VERSION "synthetic-300"

NS_ :

BS_:

BU_: Node1 Node2 Node3 Node4 Node5 Node6 Node7 Node8 Node9 Node10 Node11 Node12

VAL_TABLE_ State2 1 "On" 0 "Off" ;
VAL_TABLE_ Mode4 3 "Fault" 2 "Hold" 1 "Run" 0 "Idle" ;

BO_ 1 Msg_0: 16 Node1
 SG_ Sig_0_0 : 7|2@0+ (0.01,-40) [-40|-39.97] "" Node2
 SG_ Sig_0_1 : 5|12@0+ (0.1,-0.5) [-0.5|409] "rpm" Node2
 SG_ Sig_0_2 : 9|2@0- (0.5,0) [-1|0.5] "" Node2
 SG_ Sig_0_3 : 23|8@0+ (1,0) [0|255] "A" Node2
 SG_ Sig_0_4 : 31|8@0- (1,0) [-128|127] "" Node2
 SG_ Sig_0_5 : 39|8@0+ (1,0) [0|255] "degC" Node2

BO_ 2147549185 Msg_1: 32 Node2
 SG_ Sig_1_0 : 0|8@1- (1,0) [-128|127] "" Node3,Node4
 SG_ Sig_1_1 : 8|8@1+ (2,-0.5) [-0.5|509.5] "km/h" Node3,Node4
 SG_ Sig_1_2 : 16|1@1+ (1,0) [0|1] "" Node3,Node4
 SG_ Sig_1_3 : 17|12@1- (2,0) [-4096|4094] "km/h" Node3,Node4
 SG_ Sig_1_4 : 29|8@1+ (1,0) [0|255] "" Node3,Node4
 SG_ Sig_1_5 : 37|16@1+ (0.1,0) [0|6553.5] "A" Node3,Node4

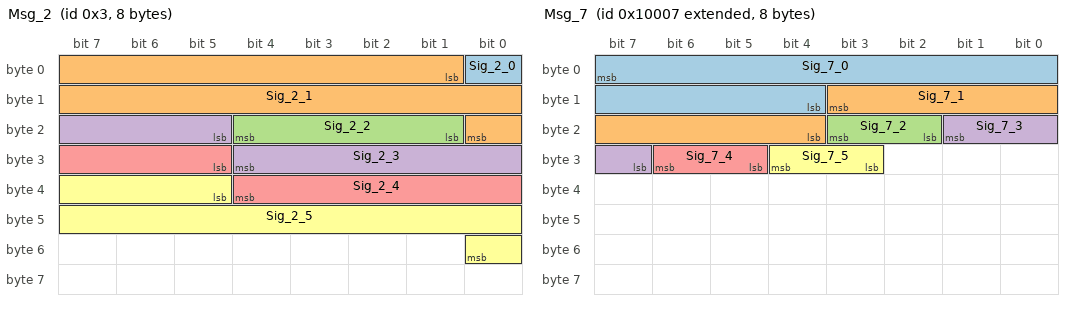
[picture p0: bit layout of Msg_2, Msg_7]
BO_ 3 Msg_2: 8 Node3
 SG_ Sig_2_0 : 0|1@1+ (1,0) [0|1] "" Node4
 SG_ Sig_2_1 : 1|16@1+ (0.25,-0.5) [-0.5|16383.25] "degC" Node4
 SG_ Sig_2_2 : 17|4@1+ (1,-40) [-40|-25] "km/h" Node4
 SG_ Sig_2_3 : 21|8@1+ (1,-40) [-40|215] "A" Node4
 SG_ Sig_2_4 : 29|8@1+ (1,-40) [-40|215] "rpm" Node4
 SG_ Sig_2_5 : 37|12@1+ (0.01,0) [0|40.95] "rpm" Node4

BO_ 4 Msg_3: 32 Node4
 SG_ Sig_3_0 : 7|16@0- (1,-40) [-32808|32727] "V" Node5
 SG_ Sig_3_1 : 23|8@0- (0.01,0) [-1.28|1.27] "" Node5
 SG_ Sig_3_2 : 31|8@0+ (0.01,0) [0|2.55] "%" Node5
 SG_ Sig_3_3 : 39|2@0+ (0.1,-40) [-40|-39.7] "" Node5
 SG_ Sig_3_4 : 37|16@0+ (0.5,-0.5) [-0.5|32767] "km/h" Node5
 SG_ Sig_3_5 : 53|2@0+ (0.25,-0.5) [-0.5|0.25] "" Node5

BO_ 5 Msg_4: 16 Node5
 SG_ Sig_4_0 : 0|12@1+ (0.25,-0.5) [-0.5|1023.25] "V" Node6,Node7
 SG_ Sig_4_1 : 12|3@1+ (0.1,0) [0|0.7] "rpm" Node6,Node7
 SG_ Sig_4_2 : 15|1@1+ (1,0) [0|1] "" Node6,Node7
 SG_ Sig_4_3 : 16|16@1- (0.5,0) [-16384|16383.5] "" Node6,Node7
 SG_ Sig_4_4 : 32|4@1+ (0.25,-0.5) [-0.5|3.25] "A" Node6,Node7
 SG_ Sig_4_5 : 36|8@1+ (0.01,0) [0|2.55] "rpm" Node6,Node7

BO_ 2147549189 Msg_5: 24 Node6
 SG_ Sig_5_0 : 0|1@1+ (1,0) [0|1] "" Node7,Node8
 SG_ Sig_5_1 : 1|16@1+ (0.1,-0.5) [-0.5|6553] "A" Node7,Node8
 SG_ Sig_5_2 : 17|2@1- (1,-40) [-42|-39] "" Node7,Node8
 SG_ Sig_5_3 : 19|8@1+ (0.5,100) [100|227.5] "" Node7,Node8
 SG_ Sig_5_4 : 27|8@1+ (2,-0.5) [-0.5|509.5] "degC" Node7,Node8
 SG_ Sig_5_5 : 35|4@1- (1,100) [92|107] "%" Node7,Node8

BO_ 7 Msg_6: 6 Node7
 SG_ Sig_6_0 : 0|8@1+ (2,0) [0|510] "km/h" Node8
 SG_ Sig_6_1 : 8|8@1+ (2,0) [0|510] "V" Node8
 SG_ Sig_6_2 : 16|16@1+ (1,0) [0|65535] "V" Node8
 SG_ Sig_6_3 : 32|2@1+ (2,0) [0|6] "" Node8
 SG_ Sig_6_4 : 34|8@1- (1,0) [-128|127] "degC" Node8
 SG_ Sig_6_5 : 42|1@1+ (1,0) [0|1] "" Node8

BO_ 2147549191 Msg_7: 8 Node8
 SG_ Sig_7_0 : 7|12@0+ (0.25,-40) [-40|983.75] "" Node9
 SG_ Sig_7_1 : 11|8@0+ (1,0) [0|255] "km/h" Node9
 SG_ Sig_7_2 : 19|2@0- (1,-40) [-42|-39] "" Node9
 SG_ Sig_7_3 : 17|3@0+ (0.01,0) [0|0.07] "V" Node9
 SG_ Sig_7_4 : 30|2@0+ (1,0) [0|3] "" Node9
 SG_ Sig_7_5 : 28|2@0+ (1,0) [0|3] "" Node9

BO_ 2147549192 Msg_8: 4 Node9
 SG_ Sig_8_0 : 7|16@0+ (0.1,100) [100|6653.5] "rpm" Node10
 SG_ Sig_8_1 : 23|4@0+ (1,0) [0|15] "km/h" Node10
 SG_ Sig_8_2 : 19|3@0+ (0.5,0) [0|3.5] "degC" Node10
 SG_ Sig_8_3 : 16|4@0+ (0.25,0) [0|3.75] "%" Node10
 SG_ Sig_8_4 : 28|5@0- (1,-0.5) [-16.5|14.5] "A" Node10

BO_ 2147549193 Msg_9: 12 Node10
 SG_ Sig_9_0 : 7|16@0+ (0.25,-0.5) [-0.5|16383.25] "rpm" Node11
 SG_ Sig_9_1 : 23|8@0+ (0.01,0) [0|2.55] "km/h" Node11
 SG_ Sig_9_2 : 31|12@0+ (1,0) [0|4095] "V" Node11
 SG_ Sig_9_3 : 35|3@0+ (2,-40) [-40|-26] "%" Node11
 SG_ Sig_9_4 : 32|12@0+ (0.1,0) [0|409.5] "" Node11
 SG_ Sig_9_5 : 52|16@0+ (0.1,100) [100|6653.5] "km/h" Node11

BO_ 11 Msg_10: 24 Node11
 SG_ Sig_10_0 : 7|1@0+ (1,0) [0|1] "" Node12
 SG_ Sig_10_1 : 6|2@0+ (1,0) [0|3] "" Node12
 SG_ Sig_10_2 : 4|8@0+ (0.5,-40) [-40|87.5] "km/h" Node12
 SG_ Sig_10_3 : 12|12@0+ (1,0) [0|4095] "degC" Node12
 SG_ Sig_10_4 : 16|1@0+ (1,0) [0|1] "" Node12
 SG_ Sig_10_5 : 31|8@0+ (0.25,100) [100|163.75] "A" Node12

BO_ 12 Msg_11: 12 Node12
 SG_ Sig_11_0 : 7|8@0+ (0.25,-40) [-40|23.75] "V" Node1,Node2
 SG_ Sig_11_1 : 15|12@0+ (0.1,-0.5) [-0.5|409] "" Node1,Node2
 SG_ Sig_11_2 : 19|4@0- (0.1,100) [99.2|100.7] "degC" Node1,Node2
 SG_ Sig_11_3 : 31|2@0+ (1,100) [100|103] "" Node1,Node2
 SG_ Sig_11_4 : 29|12@0+ (1,-40) [-40|4055] "V" Node1,Node2
 SG_ Sig_11_5 : 33|12@0+ (0.1,100) [100|509.5] "%" Node1,Node2

BO_ 13 Msg_12: 6 Node1
 SG_ Sig_12_0 : 7|16@0+ (0.1,0) [0|6553.5] "%" Node2,Node3
 SG_ Sig_12_1 : 23|16@0- (2,0) [-65536|65534] "rpm" Node2,Node3
 SG_ Sig_12_2 : 39|3@0- (1,0) [-4|3] "km/h" Node2,Node3
 SG_ Sig_12_3 : 36|13@0- (0.1,-40) [-449.6|369.5] "rpm" Node2,Node3

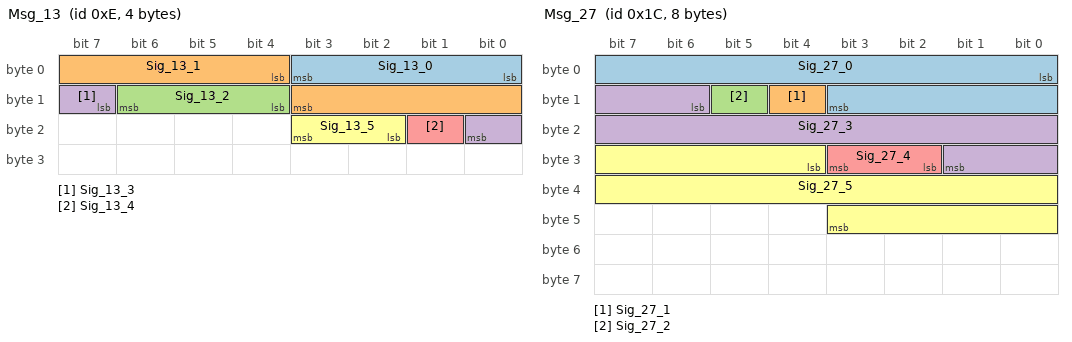
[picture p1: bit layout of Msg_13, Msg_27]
BO_ 14 Msg_13: 4 Node2
 SG_ Sig_13_0 : 0|4@1- (1,100) [92|107] "%" Node3,Node4
 SG_ Sig_13_1 : 4|8@1- (1,-0.5) [-128.5|126.5] "degC" Node3,Node4
 SG_ Sig_13_2 : 12|3@1+ (1,100) [100|107] "rpm" Node3,Node4
 SG_ Sig_13_3 : 15|2@1+ (0.1,0) [0|0.3] "" Node3,Node4
 SG_ Sig_13_4 : 17|1@1+ (1,0) [0|1] "" Node3,Node4
 SG_ Sig_13_5 : 18|2@1+ (0.1,-40) [-40|-39.7] "" Node3,Node4

BO_ 15 Msg_14: 2 Node3
 SG_ Sig_14_0 : 0|4@1+ (2,100) [100|130] "%" Node4,Node5
 SG_ Sig_14_1 : 4|2@1+ (0.01,-40) [-40|-39.97] "" Node4,Node5
 SG_ Sig_14_2 : 6|3@1+ (1,0) [0|7] "" Node4,Node5
 SG_ Sig_14_3 : 9|4@1- (0.25,0) [-2|1.75] "" Node4,Node5
 SG_ Sig_14_4 : 13|3@1+ (0.1,0) [0|0.7] "km/h" Node4,Node5

BO_ 16 Msg_15: 24 Node4
 SG_ Sig_15_0 : 7|1@0+ (1,0) [0|1] "" Node5
 SG_ Sig_15_1 : 6|1@0+ (1,0) [0|1] "" Node5
 SG_ Sig_15_2 : 5|2@0+ (0.01,0) [0|0.03] "" Node5
 SG_ Sig_15_3 : 3|4@0+ (0.01,-40) [-40|-39.85] "" Node5
 SG_ Sig_15_4 : 15|3@0+ (0.01,-40) [-40|-39.93] "" Node5
 SG_ Sig_15_5 : 12|16@0+ (0.25,-0.5) [-0.5|16383.25] "rpm" Node5

BO_ 17 Msg_16: 8 Node5
 SG_ Sig_16_0 : 0|4@1+ (0.5,0) [0|7.5] "A" Node6
 SG_ Sig_16_1 : 4|4@1- (1,0) [-8|7] "degC" Node6
 SG_ Sig_16_2 : 8|8@1- (0.5,-40) [-104|23.5] "%" Node6
 SG_ Sig_16_3 : 16|2@1- (2,0) [-4|2] "" Node6
 SG_ Sig_16_4 : 18|2@1+ (0.1,0) [0|0.3] "" Node6
 SG_ Sig_16_5 : 20|12@1+ (0.01,0) [0|40.95] "" Node6

BO_ 18 Msg_17: 8 Node6
 SG_ Sig_17_0 : 7|2@0+ (0.5,-40) [-40|-38.5] "" Node7
 SG_ Sig_17_1 : 5|4@0+ (0.25,0) [0|3.75] "" Node7
 SG_ Sig_17_2 : 1|8@0+ (0.01,0) [0|2.55] "km/h" Node7
 SG_ Sig_17_3 : 9|2@0+ (1,0) [0|3] "" Node7
 SG_ Sig_17_4 : 23|16@0+ (0.1,-0.5) [-0.5|6553] "rpm" Node7
 SG_ Sig_17_5 : 39|16@0- (0.25,0) [-8192|8191.75] "degC" Node7

BO_ 2147549202 Msg_18: 16 Node7
 SG_ Sig_18_0 : 0|1@1+ (1,0) [0|1] "" Node8,Node9
 SG_ Sig_18_1 : 1|1@1+ (1,0) [0|1] "" Node8,Node9
 SG_ Sig_18_2 : 2|8@1- (0.25,100) [68|131.75] "A" Node8,Node9
 SG_ Sig_18_3 : 10|12@1+ (2,-0.5) [-0.5|8189.5] "%" Node8,Node9
 SG_ Sig_18_4 : 22|8@1+ (2,0) [0|510] "V" Node8,Node9
 SG_ Sig_18_5 : 30|2@1- (0.1,0) [-0.2|0.1] "" Node8,Node9

BO_ 20 Msg_19: 8 Node8
 SG_ Sig_19_0 : 7|8@0+ (1,-40) [-40|215] "degC" Node9,Node10
 SG_ Sig_19_1 : 15|8@0+ (2,0) [0|510] "%" Node9,Node10
 SG_ Sig_19_2 : 23|4@0+ (0.25,100) [100|103.75] "A" Node9,Node10
 SG_ Sig_19_3 : 19|1@0+ (1,0) [0|1] "" Node9,Node10
 SG_ Sig_19_4 : 18|8@0- (2,100) [-156|354] "%" Node9,Node10
 SG_ Sig_19_5 : 26|2@0+ (0.5,0) [0|1.5] "" Node9,Node10

BO_ 21 Msg_20: 12 Node9
 SG_ Sig_20_0 : 7|4@0+ (0.25,100) [100|103.75] "degC" Node10
 SG_ Sig_20_1 : 3|8@0+ (0.01,0) [0|2.55] "A" Node10
 SG_ Sig_20_2 : 11|8@0+ (0.5,-0.5) [-0.5|127] "rpm" Node10
 SG_ Sig_20_3 : 19|2@0+ (0.01,100) [100|100.03] "" Node10
 SG_ Sig_20_4 : 17|4@0- (0.5,100) [96|103.5] "degC" Node10
 SG_ Sig_20_5 : 29|12@0+ (2,-0.5) [-0.5|8189.5] "A" Node10

BO_ 22 Msg_21: 32 Node10
 SG_ Sig_21_0 : 7|8@0+ (0.01,0) [0|2.55] "" Node11
 SG_ Sig_21_1 : 15|3@0+ (0.1,0) [0|0.7] "degC" Node11
 SG_ Sig_21_2 : 12|12@0+ (0.1,-40) [-40|369.5] "km/h" Node11
 SG_ Sig_21_3 : 16|8@0+ (0.5,100) [100|227.5] "V" Node11
 SG_ Sig_21_4 : 24|8@0+ (1,0) [0|255] "%" Node11
 SG_ Sig_21_5 : 32|3@0+ (0.01,-40) [-40|-39.93] "V" Node11

BO_ 23 Msg_22: 32 Node11
 SG_ Sig_22_0 : 0|16@1+ (0.1,0) [0|6553.5] "" Node12
 SG_ Sig_22_1 : 16|16@1+ (2,0) [0|131070] "%" Node12
 SG_ Sig_22_2 : 32|8@1+ (0.25,0) [0|63.75] "" Node12
 SG_ Sig_22_3 : 40|2@1+ (2,0) [0|6] "" Node12
 SG_ Sig_22_4 : 42|3@1- (0.01,-0.5) [-0.54|-0.47] "A" Node12
 SG_ Sig_22_5 : 45|1@1+ (1,0) [0|1] "" Node12

BO_ 2147549207 Msg_23: 4 Node12
 SG_ Sig_23_0 : 7|16@0+ (0.01,0) [0|655.35] "km/h" Node1
 SG_ Sig_23_1 : 23|4@0+ (1,0) [0|15] "km/h" Node1
 SG_ Sig_23_2 : 19|12@0- (0.1,0) [-204.8|204.7] "%" Node1

BO_ 25 Msg_24: 8 Node1
 SG_ Sig_24_0 : 0|1@1+ (1,0) [0|1] "" Node2,Node3
 SG_ Sig_24_1 : 1|3@1- (0.5,0) [-2|1.5] "V" Node2,Node3
 SG_ Sig_24_2 : 4|3@1+ (0.5,-40) [-40|-36.5] "A" Node2,Node3
 SG_ Sig_24_3 : 7|8@1- (2,-0.5) [-256.5|253.5] "A" Node2,Node3
 SG_ Sig_24_4 : 15|1@1+ (1,0) [0|1] "" Node2,Node3
 SG_ Sig_24_5 : 16|8@1+ (0.1,0) [0|25.5] "A" Node2,Node3

BO_ 26 Msg_25: 64 Node2
 SG_ Sig_25_0 : 7|3@0+ (0.25,-40) [-40|-38.25] "km/h" Node3
 SG_ Sig_25_1 : 4|12@0- (1,0) [-2048|2047] "V" Node3
 SG_ Sig_25_2 : 8|16@0+ (0.01,0) [0|655.35] "%" Node3
 SG_ Sig_25_3 : 24|16@0+ (1,-40) [-40|65495] "degC" Node3
 SG_ Sig_25_4 : 40|1@0+ (1,0) [0|1] "" Node3
 SG_ Sig_25_5 : 55|2@0- (0.25,0) [-0.5|0.25] "" Node3

BO_ 27 Msg_26: 16 Node3
 SG_ Sig_26_sel M : 0|8@1- (0.25,-0.5) [-32.5|31.25] "km/h" Node4
 SG_ Sig_26_a0 m0 : 8|12@1+ (0.1,-40) [-40|369.5] "" Node4
 SG_ Sig_26_a1 m0 : 20|12@1+ (0.25,-0.5) [-0.5|1023.25] "A" Node4
 SG_ Sig_26_b0 m1 : 8|8@1+ (0.5,-40) [-40|87.5] "A" Node4
 SG_ Sig_26_b1 m1 : 16|12@1- (0.5,0) [-1024|1023.5] "A" Node4
 SG_ Sig_26_c0 : 40|4@1- (1,-40) [-48|-33] "" Node4
 SG_ Sig_26_c1 : 44|8@1- (1,0) [-128|127] "rpm" Node4

BO_ 28 Msg_27: 8 Node4
 SG_ Sig_27_0 : 0|12@1+ (0.25,0) [0|1023.75] "A" Node5
 SG_ Sig_27_1 : 12|1@1+ (1,0) [0|1] "" Node5
 SG_ Sig_27_2 : 13|1@1+ (1,0) [0|1] "" Node5
 SG_ Sig_27_3 : 14|12@1+ (0.5,0) [0|2047.5] "A" Node5
 SG_ Sig_27_4 : 26|2@1+ (2,-0.5) [-0.5|5.5] "" Node5
 SG_ Sig_27_5 : 28|16@1+ (1,0) [0|65535] "km/h" Node5

BO_ 29 Msg_28: 24 Node5
 SG_ Sig_28_0 : 7|16@0+ (0.01,-0.5) [-0.5|654.85] "" Node6,Node7
 SG_ Sig_28_1 : 23|2@0+ (1,0) [0|3] "" Node6,Node7
 SG_ Sig_28_2 : 21|3@0+ (0.5,0) [0|3.5] "%" Node6,Node7
 SG_ Sig_28_3 : 18|3@0+ (0.5,0) [0|3.5] "rpm" Node6,Node7
 SG_ Sig_28_4 : 31|2@0+ (0.5,-0.5) [-0.5|1] "" Node6,Node7
 SG_ Sig_28_5 : 29|1@0+ (1,0) [0|1] "" Node6,Node7

BO_ 30 Msg_29: 12 Node6
 SG_ Sig_29_0 : 7|16@0+ (0.5,0) [0|32767.5] "rpm" Node7
 SG_ Sig_29_1 : 23|8@0+ (0.01,0) [0|2.55] "rpm" Node7
 SG_ Sig_29_2 : 31|2@0+ (0.25,0) [0|0.75] "" Node7
 SG_ Sig_29_3 : 29|8@0- (1,0) [-128|127] "rpm" Node7
 SG_ Sig_29_4 : 37|4@0+ (1,100) [100|115] "" Node7
 SG_ Sig_29_5 : 33|12@0+ (0.1,0) [0|409.5] "km/h" Node7

BO_ 31 Msg_30: 6 Node7
 SG_ Sig_30_0 : 0|2@1+ (0.01,0) [0|0.03] "" Node8,Node9
 SG_ Sig_30_1 : 2|4@1+ (0.5,-40) [-40|-32.5] "V" Node8,Node9
 SG_ Sig_30_2 : 6|2@1+ (0.25,0) [0|0.75] "" Node8,Node9
 SG_ Sig_30_3 : 8|8@1+ (0.25,0) [0|63.75] "rpm" Node8,Node9
 SG_ Sig_30_4 : 16|8@1- (0.01,0) [-1.28|1.27] "km/h" Node8,Node9
 SG_ Sig_30_5 : 24|8@1+ (2,0) [0|510] "rpm" Node8,Node9

BO_ 32 Msg_31: 4 Node8
 SG_ Sig_31_0 : 7|3@0+ (0.01,100) [100|100.07] "km/h" Node9,Node10
 SG_ Sig_31_1 : 4|16@0+ (0.25,-0.5) [-0.5|16383.25] "rpm" Node9,Node10
 SG_ Sig_31_2 : 20|12@0+ (0.25,-40) [-40|983.75] "" Node9,Node10
 SG_ Sig_31_3 : 24|1@0+ (1,0) [0|1] "" Node9,Node10

BO_ 33 Msg_32: 32 Node9
 SG_ Sig_32_0 : 0|4@1- (1,-0.5) [-8.5|6.5] "km/h" Node10
 SG_ Sig_32_1 : 4|2@1+ (0.01,-40) [-40|-39.97] "" Node10
 SG_ Sig_32_2 : 6|12@1+ (1,100) [100|4195] "V" Node10
 SG_ Sig_32_3 : 18|1@1+ (1,0) [0|1] "" Node10
 SG_ Sig_32_4 : 19|1@1+ (1,0) [0|1] "" Node10
 SG_ Sig_32_5 : 20|8@1+ (0.5,0) [0|127.5] "rpm" Node10

BO_ 34 Msg_33: 8 Node10
 SG_ Sig_33_0 : 7|16@0+ (2,0) [0|131070] "V" Node11
 SG_ Sig_33_1 : 23|3@0- (0.5,-0.5) [-2.5|1] "A" Node11
 SG_ Sig_33_2 : 20|8@0- (0.01,0) [-1.28|1.27] "A" Node11
 SG_ Sig_33_3 : 28|16@0+ (0.5,0) [0|32767.5] "A" Node11
 SG_ Sig_33_4 : 44|2@0+ (2,0) [0|6] "" Node11
 SG_ Sig_33_5 : 42|8@0- (2,0) [-256|254] "degC" Node11

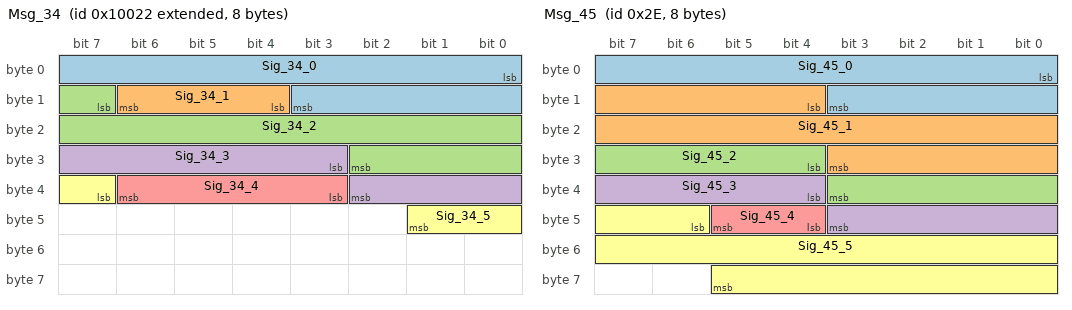
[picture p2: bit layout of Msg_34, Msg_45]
BO_ 2147549218 Msg_34: 8 Node11
 SG_ Sig_34_0 : 0|12@1- (1,-40) [-2088|2007] "degC" Node12,Node1
 SG_ Sig_34_1 : 12|3@1+ (0.01,-40) [-40|-39.93] "%" Node12,Node1
 SG_ Sig_34_2 : 15|12@1+ (0.01,0) [0|40.95] "A" Node12,Node1
 SG_ Sig_34_3 : 27|8@1+ (2,0) [0|510] "A" Node12,Node1
 SG_ Sig_34_4 : 35|4@1+ (2,-40) [-40|-10] "%" Node12,Node1
 SG_ Sig_34_5 : 39|3@1+ (0.1,-40) [-40|-39.3] "%" Node12,Node1

BO_ 36 Msg_35: 8 Node12
 SG_ Sig_35_0 : 7|8@0+ (1,100) [100|355] "degC" Node1
 SG_ Sig_35_1 : 15|8@0- (0.1,0) [-12.8|12.7] "degC" Node1
 SG_ Sig_35_2 : 23|3@0+ (2,0) [0|14] "" Node1
 SG_ Sig_35_3 : 20|8@0+ (0.25,-0.5) [-0.5|63.25] "A" Node1
 SG_ Sig_35_4 : 28|12@0+ (1,0) [0|4095] "A" Node1
 SG_ Sig_35_5 : 32|12@0- (0.25,0) [-512|511.75] "A" Node1

BO_ 37 Msg_36: 64 Node1
 SG_ Sig_36_0 : 7|8@0+ (1,0) [0|255] "A" Node2
 SG_ Sig_36_1 : 15|8@0+ (2,-0.5) [-0.5|509.5] "A" Node2
 SG_ Sig_36_2 : 23|1@0+ (1,0) [0|1] "" Node2
 SG_ Sig_36_3 : 22|8@0+ (2,0) [0|510] "" Node2
 SG_ Sig_36_4 : 30|2@0+ (1,0) [0|3] "" Node2
 SG_ Sig_36_5 : 28|12@0+ (0.1,0) [0|409.5] "" Node2

BO_ 38 Msg_37: 24 Node2
 SG_ Sig_37_0 : 0|12@1+ (0.1,0) [0|409.5] "A" Node3,Node4
 SG_ Sig_37_1 : 12|4@1- (0.5,100) [96|103.5] "%" Node3,Node4
 SG_ Sig_37_2 : 16|2@1- (1,0) [-2|1] "" Node3,Node4
 SG_ Sig_37_3 : 18|2@1- (0.1,0) [-0.2|0.1] "" Node3,Node4
 SG_ Sig_37_4 : 20|1@1+ (1,0) [0|1] "" Node3,Node4
 SG_ Sig_37_5 : 21|3@1- (1,0) [-4|3] "degC" Node3,Node4

BO_ 39 Msg_38: 24 Node3
 SG_ Sig_38_sel M : 0|8@1- (0.1,100) [87.2|112.7] "" Node4
 SG_ Sig_38_a0 m0 : 8|1@1+ (1,0) [0|1] "" Node4
 SG_ Sig_38_a1 m0 : 9|12@1+ (1,0) [0|4095] "rpm" Node4
 SG_ Sig_38_b0 m1 : 8|3@1+ (0.1,0) [0|0.7] "rpm" Node4
 SG_ Sig_38_b1 m1 : 11|4@1- (2,0) [-16|14] "rpm" Node4
 SG_ Sig_38_c0 : 40|2@1+ (0.5,-40) [-40|-38.5] "" Node4
 SG_ Sig_38_c1 : 42|2@1+ (0.01,0) [0|0.03] "" Node4

BO_ 40 Msg_39: 4 Node4
 SG_ Sig_39_0 : 7|8@0+ (2,-40) [-40|470] "km/h" Node5
 SG_ Sig_39_1 : 15|2@0+ (0.01,-40) [-40|-39.97] "" Node5
 SG_ Sig_39_2 : 13|2@0+ (0.25,100) [100|100.75] "" Node5
 SG_ Sig_39_3 : 11|8@0+ (2,0) [0|510] "A" Node5
 SG_ Sig_39_4 : 19|2@0+ (0.25,0) [0|0.75] "" Node5
 SG_ Sig_39_5 : 17|10@0+ (0.01,0) [0|10.23] "km/h" Node5

BO_ 41 Msg_40: 16 Node5
 SG_ Sig_40_0 : 0|3@1+ (1,-40) [-40|-33] "degC" Node6
 SG_ Sig_40_1 : 3|12@1+ (0.25,0) [0|1023.75] "%" Node6
 SG_ Sig_40_2 : 15|8@1+ (1,100) [100|355] "A" Node6
 SG_ Sig_40_3 : 23|1@1+ (1,0) [0|1] "" Node6
 SG_ Sig_40_4 : 24|4@1+ (2,0) [0|30] "V" Node6
 SG_ Sig_40_5 : 28|3@1+ (0.5,0) [0|3.5] "degC" Node6

BO_ 2147549225 Msg_41: 32 Node6
 SG_ Sig_41_0 : 7|4@0- (0.5,0) [-4|3.5] "km/h" Node7,Node8
 SG_ Sig_41_1 : 3|1@0+ (1,0) [0|1] "" Node7,Node8
 SG_ Sig_41_2 : 2|3@0+ (1,0) [0|7] "V" Node7,Node8
 SG_ Sig_41_3 : 15|8@0- (1,0) [-128|127] "rpm" Node7,Node8
 SG_ Sig_41_4 : 23|4@0+ (0.1,0) [0|1.5] "%" Node7,Node8
 SG_ Sig_41_5 : 19|12@0+ (0.01,0) [0|40.95] "rpm" Node7,Node8

BO_ 43 Msg_42: 6 Node7
 SG_ Sig_42_0 : 0|16@1+ (0.1,0) [0|6553.5] "km/h" Node8
 SG_ Sig_42_1 : 16|16@1- (0.5,100) [-16284|16483.5] "" Node8
 SG_ Sig_42_2 : 32|12@1+ (0.25,0) [0|1023.75] "rpm" Node8
 SG_ Sig_42_3 : 44|4@1- (0.01,-0.5) [-0.58|-0.43] "rpm" Node8

BO_ 44 Msg_43: 64 Node8
 SG_ Sig_43_0 : 0|3@1- (0.5,0) [-2|1.5] "rpm" Node9
 SG_ Sig_43_1 : 3|8@1+ (1,0) [0|255] "" Node9
 SG_ Sig_43_2 : 11|4@1- (2,-0.5) [-16.5|13.5] "degC" Node9
 SG_ Sig_43_3 : 15|16@1+ (2,0) [0|131070] "V" Node9
 SG_ Sig_43_4 : 31|8@1+ (0.25,0) [0|63.75] "km/h" Node9
 SG_ Sig_43_5 : 39|4@1- (1,-0.5) [-8.5|6.5] "km/h" Node9

BO_ 2147549228 Msg_44: 64 Node9
 SG_ Sig_44_0 : 7|8@0+ (1,0) [0|255] "V" Node10
 SG_ Sig_44_1 : 15|12@0+ (1,0) [0|4095] "A" Node10
 SG_ Sig_44_2 : 19|8@0+ (0.25,0) [0|63.75] "degC" Node10
 SG_ Sig_44_3 : 27|12@0+ (0.01,-40) [-40|0.95] "degC" Node10
 SG_ Sig_44_4 : 47|12@0- (1,-40) [-2088|2007] "A" Node10
 SG_ Sig_44_5 : 51|2@0+ (0.5,-40) [-40|-38.5] "" Node10

BO_ 46 Msg_45: 8 Node10
 SG_ Sig_45_0 : 0|12@1+ (0.5,0) [0|2047.5] "degC" Node11
 SG_ Sig_45_1 : 12|16@1+ (0.01,0) [0|655.35] "" Node11
 SG_ Sig_45_2 : 28|8@1+ (1,-40) [-40|215] "%" Node11
 SG_ Sig_45_3 : 36|8@1+ (1,-40) [-40|215] "rpm" Node11
 SG_ Sig_45_4 : 44|2@1+ (0.01,0) [0|0.03] "" Node11
 SG_ Sig_45_5 : 46|16@1+ (2,0) [0|131070] "degC" Node11

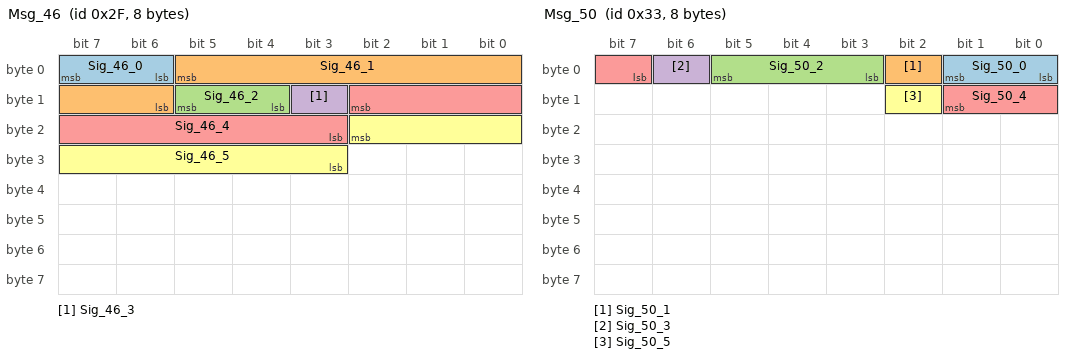
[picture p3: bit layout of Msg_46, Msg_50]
BO_ 47 Msg_46: 8 Node11
 SG_ Sig_46_0 : 7|2@0- (0.5,0) [-1|0.5] "" Node12
 SG_ Sig_46_1 : 5|8@0+ (0.01,-40) [-40|-37.45] "A" Node12
 SG_ Sig_46_2 : 13|2@0+ (0.5,0) [0|1.5] "" Node12
 SG_ Sig_46_3 : 11|1@0+ (1,0) [0|1] "" Node12
 SG_ Sig_46_4 : 10|8@0+ (0.1,0) [0|25.5] "degC" Node12
 SG_ Sig_46_5 : 18|8@0- (0.1,-0.5) [-13.3|12.2] "km/h" Node12

BO_ 2147549231 Msg_47: 12 Node12
 SG_ Sig_47_0 : 7|2@0- (1,0) [-2|1] "" Node1,Node2
 SG_ Sig_47_1 : 5|4@0+ (1,-0.5) [-0.5|14.5] "A" Node1,Node2
 SG_ Sig_47_2 : 1|12@0+ (1,100) [100|4195] "%" Node1,Node2
 SG_ Sig_47_3 : 21|16@0+ (0.1,100) [100|6653.5] "" Node1,Node2
 SG_ Sig_47_4 : 37|16@0+ (1,0) [0|65535] "rpm" Node1,Node2
 SG_ Sig_47_5 : 53|2@0+ (2,0) [0|6] "" Node1,Node2

BO_ 49 Msg_48: 16 Node1
 SG_ Sig_48_sel M : 0|8@1+ (0.01,0) [0|2.55] "rpm" Node2
 SG_ Sig_48_a0 m0 : 8|8@1+ (0.01,100) [100|102.55] "V" Node2
 SG_ Sig_48_a1 m0 : 16|2@1+ (0.5,100) [100|101.5] "" Node2
 SG_ Sig_48_b0 m1 : 8|12@1+ (0.01,0) [0|40.95] "%" Node2
 SG_ Sig_48_b1 m1 : 20|8@1+ (1,0) [0|255] "" Node2
 SG_ Sig_48_c0 : 40|3@1+ (0.01,-40) [-40|-39.93] "%" Node2
 SG_ Sig_48_c1 : 43|2@1- (0.01,0) [-0.02|0.01] "" Node2

BO_ 50 Msg_49: 8 Node2
 SG_ Sig_49_0 : 0|8@1- (0.25,100) [68|131.75] "A" Node3,Node4
 SG_ Sig_49_1 : 8|8@1+ (1,100) [100|355] "V" Node3,Node4
 SG_ Sig_49_2 : 16|1@1+ (1,0) [0|1] "" Node3,Node4
 SG_ Sig_49_3 : 17|16@1+ (1,-0.5) [-0.5|65534.5] "%" Node3,Node4
 SG_ Sig_49_4 : 33|12@1+ (0.01,100) [100|140.95] "degC" Node3,Node4
 SG_ Sig_49_5 : 45|8@1+ (0.01,0) [0|2.55] "degC" Node3,Node4

BO_ 51 Msg_50: 8 Node3
 SG_ Sig_50_0 : 0|2@1+ (0.1,0) [0|0.3] "" Node4
 SG_ Sig_50_1 : 2|1@1+ (1,0) [0|1] "" Node4
 SG_ Sig_50_2 : 3|3@1+ (0.25,-0.5) [-0.5|1.25] "%" Node4
 SG_ Sig_50_3 : 6|1@1+ (1,0) [0|1] "" Node4
 SG_ Sig_50_4 : 7|3@1+ (2,-40) [-40|-26] "rpm" Node4
 SG_ Sig_50_5 : 10|1@1+ (1,0) [0|1] "" Node4

BO_ 52 Msg_51: 32 Node4
 SG_ Sig_51_0 : 0|8@1- (0.25,-40) [-72|-8.25] "degC" Node5
 SG_ Sig_51_1 : 8|12@1- (0.01,0) [-20.48|20.47] "" Node5
 SG_ Sig_51_2 : 20|2@1+ (2,0) [0|6] "" Node5
 SG_ Sig_51_3 : 22|16@1+ (0.01,0) [0|655.35] "km/h" Node5
 SG_ Sig_51_4 : 38|4@1+ (0.5,-40) [-40|-32.5] "km/h" Node5
 SG_ Sig_51_5 : 42|16@1- (0.5,100) [-16284|16483.5] "" Node5

BO_ 53 Msg_52: 12 Node5
 SG_ Sig_52_0 : 0|8@1+ (0.1,100) [100|125.5] "rpm" Node6,Node7
 SG_ Sig_52_1 : 8|4@1+ (2,-40) [-40|-10] "" Node6,Node7
 SG_ Sig_52_2 : 12|2@1- (0.5,-0.5) [-1.5|0] "" Node6,Node7
 SG_ Sig_52_3 : 14|12@1+ (1,-0.5) [-0.5|4094.5] "A" Node6,Node7
 SG_ Sig_52_4 : 26|8@1+ (0.5,0) [0|127.5] "rpm" Node6,Node7
 SG_ Sig_52_5 : 34|16@1+ (2,0) [0|131070] "" Node6,Node7

BO_ 2147549237 Msg_53: 8 Node6
 SG_ Sig_53_0 : 0|12@1+ (0.1,100) [100|509.5] "rpm" Node7,Node8
 SG_ Sig_53_1 : 12|4@1+ (2,-0.5) [-0.5|29.5] "V" Node7,Node8
 SG_ Sig_53_2 : 16|8@1+ (1,0) [0|255] "" Node7,Node8
 SG_ Sig_53_3 : 24|2@1+ (0.25,-40) [-40|-39.25] "" Node7,Node8
 SG_ Sig_53_4 : 26|3@1+ (0.25,0) [0|1.75] "rpm" Node7,Node8
 SG_ Sig_53_5 : 29|16@1+ (1,0) [0|65535] "rpm" Node7,Node8

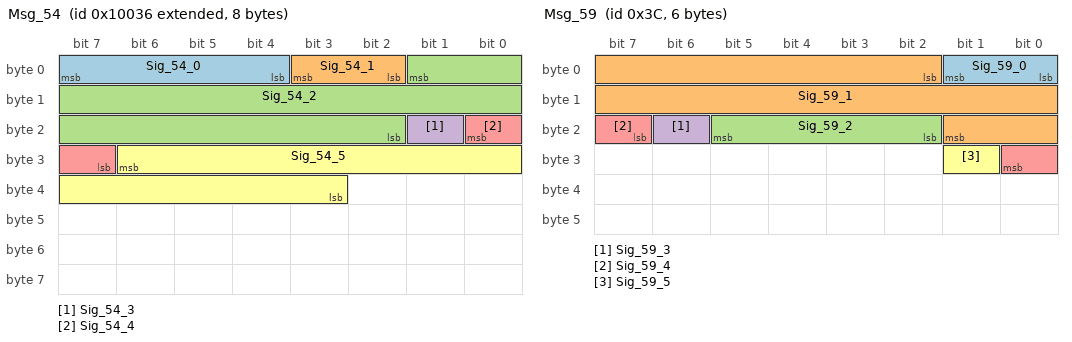
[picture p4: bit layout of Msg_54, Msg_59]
BO_ 2147549238 Msg_54: 8 Node7
 SG_ Sig_54_0 : 7|4@0+ (0.5,100) [100|107.5] "%" Node8
 SG_ Sig_54_1 : 3|2@0- (1,100) [98|101] "" Node8
 SG_ Sig_54_2 : 1|16@0+ (0.25,-0.5) [-0.5|16383.25] "km/h" Node8
 SG_ Sig_54_3 : 17|1@0+ (1,0) [0|1] "" Node8
 SG_ Sig_54_4 : 16|2@0+ (0.1,-0.5) [-0.5|-0.2] "" Node8
 SG_ Sig_54_5 : 30|12@0+ (2,-0.5) [-0.5|8189.5] "" Node8

BO_ 56 Msg_55: 32 Node8
 SG_ Sig_55_0 : 0|3@1+ (0.5,-40) [-40|-36.5] "" Node9,Node10
 SG_ Sig_55_1 : 3|12@1+ (0.01,100) [100|140.95] "A" Node9,Node10
 SG_ Sig_55_2 : 15|8@1- (1,100) [-28|227] "%" Node9,Node10
 SG_ Sig_55_3 : 23|1@1+ (1,0) [0|1] "" Node9,Node10
 SG_ Sig_55_4 : 24|2@1+ (1,100) [100|103] "" Node9,Node10
 SG_ Sig_55_5 : 26|8@1+ (0.01,0) [0|2.55] "" Node9,Node10

BO_ 57 Msg_56: 64 Node9
 SG_ Sig_56_sel M : 0|8@1- (1,0) [-128|127] "A" Node10,Node11
 SG_ Sig_56_a0 m0 : 8|8@1- (2,0) [-256|254] "V" Node10,Node11
 SG_ Sig_56_a1 m0 : 16|8@1+ (0.25,-0.5) [-0.5|63.25] "" Node10,Node11
 SG_ Sig_56_b0 m1 : 8|16@1+ (0.1,0) [0|6553.5] "km/h" Node10,Node11
 SG_ Sig_56_b1 m1 : 24|1@1+ (1,0) [0|1] "" Node10,Node11
 SG_ Sig_56_c0 : 40|2@1+ (0.1,-40) [-40|-39.7] "" Node10,Node11
 SG_ Sig_56_c1 : 42|4@1- (2,0) [-16|14] "A" Node10,Node11

BO_ 58 Msg_57: 16 Node10
 SG_ Sig_57_0 : 7|3@0+ (2,-0.5) [-0.5|13.5] "%" Node11,Node12
 SG_ Sig_57_1 : 4|4@0- (0.1,0) [-0.8|0.7] "degC" Node11,Node12
 SG_ Sig_57_2 : 0|3@0+ (0.25,-40) [-40|-38.25] "rpm" Node11,Node12
 SG_ Sig_57_3 : 13|16@0+ (0.1,-0.5) [-0.5|6553] "km/h" Node11,Node12
 SG_ Sig_57_4 : 29|4@0+ (0.1,0) [0|1.5] "km/h" Node11,Node12
 SG_ Sig_57_5 : 25|2@0- (1,-40) [-42|-39] "" Node11,Node12

BO_ 59 Msg_58: 4 Node11
 SG_ Sig_58_0 : 0|8@1- (0.25,0) [-32|31.75] "V" Node12
 SG_ Sig_58_1 : 8|12@1+ (0.5,0) [0|2047.5] "" Node12
 SG_ Sig_58_2 : 20|12@1- (1,-0.5) [-2048.5|2046.5] "" Node12

BO_ 60 Msg_59: 6 Node12
 SG_ Sig_59_0 : 0|2@1+ (0.01,0) [0|0.03] "" Node1,Node2
 SG_ Sig_59_1 : 2|16@1+ (1,0) [0|65535] "A" Node1,Node2
 SG_ Sig_59_2 : 18|4@1- (0.1,-40) [-40.8|-39.3] "%" Node1,Node2
 SG_ Sig_59_3 : 22|1@1+ (1,0) [0|1] "" Node1,Node2
 SG_ Sig_59_4 : 23|2@1+ (2,0) [0|6] "" Node1,Node2
 SG_ Sig_59_5 : 25|1@1+ (1,0) [0|1] "" Node1,Node2

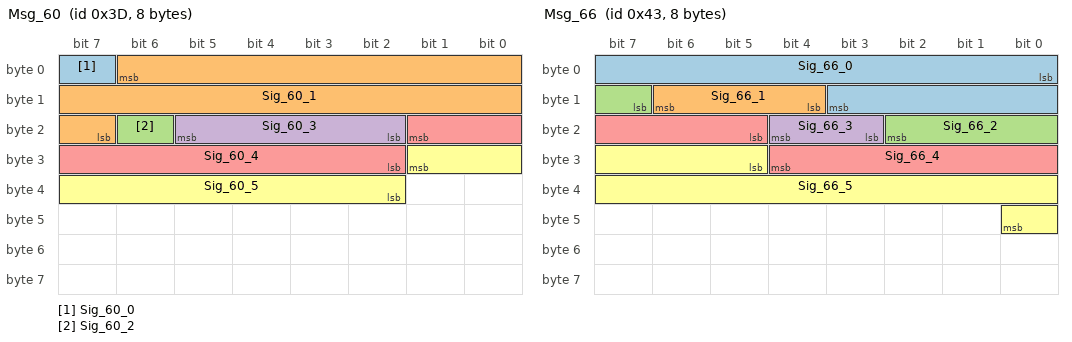
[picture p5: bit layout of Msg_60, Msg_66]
BO_ 61 Msg_60: 8 Node1
 SG_ Sig_60_0 : 7|1@0+ (1,0) [0|1] "" Node2
 SG_ Sig_60_1 : 6|16@0+ (0.25,0) [0|16383.75] "A" Node2
 SG_ Sig_60_2 : 22|1@0+ (1,0) [0|1] "" Node2
 SG_ Sig_60_3 : 21|4@0+ (0.25,0) [0|3.75] "km/h" Node2
 SG_ Sig_60_4 : 17|8@0+ (1,-40) [-40|215] "%" Node2
 SG_ Sig_60_5 : 25|8@0+ (1,0) [0|255] "" Node2

BO_ 62 Msg_61: 8 Node2
 SG_ Sig_61_0 : 0|12@1+ (2,-0.5) [-0.5|8189.5] "V" Node3
 SG_ Sig_61_1 : 12|3@1- (0.01,100) [99.96|100.03] "degC" Node3
 SG_ Sig_61_2 : 15|16@1+ (2,100) [100|131170] "km/h" Node3
 SG_ Sig_61_3 : 31|2@1+ (0.25,100) [100|100.75] "" Node3
 SG_ Sig_61_4 : 33|12@1+ (1,0) [0|4095] "V" Node3
 SG_ Sig_61_5 : 45|16@1- (0.5,0) [-16384|16383.5] "" Node3

BO_ 63 Msg_62: 24 Node3
 SG_ Sig_62_0 : 0|16@1+ (0.5,0) [0|32767.5] "V" Node4
 SG_ Sig_62_1 : 16|16@1+ (0.5,0) [0|32767.5] "%" Node4
 SG_ Sig_62_2 : 32|12@1+ (1,-0.5) [-0.5|4094.5] "A" Node4
 SG_ Sig_62_3 : 44|12@1+ (2,100) [100|8290] "" Node4
 SG_ Sig_62_4 : 56|1@1+ (1,0) [0|1] "" Node4
 SG_ Sig_62_5 : 57|3@1- (0.25,0) [-1|0.75] "A" Node4

BO_ 64 Msg_63: 64 Node4
 SG_ Sig_63_0 : 7|4@0- (1,-0.5) [-8.5|6.5] "V" Node5
 SG_ Sig_63_1 : 3|2@0+ (1,0) [0|3] "" Node5
 SG_ Sig_63_2 : 1|4@0- (0.1,100) [99.2|100.7] "V" Node5
 SG_ Sig_63_3 : 13|8@0- (1,100) [-28|227] "degC" Node5
 SG_ Sig_63_4 : 21|2@0- (1,-0.5) [-2.5|0.5] "" Node5
 SG_ Sig_63_5 : 19|8@0+ (0.25,100) [100|163.75] "rpm" Node5

BO_ 65 Msg_64: 8 Node5
 SG_ Sig_64_0 : 0|12@1+ (1,-0.5) [-0.5|4094.5] "km/h" Node6
 SG_ Sig_64_1 : 12|12@1+ (0.1,0) [0|409.5] "" Node6
 SG_ Sig_64_2 : 24|16@1+ (0.1,0) [0|6553.5] "" Node6
 SG_ Sig_64_3 : 40|3@1+ (1,-0.5) [-0.5|6.5] "rpm" Node6
 SG_ Sig_64_4 : 43|4@1+ (0.1,-40) [-40|-38.5] "V" Node6
 SG_ Sig_64_5 : 47|16@1- (0.25,0) [-8192|8191.75] "rpm" Node6

BO_ 2147549249 Msg_65: 8 Node6
 SG_ Sig_65_0 : 0|8@1+ (0.1,0) [0|25.5] "%" Node7
 SG_ Sig_65_1 : 8|12@1+ (0.25,0) [0|1023.75] "degC" Node7
 SG_ Sig_65_2 : 20|2@1- (0.01,-40) [-40.02|-39.99] "" Node7
 SG_ Sig_65_3 : 22|2@1+ (0.25,-40) [-40|-39.25] "" Node7
 SG_ Sig_65_4 : 24|16@1+ (0.1,-0.5) [-0.5|6553] "degC" Node7
 SG_ Sig_65_5 : 40|4@1- (0.5,-40) [-44|-36.5] "km/h" Node7

BO_ 67 Msg_66: 8 Node7
 SG_ Sig_66_0 : 0|12@1+ (0.5,0) [0|2047.5] "A" Node8
 SG_ Sig_66_1 : 12|3@1+ (0.01,0) [0|0.07] "" Node8
 SG_ Sig_66_2 : 15|4@1- (0.5,0) [-4|3.5] "A" Node8
 SG_ Sig_66_3 : 19|2@1- (2,0) [-4|2] "" Node8
 SG_ Sig_66_4 : 21|8@1+ (1,0) [0|255] "" Node8
 SG_ Sig_66_5 : 29|12@1+ (0.1,100) [100|509.5] "A" Node8

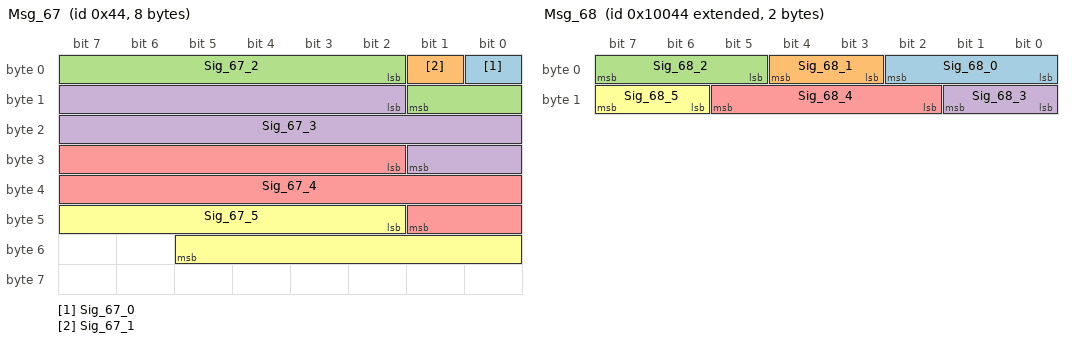
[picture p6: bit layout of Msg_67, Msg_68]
BO_ 68 Msg_67: 8 Node8
 SG_ Sig_67_0 : 0|1@1+ (1,0) [0|1] "" Node9
 SG_ Sig_67_1 : 1|1@1+ (1,0) [0|1] "" Node9
 SG_ Sig_67_2 : 2|8@1+ (1,0) [0|255] "degC" Node9
 SG_ Sig_67_3 : 10|16@1+ (2,0) [0|131070] "A" Node9
 SG_ Sig_67_4 : 26|16@1+ (2,100) [100|131170] "%" Node9
 SG_ Sig_67_5 : 42|12@1+ (0.1,-40) [-40|369.5] "degC" Node9

BO_ 2147549252 Msg_68: 2 Node9
 SG_ Sig_68_0 : 0|3@1+ (0.01,100) [100|100.07] "%" Node10
 SG_ Sig_68_1 : 3|2@1+ (1,0) [0|3] "" Node10
 SG_ Sig_68_2 : 5|3@1- (2,-0.5) [-8.5|5.5] "V" Node10
 SG_ Sig_68_3 : 8|2@1+ (0.01,0) [0|0.03] "" Node10
 SG_ Sig_68_4 : 10|4@1+ (0.01,-0.5) [-0.5|-0.35] "degC" Node10
 SG_ Sig_68_5 : 14|2@1- (1,-40) [-42|-39] "" Node10

BO_ 70 Msg_69: 6 Node10
 SG_ Sig_69_0 : 0|12@1+ (2,0) [0|8190] "V" Node11,Node12
 SG_ Sig_69_1 : 12|8@1+ (0.1,-0.5) [-0.5|25] "km/h" Node11,Node12
 SG_ Sig_69_2 : 20|8@1+ (2,0) [0|510] "km/h" Node11,Node12
 SG_ Sig_69_3 : 28|16@1+ (1,0) [0|65535] "km/h" Node11,Node12
 SG_ Sig_69_4 : 44|4@1+ (0.01,0) [0|0.15] "" Node11,Node12

BO_ 71 Msg_70: 24 Node11
 SG_ Sig_70_0 : 0|8@1- (0.1,0) [-12.8|12.7] "V" Node12
 SG_ Sig_70_1 : 8|2@1+ (0.25,-0.5) [-0.5|0.25] "" Node12
 SG_ Sig_70_2 : 10|8@1+ (0.01,-40) [-40|-37.45] "km/h" Node12
 SG_ Sig_70_3 : 18|16@1- (1,100) [-32668|32867] "A" Node12
 SG_ Sig_70_4 : 34|16@1+ (0.5,-0.5) [-0.5|32767] "degC" Node12
 SG_ Sig_70_5 : 50|2@1- (2,0) [-4|2] "" Node12

BO_ 72 Msg_71: 8 Node12
 SG_ Sig_71_0 : 7|8@0+ (2,0) [0|510] "" Node1,Node2
 SG_ Sig_71_1 : 15|8@0+ (2,100) [100|610] "V" Node1,Node2
 SG_ Sig_71_2 : 23|12@0+ (1,-40) [-40|4055] "degC" Node1,Node2
 SG_ Sig_71_3 : 27|4@0+ (0.25,0) [0|3.75] "degC" Node1,Node2
 SG_ Sig_71_4 : 39|2@0+ (0.01,0) [0|0.03] "" Node1,Node2
 SG_ Sig_71_5 : 37|2@0- (1,100) [98|101] "" Node1,Node2

BO_ 73 Msg_72: 8 Node1
 SG_ Sig_72_0 : 0|4@1+ (0.01,100) [100|100.15] "degC" Node2
 SG_ Sig_72_1 : 4|1@1+ (1,0) [0|1] "" Node2
 SG_ Sig_72_2 : 5|3@1+ (1,-0.5) [-0.5|6.5] "rpm" Node2
 SG_ Sig_72_3 : 8|16@1+ (2,100) [100|131170] "" Node2
 SG_ Sig_72_4 : 24|2@1- (0.5,100) [99|100.5] "" Node2
 SG_ Sig_72_5 : 26|2@1+ (1,0) [0|3] "" Node2

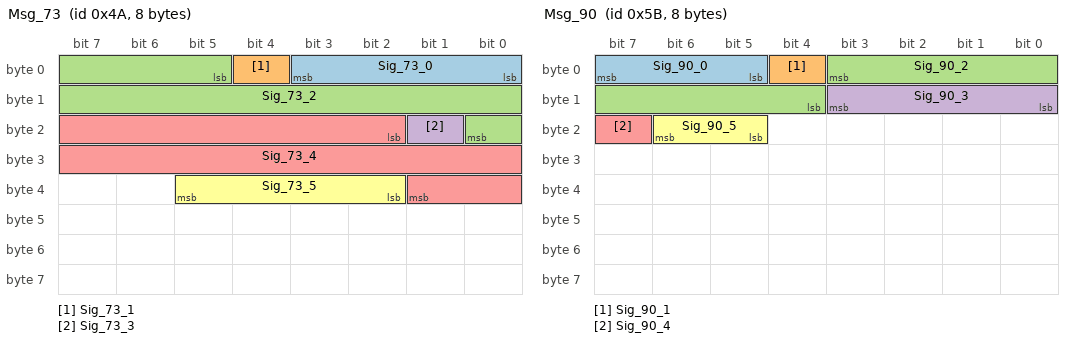
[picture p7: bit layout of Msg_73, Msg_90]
BO_ 74 Msg_73: 8 Node2
 SG_ Sig_73_0 : 0|4@1+ (0.1,0) [0|1.5] "rpm" Node3
 SG_ Sig_73_1 : 4|1@1+ (1,0) [0|1] "" Node3
 SG_ Sig_73_2 : 5|12@1+ (1,-0.5) [-0.5|4094.5] "degC" Node3
 SG_ Sig_73_3 : 17|1@1+ (1,0) [0|1] "" Node3
 SG_ Sig_73_4 : 18|16@1+ (1,0) [0|65535] "%" Node3
 SG_ Sig_73_5 : 34|4@1- (1,0) [-8|7] "V" Node3

BO_ 75 Msg_74: 12 Node3
 SG_ Sig_74_0 : 0|1@1+ (1,0) [0|1] "" Node4
 SG_ Sig_74_1 : 1|3@1+ (0.1,100) [100|100.7] "" Node4
 SG_ Sig_74_2 : 4|3@1- (2,0) [-8|6] "A" Node4
 SG_ Sig_74_3 : 7|8@1+ (0.01,0) [0|2.55] "%" Node4
 SG_ Sig_74_4 : 15|16@1+ (0.25,0) [0|16383.75] "V" Node4
 SG_ Sig_74_5 : 31|2@1+ (0.5,0) [0|1.5] "" Node4

BO_ 76 Msg_75: 2 Node4
 SG_ Sig_75_0 : 0|3@1- (2,100) [92|106] "degC" Node5
 SG_ Sig_75_1 : 3|2@1+ (2,-40) [-40|-34] "" Node5
 SG_ Sig_75_2 : 5|1@1+ (1,0) [0|1] "" Node5
 SG_ Sig_75_3 : 6|8@1- (0.01,-40) [-41.28|-38.73] "km/h" Node5
 SG_ Sig_75_4 : 14|2@1+ (1,0) [0|3] "" Node5

BO_ 77 Msg_76: 24 Node5
 SG_ Sig_76_sel M : 0|8@1+ (0.01,100) [100|102.55] "" Node6
 SG_ Sig_76_a0 m0 : 8|16@1- (1,100) [-32668|32867] "km/h" Node6
 SG_ Sig_76_a1 m0 : 24|8@1+ (2,0) [0|510] "degC" Node6
 SG_ Sig_76_b0 m1 : 8|8@1+ (0.5,0) [0|127.5] "" Node6
 SG_ Sig_76_b1 m1 : 16|1@1+ (1,0) [0|1] "" Node6
 SG_ Sig_76_c0 : 40|16@1+ (0.25,0) [0|16383.75] "" Node6
 SG_ Sig_76_c1 : 56|16@1+ (0.1,100) [100|6653.5] "A" Node6

BO_ 78 Msg_77: 64 Node6
 SG_ Sig_77_0 : 7|8@0+ (0.1,-40) [-40|-14.5] "A" Node7
 SG_ Sig_77_1 : 15|3@0- (0.01,-40) [-40.04|-39.97] "km/h" Node7
 SG_ Sig_77_2 : 12|16@0+ (0.01,-0.5) [-0.5|654.85] "" Node7
 SG_ Sig_77_3 : 28|3@0+ (0.5,-40) [-40|-36.5] "%" Node7
 SG_ Sig_77_4 : 25|8@0+ (0.01,-0.5) [-0.5|2.05] "V" Node7
 SG_ Sig_77_5 : 33|3@0+ (1,-40) [-40|-33] "" Node7

BO_ 79 Msg_78: 32 Node7
 SG_ Sig_78_0 : 0|8@1+ (0.25,0) [0|63.75] "degC" Node8
 SG_ Sig_78_1 : 8|2@1+ (1,-0.5) [-0.5|2.5] "" Node8
 SG_ Sig_78_2 : 10|12@1+ (1,0) [0|4095] "km/h" Node8
 SG_ Sig_78_3 : 22|2@1+ (1,-0.5) [-0.5|2.5] "" Node8
 SG_ Sig_78_4 : 24|8@1- (1,100) [-28|227] "%" Node8
 SG_ Sig_78_5 : 32|3@1+ (0.1,0) [0|0.7] "rpm" Node8

BO_ 2147549263 Msg_79: 8 Node8
 SG_ Sig_79_0 : 0|8@1+ (0.25,0) [0|63.75] "degC" Node9
 SG_ Sig_79_1 : 8|4@1- (2,-40) [-56|-26] "" Node9
 SG_ Sig_79_2 : 12|16@1+ (0.01,-0.5) [-0.5|654.85] "V" Node9
 SG_ Sig_79_3 : 28|4@1+ (2,-0.5) [-0.5|29.5] "V" Node9
 SG_ Sig_79_4 : 32|2@1+ (0.01,-40) [-40|-39.97] "" Node9
 SG_ Sig_79_5 : 34|4@1+ (1,-40) [-40|-25] "V" Node9

BO_ 2147549264 Msg_80: 12 Node9
 SG_ Sig_80_0 : 0|16@1+ (0.01,0) [0|655.35] "km/h" Node10,Node11
 SG_ Sig_80_1 : 16|3@1+ (0.5,0) [0|3.5] "%" Node10,Node11
 SG_ Sig_80_2 : 19|8@1+ (0.25,100) [100|163.75] "%" Node10,Node11
 SG_ Sig_80_3 : 27|1@1+ (1,0) [0|1] "" Node10,Node11
 SG_ Sig_80_4 : 28|4@1- (0.1,0) [-0.8|0.7] "V" Node10,Node11
 SG_ Sig_80_5 : 32|2@1+ (0.1,100) [100|100.3] "" Node10,Node11

BO_ 2147549265 Msg_81: 12 Node10
 SG_ Sig_81_sel M : 0|8@1- (0.5,100) [36|163.5] "rpm" Node11,Node12
 SG_ Sig_81_a0 m0 : 8|3@1+ (2,-0.5) [-0.5|13.5] "km/h" Node11,Node12
 SG_ Sig_81_a1 m0 : 11|16@1+ (1,-0.5) [-0.5|65534.5] "degC" Node11,Node12
 SG_ Sig_81_b0 m1 : 8|1@1+ (1,0) [0|1] "" Node11,Node12
 SG_ Sig_81_b1 m1 : 9|12@1+ (2,-40) [-40|8150] "%" Node11,Node12
 SG_ Sig_81_c0 : 40|16@1+ (1,0) [0|65535] "%" Node11,Node12
 SG_ Sig_81_c1 : 56|16@1+ (1,0) [0|65535] "" Node11,Node12

BO_ 83 Msg_82: 16 Node11
 SG_ Sig_82_0 : 0|1@1+ (1,0) [0|1] "" Node12
 SG_ Sig_82_1 : 1|16@1- (2,0) [-65536|65534] "A" Node12
 SG_ Sig_82_2 : 17|12@1+ (0.25,-40) [-40|983.75] "A" Node12
 SG_ Sig_82_3 : 29|8@1+ (0.25,100) [100|163.75] "V" Node12
 SG_ Sig_82_4 : 37|3@1+ (0.25,0) [0|1.75] "%" Node12
 SG_ Sig_82_5 : 40|8@1- (0.25,100) [68|131.75] "A" Node12

BO_ 84 Msg_83: 8 Node12
 SG_ Sig_83_0 : 7|8@0+ (1,0) [0|255] "V" Node1
 SG_ Sig_83_1 : 15|12@0- (0.5,0) [-1024|1023.5] "" Node1
 SG_ Sig_83_2 : 19|12@0+ (1,0) [0|4095] "degC" Node1
 SG_ Sig_83_3 : 39|8@0+ (1,-40) [-40|215] "km/h" Node1
 SG_ Sig_83_4 : 47|3@0+ (0.25,0) [0|1.75] "" Node1
 SG_ Sig_83_5 : 44|4@0+ (1,-0.5) [-0.5|14.5] "km/h" Node1

BO_ 85 Msg_84: 8 Node1
 SG_ Sig_84_0 : 7|8@0- (2,0) [-256|254] "" Node2
 SG_ Sig_84_1 : 15|2@0- (0.01,0) [-0.02|0.01] "" Node2
 SG_ Sig_84_2 : 13|2@0+ (0.1,-40) [-40|-39.7] "" Node2
 SG_ Sig_84_3 : 11|4@0+ (1,-0.5) [-0.5|14.5] "V" Node2
 SG_ Sig_84_4 : 23|8@0+ (0.01,0) [0|2.55] "A" Node2
 SG_ Sig_84_5 : 31|16@0+ (0.01,-0.5) [-0.5|654.85] "%" Node2

BO_ 86 Msg_85: 16 Node2
 SG_ Sig_85_0 : 7|12@0- (0.5,-40) [-1064|983.5] "V" Node3,Node4
 SG_ Sig_85_1 : 11|3@0+ (0.25,100) [100|101.75] "%" Node3,Node4
 SG_ Sig_85_2 : 8|1@0+ (1,0) [0|1] "" Node3,Node4
 SG_ Sig_85_3 : 23|2@0- (0.5,-0.5) [-1.5|0] "" Node3,Node4
 SG_ Sig_85_4 : 21|4@0- (0.01,100) [99.92|100.07] "km/h" Node3,Node4
 SG_ Sig_85_5 : 17|3@0+ (1,0) [0|7] "%" Node3,Node4

BO_ 87 Msg_86: 6 Node3
 SG_ Sig_86_0 : 0|8@1+ (0.1,-0.5) [-0.5|25] "V" Node4
 SG_ Sig_86_1 : 8|3@1+ (0.01,-0.5) [-0.5|-0.43] "km/h" Node4
 SG_ Sig_86_2 : 11|16@1+ (0.1,0) [0|6553.5] "degC" Node4
 SG_ Sig_86_3 : 27|16@1+ (0.5,0) [0|32767.5] "A" Node4
 SG_ Sig_86_4 : 43|5@1- (0.5,0) [-8|7.5] "" Node4

BO_ 88 Msg_87: 8 Node4
 SG_ Sig_87_0 : 0|16@1+ (1,100) [100|65635] "" Node5,Node6
 SG_ Sig_87_1 : 16|12@1- (2,-40) [-4136|4054] "A" Node5,Node6
 SG_ Sig_87_2 : 28|8@1+ (0.1,-0.5) [-0.5|25] "%" Node5,Node6
 SG_ Sig_87_3 : 36|1@1+ (1,0) [0|1] "" Node5,Node6
 SG_ Sig_87_4 : 37|12@1+ (0.01,100) [100|140.95] "degC" Node5,Node6
 SG_ Sig_87_5 : 49|8@1- (0.25,-40) [-72|-8.25] "rpm" Node5,Node6

BO_ 89 Msg_88: 16 Node5
 SG_ Sig_88_sel M : 0|8@1+ (0.01,0) [0|2.55] "" Node6
 SG_ Sig_88_a0 m0 : 8|8@1+ (2,-40) [-40|470] "A" Node6
 SG_ Sig_88_a1 m0 : 16|2@1+ (0.01,100) [100|100.03] "" Node6
 SG_ Sig_88_b0 m1 : 8|8@1+ (0.01,0) [0|2.55] "degC" Node6
 SG_ Sig_88_b1 m1 : 16|16@1+ (0.5,0) [0|32767.5] "degC" Node6
 SG_ Sig_88_c0 : 40|8@1+ (0.1,0) [0|25.5] "degC" Node6
 SG_ Sig_88_c1 : 48|1@1+ (1,0) [0|1] "" Node6

BO_ 90 Msg_89: 32 Node6
 SG_ Sig_89_0 : 7|8@0+ (0.01,-40) [-40|-37.45] "rpm" Node7
 SG_ Sig_89_1 : 15|2@0+ (0.5,100) [100|101.5] "" Node7
 SG_ Sig_89_2 : 13|8@0- (1,-0.5) [-128.5|126.5] "rpm" Node7
 SG_ Sig_89_3 : 21|3@0+ (1,0) [0|7] "rpm" Node7
 SG_ Sig_89_4 : 18|12@0+ (0.5,100) [100|2147.5] "degC" Node7
 SG_ Sig_89_5 : 38|4@0+ (0.25,100) [100|103.75] "" Node7

BO_ 91 Msg_90: 8 Node7
 SG_ Sig_90_0 : 7|3@0+ (1,0) [0|7] "%" Node8
 SG_ Sig_90_1 : 4|1@0+ (1,0) [0|1] "" Node8
 SG_ Sig_90_2 : 3|8@0+ (0.01,0) [0|2.55] "V" Node8
 SG_ Sig_90_3 : 11|4@0+ (1,0) [0|15] "" Node8
 SG_ Sig_90_4 : 23|1@0+ (1,0) [0|1] "" Node8
 SG_ Sig_90_5 : 22|2@0- (1,0) [-2|1] "" Node8

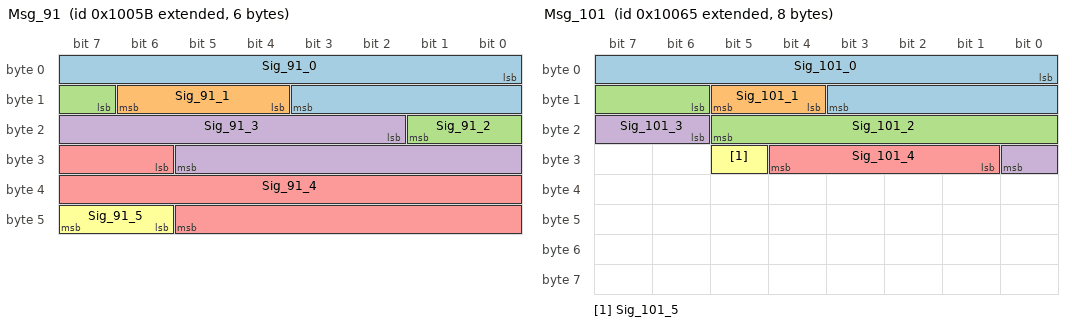
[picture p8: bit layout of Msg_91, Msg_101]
BO_ 2147549275 Msg_91: 6 Node8
 SG_ Sig_91_0 : 0|12@1+ (0.1,0) [0|409.5] "degC" Node9,Node10
 SG_ Sig_91_1 : 12|3@1+ (1,0) [0|7] "A" Node9,Node10
 SG_ Sig_91_2 : 15|3@1+ (1,100) [100|107] "rpm" Node9,Node10
 SG_ Sig_91_3 : 18|12@1- (0.25,0) [-512|511.75] "A" Node9,Node10
 SG_ Sig_91_4 : 30|16@1- (0.1,-0.5) [-3277.3|3276.2] "A" Node9,Node10
 SG_ Sig_91_5 : 46|2@1- (0.5,0) [-1|0.5] "" Node9,Node10

BO_ 2147549276 Msg_92: 8 Node9
 SG_ Sig_92_0 : 7|8@0+ (0.5,100) [100|227.5] "%" Node10
 SG_ Sig_92_1 : 15|12@0- (2,0) [-4096|4094] "V" Node10
 SG_ Sig_92_2 : 19|16@0+ (2,0) [0|131070] "rpm" Node10
 SG_ Sig_92_3 : 35|8@0+ (0.1,0) [0|25.5] "" Node10
 SG_ Sig_92_4 : 43|2@0+ (2,-40) [-40|-34] "" Node10
 SG_ Sig_92_5 : 41|4@0+ (1,100) [100|115] "degC" Node10

BO_ 2147549277 Msg_93: 64 Node10
 SG_ Sig_93_0 : 7|8@0+ (0.01,0) [0|2.55] "%" Node11
 SG_ Sig_93_1 : 15|12@0+ (0.25,0) [0|1023.75] "A" Node11
 SG_ Sig_93_2 : 19|1@0+ (1,0) [0|1] "" Node11
 SG_ Sig_93_3 : 18|8@0+ (0.5,0) [0|127.5] "%" Node11
 SG_ Sig_93_4 : 26|12@0+ (0.01,100) [100|140.95] "" Node11
 SG_ Sig_93_5 : 46|4@0+ (0.1,0) [0|1.5] "" Node11

BO_ 95 Msg_94: 8 Node11
 SG_ Sig_94_sel M : 0|8@1+ (1,-40) [-40|215] "degC" Node12
 SG_ Sig_94_a0 m0 : 8|4@1+ (0.1,0) [0|1.5] "km/h" Node12
 SG_ Sig_94_a1 m0 : 12|12@1+ (0.1,0) [0|409.5] "rpm" Node12
 SG_ Sig_94_b0 m1 : 8|3@1+ (0.5,0) [0|3.5] "" Node12
 SG_ Sig_94_b1 m1 : 11|3@1+ (0.25,100) [100|101.75] "km/h" Node12
 SG_ Sig_94_c0 : 40|2@1+ (2,100) [100|106] "" Node12
 SG_ Sig_94_c1 : 42|8@1+ (1,-40) [-40|215] "" Node12

BO_ 96 Msg_95: 2 Node12
 SG_ Sig_95_0 : 0|3@1+ (1,-0.5) [-0.5|6.5] "rpm" Node1
 SG_ Sig_95_1 : 3|13@1+ (0.01,-0.5) [-0.5|81.41] "km/h" Node1

BO_ 97 Msg_96: 6 Node1
 SG_ Sig_96_0 : 0|16@1+ (1,100) [100|65635] "rpm" Node2
 SG_ Sig_96_1 : 16|8@1- (0.01,100) [98.72|101.27] "A" Node2
 SG_ Sig_96_2 : 24|4@1- (0.01,-0.5) [-0.58|-0.43] "degC" Node2
 SG_ Sig_96_3 : 28|12@1+ (0.01,-40) [-40|0.95] "A" Node2
 SG_ Sig_96_4 : 40|8@1+ (1,0) [0|255] "km/h" Node2

BO_ 98 Msg_97: 32 Node2
 SG_ Sig_97_0 : 0|8@1+ (0.5,0) [0|127.5] "V" Node3
 SG_ Sig_97_1 : 8|3@1+ (0.5,0) [0|3.5] "rpm" Node3
 SG_ Sig_97_2 : 11|4@1+ (2,0) [0|30] "km/h" Node3
 SG_ Sig_97_3 : 15|1@1+ (1,0) [0|1] "" Node3
 SG_ Sig_97_4 : 16|8@1+ (2,0) [0|510] "km/h" Node3
 SG_ Sig_97_5 : 24|16@1+ (0.01,-0.5) [-0.5|654.85] "degC" Node3

BO_ 99 Msg_98: 4 Node3
 SG_ Sig_98_0 : 0|8@1- (0.25,0) [-32|31.75] "A" Node4
 SG_ Sig_98_1 : 8|2@1+ (1,-0.5) [-0.5|2.5] "" Node4
 SG_ Sig_98_2 : 10|4@1+ (0.5,0) [0|7.5] "rpm" Node4
 SG_ Sig_98_3 : 14|2@1+ (0.1,-0.5) [-0.5|-0.2] "" Node4
 SG_ Sig_98_4 : 16|8@1+ (0.5,-0.5) [-0.5|127] "V" Node4
 SG_ Sig_98_5 : 24|8@1+ (0.1,-0.5) [-0.5|25] "V" Node4

BO_ 100 Msg_99: 4 Node4
 SG_ Sig_99_0 : 0|3@1+ (0.01,0) [0|0.07] "degC" Node5,Node6
 SG_ Sig_99_1 : 3|16@1+ (0.01,-0.5) [-0.5|654.85] "km/h" Node5,Node6
 SG_ Sig_99_2 : 19|4@1+ (0.25,0) [0|3.75] "rpm" Node5,Node6
 SG_ Sig_99_3 : 23|2@1- (0.25,-0.5) [-1|-0.25] "" Node5,Node6
 SG_ Sig_99_4 : 25|7@1+ (1,0) [0|127] "rpm" Node5,Node6

BO_ 101 Msg_100: 24 Node5
 SG_ Sig_100_0 : 0|2@1+ (0.5,0) [0|1.5] "" Node6,Node7
 SG_ Sig_100_1 : 2|4@1+ (2,0) [0|30] "" Node6,Node7
 SG_ Sig_100_2 : 6|3@1+ (2,0) [0|14] "V" Node6,Node7
 SG_ Sig_100_3 : 9|1@1+ (1,0) [0|1] "" Node6,Node7
 SG_ Sig_100_4 : 10|8@1+ (0.25,0) [0|63.75] "V" Node6,Node7
 SG_ Sig_100_5 : 18|8@1+ (0.01,0) [0|2.55] "rpm" Node6,Node7

BO_ 2147549285 Msg_101: 8 Node6
 SG_ Sig_101_0 : 0|12@1+ (2,0) [0|8190] "rpm" Node7,Node8
 SG_ Sig_101_1 : 12|2@1+ (0.5,0) [0|1.5] "" Node7,Node8
 SG_ Sig_101_2 : 14|8@1+ (2,100) [100|610] "V" Node7,Node8
 SG_ Sig_101_3 : 22|3@1+ (1,0) [0|7] "km/h" Node7,Node8
 SG_ Sig_101_4 : 25|4@1- (1,0) [-8|7] "A" Node7,Node8
 SG_ Sig_101_5 : 29|1@1+ (1,0) [0|1] "" Node7,Node8

BO_ 103 Msg_102: 16 Node7
 SG_ Sig_102_0 : 0|3@1+ (0.5,0) [0|3.5] "" Node8,Node9
 SG_ Sig_102_1 : 3|2@1+ (1,-0.5) [-0.5|2.5] "" Node8,Node9
 SG_ Sig_102_2 : 5|8@1- (0.01,0) [-1.28|1.27] "A" Node8,Node9
 SG_ Sig_102_3 : 13|1@1+ (1,0) [0|1] "" Node8,Node9
 SG_ Sig_102_4 : 14|8@1+ (1,-40) [-40|215] "degC" Node8,Node9
 SG_ Sig_102_5 : 22|8@1+ (1,0) [0|255] "rpm" Node8,Node9

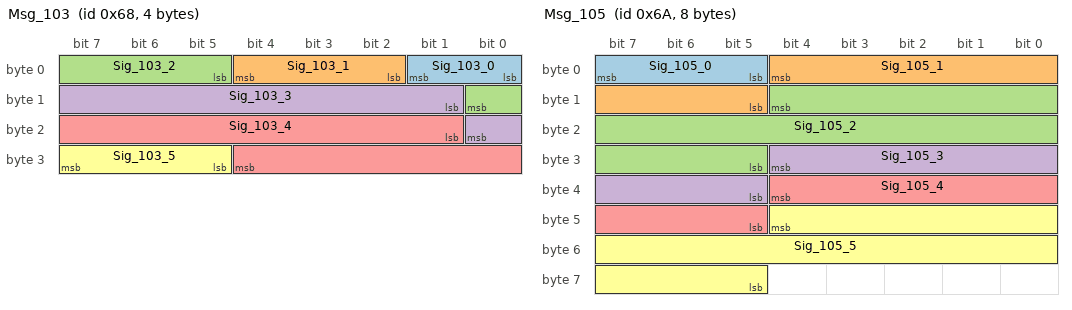
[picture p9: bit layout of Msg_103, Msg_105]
BO_ 104 Msg_103: 4 Node8
 SG_ Sig_103_0 : 0|2@1- (2,0) [-4|2] "" Node9,Node10
 SG_ Sig_103_1 : 2|3@1- (0.25,0) [-1|0.75] "rpm" Node9,Node10
 SG_ Sig_103_2 : 5|4@1+ (0.1,0) [0|1.5] "A" Node9,Node10
 SG_ Sig_103_3 : 9|8@1+ (1,0) [0|255] "A" Node9,Node10
 SG_ Sig_103_4 : 17|12@1+ (0.25,0) [0|1023.75] "rpm" Node9,Node10
 SG_ Sig_103_5 : 29|3@1+ (1,-0.5) [-0.5|6.5] "" Node9,Node10

BO_ 2147549288 Msg_104: 8 Node9
 SG_ Sig_104_0 : 7|16@0+ (2,0) [0|131070] "%" Node10,Node11
 SG_ Sig_104_1 : 23|16@0+ (1,0) [0|65535] "rpm" Node10,Node11
 SG_ Sig_104_2 : 39|4@0+ (1,0) [0|15] "km/h" Node10,Node11
 SG_ Sig_104_3 : 35|4@0+ (0.5,100) [100|107.5] "" Node10,Node11
 SG_ Sig_104_4 : 47|4@0+ (1,0) [0|15] "A" Node10,Node11
 SG_ Sig_104_5 : 43|16@0+ (1,-0.5) [-0.5|65534.5] "A" Node10,Node11

BO_ 106 Msg_105: 8 Node10
 SG_ Sig_105_0 : 7|3@0+ (0.01,100) [100|100.07] "km/h" Node11
 SG_ Sig_105_1 : 4|8@0+ (2,0) [0|510] "A" Node11
 SG_ Sig_105_2 : 12|16@0+ (1,100) [100|65635] "A" Node11
 SG_ Sig_105_3 : 28|8@0+ (0.5,-40) [-40|87.5] "%" Node11
 SG_ Sig_105_4 : 36|8@0+ (0.01,0) [0|2.55] "A" Node11
 SG_ Sig_105_5 : 44|16@0+ (2,-0.5) [-0.5|131069.5] "km/h" Node11

BO_ 107 Msg_106: 12 Node11
 SG_ Sig_106_0 : 7|4@0- (0.01,0) [-0.08|0.07] "km/h" Node12
 SG_ Sig_106_1 : 3|8@0- (1,0) [-128|127] "" Node12
 SG_ Sig_106_2 : 11|8@0- (1,100) [-28|227] "degC" Node12
 SG_ Sig_106_3 : 19|8@0+ (0.1,0) [0|25.5] "" Node12
 SG_ Sig_106_4 : 27|8@0+ (1,0) [0|255] "degC" Node12
 SG_ Sig_106_5 : 35|1@0+ (1,0) [0|1] "" Node12

BO_ 108 Msg_107: 8 Node12
 SG_ Sig_107_0 : 7|16@0+ (0.5,100) [100|32867.5] "rpm" Node1,Node2
 SG_ Sig_107_1 : 23|16@0+ (0.1,0) [0|6553.5] "rpm" Node1,Node2
 SG_ Sig_107_2 : 39|2@0+ (2,-40) [-40|-34] "" Node1,Node2
 SG_ Sig_107_3 : 37|4@0+ (0.25,-0.5) [-0.5|3.25] "A" Node1,Node2
 SG_ Sig_107_4 : 33|8@0- (2,100) [-156|354] "" Node1,Node2
 SG_ Sig_107_5 : 41|8@0+ (0.01,0) [0|2.55] "degC" Node1,Node2

BO_ 2147549292 Msg_108: 64 Node1
 SG_ Sig_108_0 : 0|16@1+ (0.01,0) [0|655.35] "km/h" Node2
 SG_ Sig_108_1 : 16|8@1+ (0.1,0) [0|25.5] "rpm" Node2
 SG_ Sig_108_2 : 24|8@1+ (0.25,-0.5) [-0.5|63.25] "km/h" Node2
 SG_ Sig_108_3 : 32|16@1+ (2,-0.5) [-0.5|131069.5] "km/h" Node2
 SG_ Sig_108_4 : 48|1@1+ (1,0) [0|1] "" Node2
 SG_ Sig_108_5 : 49|8@1+ (1,0) [0|255] "" Node2

BO_ 110 Msg_109: 2 Node2
 SG_ Sig_109_0 : 7|12@0+ (0.01,-40) [-40|0.95] "%" Node3,Node4
 SG_ Sig_109_1 : 11|4@0+ (1,0) [0|15] "V" Node3,Node4

BO_ 111 Msg_110: 16 Node3
 SG_ Sig_110_0 : 0|8@1- (0.25,100) [68|131.75] "%" Node4
 SG_ Sig_110_1 : 8|4@1+ (1,100) [100|115] "km/h" Node4
 SG_ Sig_110_2 : 12|8@1+ (0.25,0) [0|63.75] "A" Node4
 SG_ Sig_110_3 : 20|1@1+ (1,0) [0|1] "" Node4
 SG_ Sig_110_4 : 21|8@1+ (1,0) [0|255] "km/h" Node4
 SG_ Sig_110_5 : 29|16@1+ (1,-0.5) [-0.5|65534.5] "%" Node4

BO_ 112 Msg_111: 12 Node4
 SG_ Sig_111_0 : 7|16@0+ (1,0) [0|65535] "degC" Node5
 SG_ Sig_111_1 : 23|8@0+ (2,0) [0|510] "V" Node5
 SG_ Sig_111_2 : 31|2@0+ (0.1,-40) [-40|-39.7] "" Node5
 SG_ Sig_111_3 : 29|16@0+ (1,0) [0|65535] "V" Node5
 SG_ Sig_111_4 : 45|1@0+ (1,0) [0|1] "" Node5
 SG_ Sig_111_5 : 44|16@0- (1,-40) [-32808|32727] "degC" Node5

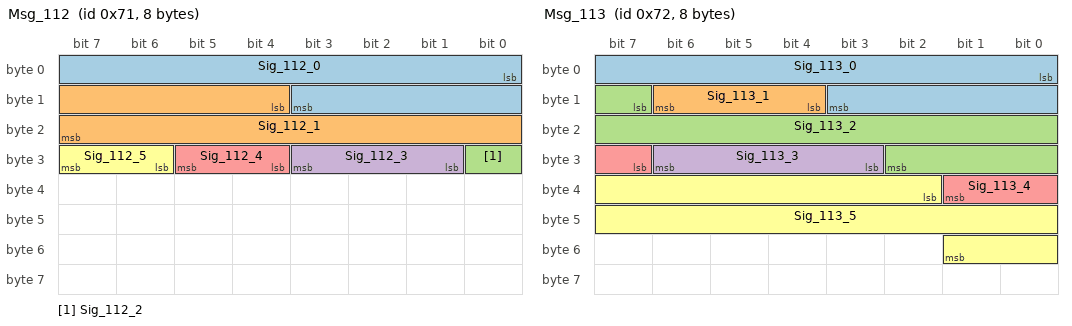
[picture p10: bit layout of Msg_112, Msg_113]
BO_ 113 Msg_112: 8 Node5
 SG_ Sig_112_0 : 0|12@1+ (2,-0.5) [-0.5|8189.5] "" Node6,Node7
 SG_ Sig_112_1 : 12|12@1+ (2,0) [0|8190] "km/h" Node6,Node7
 SG_ Sig_112_2 : 24|1@1+ (1,0) [0|1] "" Node6,Node7
 SG_ Sig_112_3 : 25|3@1+ (1,100) [100|107] "V" Node6,Node7
 SG_ Sig_112_4 : 28|2@1+ (0.1,0) [0|0.3] "" Node6,Node7
 SG_ Sig_112_5 : 30|2@1+ (1,0) [0|3] "" Node6,Node7

BO_ 114 Msg_113: 8 Node6
 SG_ Sig_113_0 : 0|12@1+ (0.1,0) [0|409.5] "rpm" Node7,Node8
 SG_ Sig_113_1 : 12|3@1+ (0.5,0) [0|3.5] "degC" Node7,Node8
 SG_ Sig_113_2 : 15|12@1- (1,0) [-2048|2047] "V" Node7,Node8
 SG_ Sig_113_3 : 27|4@1- (1,0) [-8|7] "" Node7,Node8
 SG_ Sig_113_4 : 31|3@1- (0.5,0) [-2|1.5] "A" Node7,Node8
 SG_ Sig_113_5 : 34|16@1+ (0.01,0) [0|655.35] "V" Node7,Node8

BO_ 2147549298 Msg_114: 8 Node7
 SG_ Sig_114_0 : 7|12@0+ (0.01,0) [0|40.95] "degC" Node8
 SG_ Sig_114_1 : 11|8@0+ (0.5,100) [100|227.5] "%" Node8
 SG_ Sig_114_2 : 19|4@0- (2,0) [-16|14] "degC" Node8
 SG_ Sig_114_3 : 31|8@0+ (2,-40) [-40|470] "degC" Node8
 SG_ Sig_114_4 : 39|16@0- (0.5,0) [-16384|16383.5] "km/h" Node8
 SG_ Sig_114_5 : 55|8@0+ (1,-0.5) [-0.5|254.5] "rpm" Node8

BO_ 116 Msg_115: 8 Node8
 SG_ Sig_115_0 : 7|8@0+ (0.25,0) [0|63.75] "km/h" Node9,Node10
 SG_ Sig_115_1 : 15|12@0+ (1,-0.5) [-0.5|4094.5] "V" Node9,Node10
 SG_ Sig_115_2 : 19|4@0+ (0.1,0) [0|1.5] "" Node9,Node10
 SG_ Sig_115_3 : 31|4@0+ (2,0) [0|30] "degC" Node9,Node10
 SG_ Sig_115_4 : 27|12@0+ (0.01,0) [0|40.95] "%" Node9,Node10
 SG_ Sig_115_5 : 47|8@0+ (1,0) [0|255] "" Node9,Node10

BO_ 117 Msg_116: 2 Node9
 SG_ Sig_116_0 : 7|2@0+ (2,0) [0|6] "" Node10
 SG_ Sig_116_1 : 5|8@0- (0.1,0) [-12.8|12.7] "" Node10
 SG_ Sig_116_2 : 13|6@0- (1,0) [-32|31] "%" Node10

BO_ 2147549301 Msg_117: 8 Node10
 SG_ Sig_117_0 : 7|8@0+ (2,0) [0|510] "%" Node11
 SG_ Sig_117_1 : 15|8@0+ (1,-0.5) [-0.5|254.5] "%" Node11
 SG_ Sig_117_2 : 23|12@0- (0.25,-40) [-552|471.75] "degC" Node11
 SG_ Sig_117_3 : 27|4@0+ (1,0) [0|15] "A" Node11
 SG_ Sig_117_4 : 39|8@0+ (0.25,0) [0|63.75] "" Node11
 SG_ Sig_117_5 : 47|1@0+ (1,0) [0|1] "" Node11

BO_ 119 Msg_118: 8 Node11
 SG_ Sig_118_0 : 7|8@0- (0.01,0) [-1.28|1.27] "A" Node12,Node1
 SG_ Sig_118_1 : 15|16@0- (1,0) [-32768|32767] "rpm" Node12,Node1
 SG_ Sig_118_2 : 31|3@0+ (1,-40) [-40|-33] "%" Node12,Node1
 SG_ Sig_118_3 : 28|12@0+ (2,100) [100|8290] "%" Node12,Node1
 SG_ Sig_118_4 : 32|12@0- (1,-40) [-2088|2007] "km/h" Node12,Node1
 SG_ Sig_118_5 : 52|13@0- (2,-40) [-8232|8150] "degC" Node12,Node1

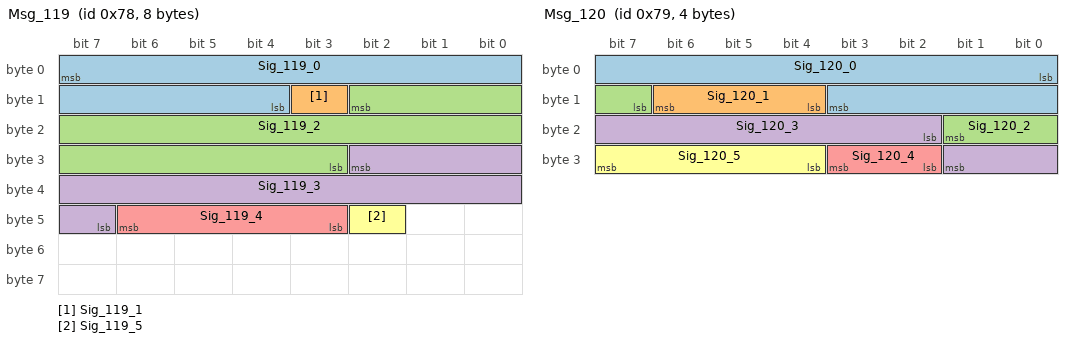
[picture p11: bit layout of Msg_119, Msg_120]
BO_ 120 Msg_119: 8 Node12
 SG_ Sig_119_0 : 7|12@0+ (0.1,-0.5) [-0.5|409] "%" Node1
 SG_ Sig_119_1 : 11|1@0+ (1,0) [0|1] "" Node1
 SG_ Sig_119_2 : 10|16@0+ (0.25,0) [0|16383.75] "%" Node1
 SG_ Sig_119_3 : 26|12@0- (2,0) [-4096|4094] "" Node1
 SG_ Sig_119_4 : 46|4@0+ (0.25,0) [0|3.75] "V" Node1
 SG_ Sig_119_5 : 42|1@0+ (1,0) [0|1] "" Node1

BO_ 121 Msg_120: 4 Node1
 SG_ Sig_120_0 : 0|12@1+ (1,0) [0|4095] "%" Node2
 SG_ Sig_120_1 : 12|3@1- (0.1,-0.5) [-0.9|-0.2] "degC" Node2
 SG_ Sig_120_2 : 15|3@1+ (0.5,-0.5) [-0.5|3] "km/h" Node2
 SG_ Sig_120_3 : 18|8@1- (1,0) [-128|127] "km/h" Node2
 SG_ Sig_120_4 : 26|2@1+ (1,0) [0|3] "" Node2
 SG_ Sig_120_5 : 28|4@1- (0.25,0) [-2|1.75] "km/h" Node2

BO_ 2147549305 Msg_121: 6 Node2
 SG_ Sig_121_0 : 7|8@0+ (1,0) [0|255] "A" Node3,Node4
 SG_ Sig_121_1 : 15|16@0- (1,100) [-32668|32867] "V" Node3,Node4
 SG_ Sig_121_2 : 31|8@0+ (0.25,100) [100|163.75] "km/h" Node3,Node4
 SG_ Sig_121_3 : 39|8@0- (1,100) [-28|227] "rpm" Node3,Node4
 SG_ Sig_121_4 : 47|4@0- (0.1,-40) [-40.8|-39.3] "degC" Node3,Node4
 SG_ Sig_121_5 : 43|4@0+ (0.01,0) [0|0.15] "km/h" Node3,Node4

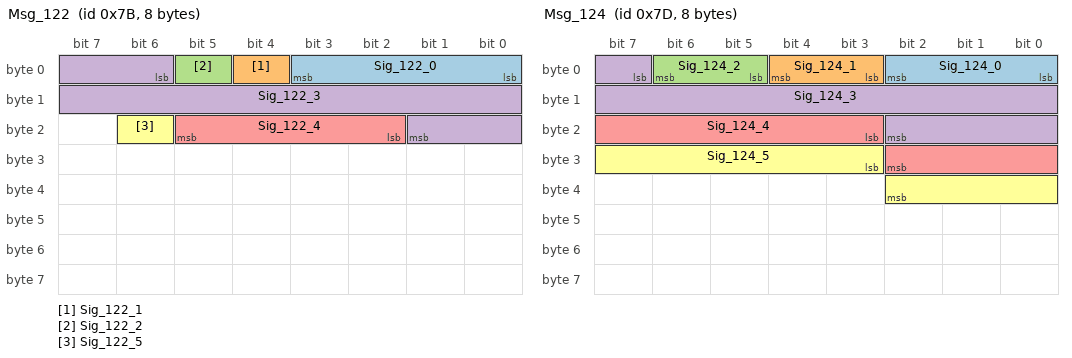
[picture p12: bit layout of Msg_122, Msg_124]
BO_ 123 Msg_122: 8 Node3
 SG_ Sig_122_0 : 0|4@1+ (2,0) [0|30] "" Node4
 SG_ Sig_122_1 : 4|1@1+ (1,0) [0|1] "" Node4
 SG_ Sig_122_2 : 5|1@1+ (1,0) [0|1] "" Node4
 SG_ Sig_122_3 : 6|12@1+ (1,100) [100|4195] "%" Node4
 SG_ Sig_122_4 : 18|4@1- (0.1,-40) [-40.8|-39.3] "V" Node4
 SG_ Sig_122_5 : 22|1@1+ (1,0) [0|1] "" Node4

BO_ 124 Msg_123: 12 Node4
 SG_ Sig_123_0 : 0|16@1+ (0.1,0) [0|6553.5] "A" Node5
 SG_ Sig_123_1 : 16|4@1+ (0.01,0) [0|0.15] "A" Node5
 SG_ Sig_123_2 : 20|4@1- (0.1,0) [-0.8|0.7] "km/h" Node5
 SG_ Sig_123_3 : 24|8@1+ (2,0) [0|510] "km/h" Node5
 SG_ Sig_123_4 : 32|3@1+ (0.5,-0.5) [-0.5|3] "%" Node5
 SG_ Sig_123_5 : 35|16@1- (1,100) [-32668|32867] "" Node5

BO_ 125 Msg_124: 8 Node5
 SG_ Sig_124_0 : 0|3@1+ (1,0) [0|7] "rpm" Node6,Node7
 SG_ Sig_124_1 : 3|2@1+ (0.5,-0.5) [-0.5|1] "" Node6,Node7
 SG_ Sig_124_2 : 5|2@1+ (0.01,100) [100|100.03] "" Node6,Node7
 SG_ Sig_124_3 : 7|12@1+ (0.01,-40) [-40|0.95] "V" Node6,Node7
 SG_ Sig_124_4 : 19|8@1+ (0.25,100) [100|163.75] "%" Node6,Node7
 SG_ Sig_124_5 : 27|8@1+ (0.1,0) [0|25.5] "A" Node6,Node7

BO_ 126 Msg_125: 12 Node6
 SG_ Sig_125_sel M : 0|8@1+ (2,100) [100|610] "degC" Node7
 SG_ Sig_125_a0 m0 : 8|16@1- (0.01,0) [-327.68|327.67] "degC" Node7
 SG_ Sig_125_a1 m0 : 24|1@1+ (1,0) [0|1] "" Node7
 SG_ Sig_125_b0 m1 : 8|3@1+ (0.5,-40) [-40|-36.5] "%" Node7
 SG_ Sig_125_b1 m1 : 11|4@1+ (0.01,-40) [-40|-39.85] "A" Node7
 SG_ Sig_125_c0 : 40|16@1+ (0.1,0) [0|6553.5] "rpm" Node7
 SG_ Sig_125_c1 : 56|4@1+ (0.25,0) [0|3.75] "A" Node7

BO_ 127 Msg_126: 32 Node7
 SG_ Sig_126_sel M : 0|8@1+ (0.25,100) [100|163.75] "rpm" Node8,Node9
 SG_ Sig_126_a0 m0 : 8|2@1+ (1,0) [0|3] "" Node8,Node9
 SG_ Sig_126_a1 m0 : 10|16@1+ (1,100) [100|65635] "%" Node8,Node9
 SG_ Sig_126_b0 m1 : 8|2@1+ (0.01,100) [100|100.03] "" Node8,Node9
 SG_ Sig_126_b1 m1 : 10|8@1+ (0.25,-0.5) [-0.5|63.25] "A" Node8,Node9
 SG_ Sig_126_c0 : 40|4@1+ (0.5,-0.5) [-0.5|7] "A" Node8,Node9
 SG_ Sig_126_c1 : 44|2@1- (2,-0.5) [-4.5|1.5] "" Node8,Node9

BO_ 128 Msg_127: 24 Node8
 SG_ Sig_127_0 : 7|16@0+ (0.01,-40) [-40|615.35] "V" Node9,Node10
 SG_ Sig_127_1 : 23|3@0+ (1,0) [0|7] "A" Node9,Node10
 SG_ Sig_127_2 : 20|4@0- (1,0) [-8|7] "degC" Node9,Node10
 SG_ Sig_127_3 : 16|16@0+ (0.5,0) [0|32767.5] "rpm" Node9,Node10
 SG_ Sig_127_4 : 32|8@0+ (0.5,0) [0|127.5] "km/h" Node9,Node10
 SG_ Sig_127_5 : 40|1@0+ (1,0) [0|1] "" Node9,Node10

BO_ 129 Msg_128: 4 Node9
 SG_ Sig_128_0 : 0|12@1+ (2,0) [0|8190] "km/h" Node10,Node11
 SG_ Sig_128_1 : 12|3@1- (1,0) [-4|3] "" Node10,Node11
 SG_ Sig_128_2 : 15|1@1+ (1,0) [0|1] "" Node10,Node11
 SG_ Sig_128_3 : 16|8@1+ (0.5,-40) [-40|87.5] "A" Node10,Node11
 SG_ Sig_128_4 : 24|8@1+ (0.25,100) [100|163.75] "km/h" Node10,Node11

BO_ 130 Msg_129: 8 Node10
 SG_ Sig_129_0 : 7|4@0- (2,-0.5) [-16.5|13.5] "" Node11
 SG_ Sig_129_1 : 3|16@0+ (0.25,0) [0|16383.75] "degC" Node11
 SG_ Sig_129_2 : 19|4@0+ (1,0) [0|15] "%" Node11
 SG_ Sig_129_3 : 31|8@0+ (0.01,-40) [-40|-37.45] "degC" Node11
 SG_ Sig_129_4 : 39|3@0+ (0.1,-40) [-40|-39.3] "A" Node11
 SG_ Sig_129_5 : 36|3@0+ (1,100) [100|107] "rpm" Node11

BO_ 2147549314 Msg_130: 6 Node11
 SG_ Sig_130_0 : 7|8@0+ (0.25,0) [0|63.75] "%" Node12
 SG_ Sig_130_1 : 15|3@0+ (0.1,0) [0|0.7] "rpm" Node12
 SG_ Sig_130_2 : 12|12@0+ (1,-40) [-40|4055] "rpm" Node12
 SG_ Sig_130_3 : 16|8@0+ (0.5,0) [0|127.5] "km/h" Node12
 SG_ Sig_130_4 : 24|3@0+ (1,0) [0|7] "V" Node12
 SG_ Sig_130_5 : 37|4@0- (1,100) [92|107] "V" Node12

BO_ 132 Msg_131: 24 Node12
 SG_ Sig_131_0 : 0|8@1+ (0.25,0) [0|63.75] "%" Node1,Node2
 SG_ Sig_131_1 : 8|8@1+ (1,-40) [-40|215] "degC" Node1,Node2
 SG_ Sig_131_2 : 16|12@1- (0.1,-40) [-244.8|164.7] "rpm" Node1,Node2
 SG_ Sig_131_3 : 28|8@1- (0.01,100) [98.72|101.27] "km/h" Node1,Node2
 SG_ Sig_131_4 : 36|12@1+ (0.25,0) [0|1023.75] "degC" Node1,Node2
 SG_ Sig_131_5 : 48|1@1+ (1,0) [0|1] "" Node1,Node2

BO_ 133 Msg_132: 8 Node1
 SG_ Sig_132_0 : 7|3@0- (0.25,-40) [-41|-39.25] "" Node2
 SG_ Sig_132_1 : 4|3@0+ (2,0) [0|14] "A" Node2
 SG_ Sig_132_2 : 1|3@0+ (0.25,100) [100|101.75] "A" Node2
 SG_ Sig_132_3 : 14|3@0+ (0.01,0) [0|0.07] "rpm" Node2
 SG_ Sig_132_4 : 11|12@0+ (0.1,100) [100|509.5] "" Node2
 SG_ Sig_132_5 : 31|16@0+ (0.01,0) [0|655.35] "A" Node2

BO_ 134 Msg_133: 8 Node2
 SG_ Sig_133_0 : 7|3@0+ (2,-40) [-40|-26] "V" Node3,Node4
 SG_ Sig_133_1 : 4|12@0+ (2,-40) [-40|8150] "%" Node3,Node4
 SG_ Sig_133_2 : 8|8@0+ (0.25,-0.5) [-0.5|63.25] "degC" Node3,Node4
 SG_ Sig_133_3 : 16|2@0+ (2,100) [100|106] "" Node3,Node4
 SG_ Sig_133_4 : 30|2@0+ (0.01,0) [0|0.03] "" Node3,Node4
 SG_ Sig_133_5 : 28|8@0- (1,-40) [-168|87] "A" Node3,Node4

BO_ 135 Msg_134: 24 Node3
 SG_ Sig_134_0 : 0|16@1+ (1,-40) [-40|65495] "A" Node4
 SG_ Sig_134_1 : 16|2@1+ (0.25,-40) [-40|-39.25] "" Node4
 SG_ Sig_134_2 : 18|4@1+ (0.5,100) [100|107.5] "rpm" Node4
 SG_ Sig_134_3 : 22|1@1+ (1,0) [0|1] "" Node4
 SG_ Sig_134_4 : 23|4@1+ (0.25,-40) [-40|-36.25] "" Node4
 SG_ Sig_134_5 : 27|2@1- (0.1,0) [-0.2|0.1] "" Node4

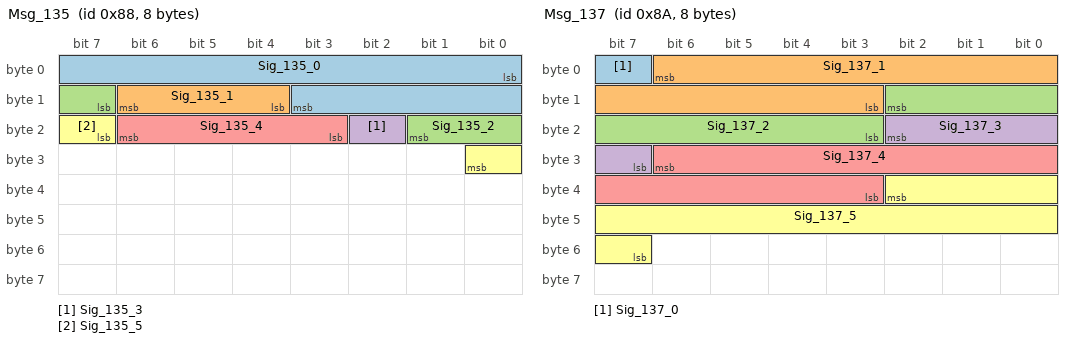
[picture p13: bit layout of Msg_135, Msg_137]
BO_ 136 Msg_135: 8 Node4
 SG_ Sig_135_0 : 0|12@1+ (1,-40) [-40|4055] "degC" Node5,Node6
 SG_ Sig_135_1 : 12|3@1+ (1,100) [100|107] "" Node5,Node6
 SG_ Sig_135_2 : 15|3@1+ (1,0) [0|7] "km/h" Node5,Node6
 SG_ Sig_135_3 : 18|1@1+ (1,0) [0|1] "" Node5,Node6
 SG_ Sig_135_4 : 19|4@1- (2,0) [-16|14] "km/h" Node5,Node6
 SG_ Sig_135_5 : 23|2@1+ (1,100) [100|103] "" Node5,Node6

BO_ 137 Msg_136: 32 Node5
 SG_ Sig_136_0 : 0|8@1+ (1,100) [100|355] "" Node6,Node7
 SG_ Sig_136_1 : 8|8@1- (1,0) [-128|127] "A" Node6,Node7
 SG_ Sig_136_2 : 16|8@1+ (0.1,0) [0|25.5] "V" Node6,Node7
 SG_ Sig_136_3 : 24|8@1+ (1,-0.5) [-0.5|254.5] "degC" Node6,Node7
 SG_ Sig_136_4 : 32|3@1+ (0.25,0) [0|1.75] "V" Node6,Node7
 SG_ Sig_136_5 : 35|8@1+ (1,0) [0|255] "" Node6,Node7

BO_ 138 Msg_137: 8 Node6
 SG_ Sig_137_0 : 7|1@0+ (1,0) [0|1] "" Node7
 SG_ Sig_137_1 : 6|12@0+ (0.01,0) [0|40.95] "km/h" Node7
 SG_ Sig_137_2 : 10|8@0+ (1,-0.5) [-0.5|254.5] "km/h" Node7
 SG_ Sig_137_3 : 18|4@0+ (0.01,100) [100|100.15] "A" Node7
 SG_ Sig_137_4 : 30|12@0- (0.25,0) [-512|511.75] "%" Node7
 SG_ Sig_137_5 : 34|12@0+ (1,0) [0|4095] "V" Node7

BO_ 139 Msg_138: 8 Node7
 SG_ Sig_138_0 : 0|4@1+ (0.01,0) [0|0.15] "km/h" Node8,Node9
 SG_ Sig_138_1 : 4|16@1+ (0.1,0) [0|6553.5] "degC" Node8,Node9
 SG_ Sig_138_2 : 20|16@1+ (0.01,0) [0|655.35] "V" Node8,Node9
 SG_ Sig_138_3 : 36|3@1+ (1,0) [0|7] "degC" Node8,Node9
 SG_ Sig_138_4 : 39|16@1+ (1,-0.5) [-0.5|65534.5] "km/h" Node8,Node9
 SG_ Sig_138_5 : 55|2@1- (0.01,0) [-0.02|0.01] "" Node8,Node9

BO_ 140 Msg_139: 16 Node8
 SG_ Sig_139_0 : 7|16@0+ (0.1,0) [0|6553.5] "A" Node9,Node10
 SG_ Sig_139_1 : 23|8@0+ (0.5,0) [0|127.5] "V" Node9,Node10
 SG_ Sig_139_2 : 31|8@0+ (1,-0.5) [-0.5|254.5] "A" Node9,Node10
 SG_ Sig_139_3 : 39|1@0+ (1,0) [0|1] "" Node9,Node10
 SG_ Sig_139_4 : 38|8@0+ (2,-0.5) [-0.5|509.5] "km/h" Node9,Node10
 SG_ Sig_139_5 : 46|8@0+ (1,-0.5) [-0.5|254.5] "km/h" Node9,Node10

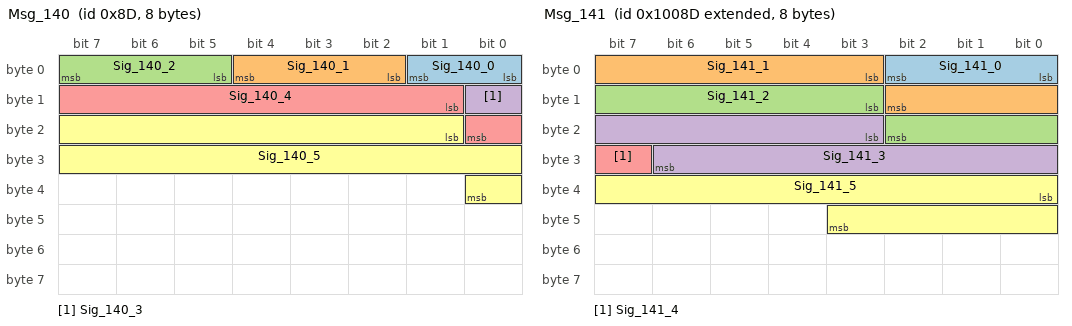
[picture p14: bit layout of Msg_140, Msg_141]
BO_ 141 Msg_140: 8 Node9
 SG_ Sig_140_0 : 0|2@1+ (1,0) [0|3] "" Node10
 SG_ Sig_140_1 : 2|3@1+ (0.1,0) [0|0.7] "degC" Node10
 SG_ Sig_140_2 : 5|3@1+ (1,0) [0|7] "degC" Node10
 SG_ Sig_140_3 : 8|1@1+ (1,0) [0|1] "" Node10
 SG_ Sig_140_4 : 9|8@1+ (1,100) [100|355] "rpm" Node10
 SG_ Sig_140_5 : 17|16@1+ (1,-40) [-40|65495] "km/h" Node10

BO_ 2147549325 Msg_141: 8 Node10
 SG_ Sig_141_0 : 0|3@1+ (2,100) [100|114] "rpm" Node11
 SG_ Sig_141_1 : 3|8@1+ (0.25,100) [100|163.75] "" Node11
 SG_ Sig_141_2 : 11|8@1- (0.25,0) [-32|31.75] "km/h" Node11
 SG_ Sig_141_3 : 19|12@1+ (0.25,0) [0|1023.75] "degC" Node11
 SG_ Sig_141_4 : 31|1@1+ (1,0) [0|1] "" Node11
 SG_ Sig_141_5 : 32|12@1+ (0.5,-0.5) [-0.5|2047] "degC" Node11

BO_ 2147549326 Msg_142: 12 Node11
 SG_ Sig_142_sel M : 0|8@1+ (0.1,0) [0|25.5] "V" Node12
 SG_ Sig_142_a0 m0 : 8|12@1- (0.5,100) [-924|1123.5] "rpm" Node12
 SG_ Sig_142_a1 m0 : 20|1@1+ (1,0) [0|1] "" Node12
 SG_ Sig_142_b0 m1 : 8|2@1+ (1,0) [0|3] "" Node12
 SG_ Sig_142_b1 m1 : 10|12@1+ (1,0) [0|4095] "%" Node12
 SG_ Sig_142_c0 : 40|16@1+ (1,100) [100|65635] "degC" Node12
 SG_ Sig_142_c1 : 56|12@1+ (0.25,0) [0|1023.75] "degC" Node12

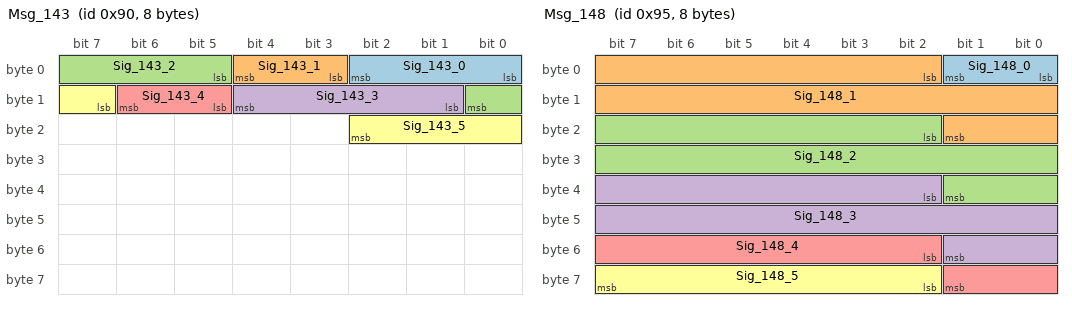
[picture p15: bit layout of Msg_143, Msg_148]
BO_ 144 Msg_143: 8 Node12
 SG_ Sig_143_0 : 0|3@1+ (2,-40) [-40|-26] "%" Node1
 SG_ Sig_143_1 : 3|2@1+ (0.5,0) [0|1.5] "" Node1
 SG_ Sig_143_2 : 5|4@1+ (2,100) [100|130] "V" Node1
 SG_ Sig_143_3 : 9|4@1+ (0.01,100) [100|100.15] "A" Node1
 SG_ Sig_143_4 : 13|2@1- (0.1,-0.5) [-0.7|-0.4] "" Node1
 SG_ Sig_143_5 : 15|4@1+ (0.1,-0.5) [-0.5|1] "A" Node1

BO_ 145 Msg_144: 32 Node1
 SG_ Sig_144_sel M : 0|8@1+ (0.01,0) [0|2.55] "A" Node2,Node3
 SG_ Sig_144_a0 m0 : 8|12@1+ (0.01,0) [0|40.95] "degC" Node2,Node3
 SG_ Sig_144_a1 m0 : 20|12@1+ (0.1,-40) [-40|369.5] "degC" Node2,Node3
 SG_ Sig_144_b0 m1 : 8|3@1- (2,0) [-8|6] "km/h" Node2,Node3
 SG_ Sig_144_b1 m1 : 11|12@1+ (2,-0.5) [-0.5|8189.5] "degC" Node2,Node3
 SG_ Sig_144_c0 : 40|1@1+ (1,0) [0|1] "" Node2,Node3
 SG_ Sig_144_c1 : 41|1@1+ (1,0) [0|1] "" Node2,Node3

BO_ 146 Msg_145: 2 Node2
 SG_ Sig_145_0 : 7|8@0+ (1,-0.5) [-0.5|254.5] "V" Node3,Node4
 SG_ Sig_145_1 : 15|1@0+ (1,0) [0|1] "" Node3,Node4
 SG_ Sig_145_2 : 14|4@0+ (0.01,100) [100|100.15] "V" Node3,Node4
 SG_ Sig_145_3 : 10|3@0+ (0.1,0) [0|0.7] "V" Node3,Node4

BO_ 147 Msg_146: 24 Node3
 SG_ Sig_146_sel M : 0|8@1+ (1,0) [0|255] "%" Node4,Node5
 SG_ Sig_146_a0 m0 : 8|4@1- (1,0) [-8|7] "A" Node4,Node5
 SG_ Sig_146_a1 m0 : 12|2@1+ (1,100) [100|103] "" Node4,Node5
 SG_ Sig_146_b0 m1 : 8|12@1+ (1,0) [0|4095] "V" Node4,Node5
 SG_ Sig_146_b1 m1 : 20|8@1+ (0.25,0) [0|63.75] "degC" Node4,Node5
 SG_ Sig_146_c0 : 40|2@1+ (0.25,0) [0|0.75] "" Node4,Node5
 SG_ Sig_146_c1 : 42|3@1- (1,-0.5) [-4.5|2.5] "%" Node4,Node5

BO_ 148 Msg_147: 8 Node4
 SG_ Sig_147_0 : 0|8@1+ (0.01,0) [0|2.55] "km/h" Node5
 SG_ Sig_147_1 : 8|2@1+ (1,-40) [-40|-37] "" Node5
 SG_ Sig_147_2 : 10|3@1+ (0.5,0) [0|3.5] "A" Node5
 SG_ Sig_147_3 : 13|8@1+ (1,0) [0|255] "degC" Node5
 SG_ Sig_147_4 : 21|16@1+ (2,0) [0|131070] "A" Node5
 SG_ Sig_147_5 : 37|2@1+ (2,100) [100|106] "" Node5

BO_ 149 Msg_148: 8 Node5
 SG_ Sig_148_0 : 0|2@1+ (1,-0.5) [-0.5|2.5] "" Node6,Node7
 SG_ Sig_148_1 : 2|16@1+ (0.01,0) [0|655.35] "" Node6,Node7
 SG_ Sig_148_2 : 18|16@1- (0.25,-40) [-8232|8151.75] "%" Node6,Node7
 SG_ Sig_148_3 : 34|16@1- (0.1,0) [-3276.8|3276.7] "km/h" Node6,Node7
 SG_ Sig_148_4 : 50|8@1+ (1,100) [100|355] "V" Node6,Node7
 SG_ Sig_148_5 : 58|6@1+ (0.01,0) [0|0.63] "A" Node6,Node7

BO_ 2147549333 Msg_149: 32 Node6
 SG_ Sig_149_0 : 0|3@1- (0.5,0) [-2|1.5] "rpm" Node7
 SG_ Sig_149_1 : 3|8@1- (1,0) [-128|127] "rpm" Node7
 SG_ Sig_149_2 : 11|16@1+ (0.25,0) [0|16383.75] "%" Node7
 SG_ Sig_149_3 : 27|1@1+ (1,0) [0|1] "" Node7
 SG_ Sig_149_4 : 28|16@1+ (0.5,100) [100|32867.5] "%" Node7
 SG_ Sig_149_5 : 44|4@1- (0.01,0) [-0.08|0.07] "rpm" Node7

BO_ 151 Msg_150: 6 Node7
 SG_ Sig_150_0 : 0|1@1+ (1,0) [0|1] "" Node8
 SG_ Sig_150_1 : 1|8@1+ (1,-0.5) [-0.5|254.5] "V" Node8
 SG_ Sig_150_2 : 9|4@1- (0.5,0) [-4|3.5] "" Node8
 SG_ Sig_150_3 : 13|8@1+ (0.1,0) [0|25.5] "km/h" Node8
 SG_ Sig_150_4 : 21|3@1+ (1,-40) [-40|-33] "degC" Node8
 SG_ Sig_150_5 : 24|8@1+ (0.1,0) [0|25.5] "A" Node8

BO_ 152 Msg_151: 24 Node8
 SG_ Sig_151_0 : 7|2@0+ (1,100) [100|103] "" Node9,Node10
 SG_ Sig_151_1 : 5|3@0+ (2,-40) [-40|-26] "%" Node9,Node10
 SG_ Sig_151_2 : 2|8@0+ (1,-0.5) [-0.5|254.5] "A" Node9,Node10
 SG_ Sig_151_3 : 10|8@0+ (2,100) [100|610] "A" Node9,Node10
 SG_ Sig_151_4 : 18|1@0+ (1,0) [0|1] "" Node9,Node10
 SG_ Sig_151_5 : 17|8@0+ (1,0) [0|255] "%" Node9,Node10

BO_ 153 Msg_152: 12 Node9
 SG_ Sig_152_0 : 7|12@0+ (2,0) [0|8190] "degC" Node10,Node11
 SG_ Sig_152_1 : 11|8@0+ (0.1,0) [0|25.5] "V" Node10,Node11
 SG_ Sig_152_2 : 19|3@0- (0.01,0) [-0.04|0.03] "km/h" Node10,Node11
 SG_ Sig_152_3 : 16|2@0- (0.01,0) [-0.02|0.01] "" Node10,Node11
 SG_ Sig_152_4 : 30|3@0+ (2,100) [100|114] "%" Node10,Node11
 SG_ Sig_152_5 : 27|16@0- (2,-40) [-65576|65494] "V" Node10,Node11

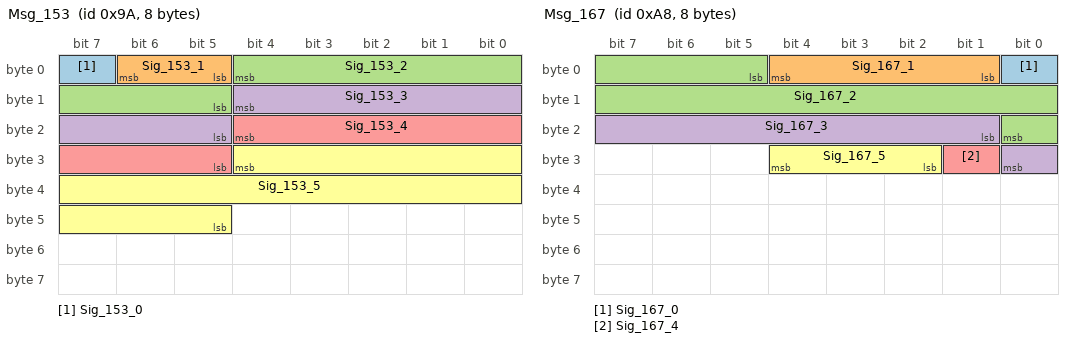
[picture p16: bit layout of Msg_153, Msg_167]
BO_ 154 Msg_153: 8 Node10
 SG_ Sig_153_0 : 7|1@0+ (1,0) [0|1] "" Node11
 SG_ Sig_153_1 : 6|2@0- (1,0) [-2|1] "" Node11
 SG_ Sig_153_2 : 4|8@0- (1,-40) [-168|87] "km/h" Node11
 SG_ Sig_153_3 : 12|8@0+ (1,0) [0|255] "V" Node11
 SG_ Sig_153_4 : 20|8@0+ (0.1,100) [100|125.5] "degC" Node11
 SG_ Sig_153_5 : 28|16@0+ (0.01,0) [0|655.35] "" Node11

BO_ 155 Msg_154: 32 Node11
 SG_ Sig_154_0 : 7|2@0- (2,0) [-4|2] "" Node12
 SG_ Sig_154_1 : 5|2@0+ (0.1,0) [0|0.3] "" Node12
 SG_ Sig_154_2 : 3|8@0+ (0.5,0) [0|127.5] "A" Node12
 SG_ Sig_154_3 : 11|2@0+ (0.25,-40) [-40|-39.25] "" Node12
 SG_ Sig_154_4 : 9|8@0- (0.25,-0.5) [-32.5|31.25] "A" Node12
 SG_ Sig_154_5 : 17|4@0+ (2,100) [100|130] "" Node12

BO_ 156 Msg_155: 32 Node12
 SG_ Sig_155_0 : 7|2@0+ (0.1,-40) [-40|-39.7] "" Node1
 SG_ Sig_155_1 : 5|8@0+ (0.5,-0.5) [-0.5|127] "A" Node1
 SG_ Sig_155_2 : 13|16@0- (0.01,0) [-327.68|327.67] "degC" Node1
 SG_ Sig_155_3 : 29|8@0- (0.1,-0.5) [-13.3|12.2] "%" Node1
 SG_ Sig_155_4 : 37|12@0+ (1,-40) [-40|4055] "degC" Node1
 SG_ Sig_155_5 : 41|1@0+ (1,0) [0|1] "" Node1

BO_ 157 Msg_156: 16 Node1
 SG_ Sig_156_0 : 7|16@0+ (0.01,100) [100|755.35] "rpm" Node2
 SG_ Sig_156_1 : 23|4@0- (0.25,-40) [-42|-38.25] "%" Node2
 SG_ Sig_156_2 : 19|4@0- (0.1,0) [-0.8|0.7] "degC" Node2
 SG_ Sig_156_3 : 31|2@0- (1,-0.5) [-2.5|0.5] "" Node2
 SG_ Sig_156_4 : 29|4@0+ (0.1,0) [0|1.5] "V" Node2
 SG_ Sig_156_5 : 25|4@0+ (1,100) [100|115] "degC" Node2

BO_ 158 Msg_157: 8 Node2
 SG_ Sig_157_0 : 7|8@0+ (0.01,100) [100|102.55] "rpm" Node3
 SG_ Sig_157_1 : 15|4@0+ (0.5,0) [0|7.5] "V" Node3
 SG_ Sig_157_2 : 11|1@0+ (1,0) [0|1] "" Node3
 SG_ Sig_157_3 : 10|1@0+ (1,0) [0|1] "" Node3
 SG_ Sig_157_4 : 9|1@0+ (1,0) [0|1] "" Node3
 SG_ Sig_157_5 : 8|16@0+ (1,0) [0|65535] "%" Node3

BO_ 159 Msg_158: 32 Node3
 SG_ Sig_158_0 : 0|8@1+ (0.5,0) [0|127.5] "km/h" Node4
 SG_ Sig_158_1 : 8|2@1+ (2,-0.5) [-0.5|5.5] "" Node4
 SG_ Sig_158_2 : 10|4@1+ (0.01,100) [100|100.15] "degC" Node4
 SG_ Sig_158_3 : 14|8@1+ (1,0) [0|255] "km/h" Node4
 SG_ Sig_158_4 : 22|4@1+ (1,-0.5) [-0.5|14.5] "A" Node4
 SG_ Sig_158_5 : 26|3@1+ (0.1,-40) [-40|-39.3] "V" Node4

BO_ 160 Msg_159: 8 Node4
 SG_ Sig_159_0 : 7|8@0+ (0.01,0) [0|2.55] "" Node5
 SG_ Sig_159_1 : 15|2@0+ (1,-0.5) [-0.5|2.5] "" Node5
 SG_ Sig_159_2 : 13|8@0- (1,0) [-128|127] "degC" Node5
 SG_ Sig_159_3 : 21|2@0+ (1,-0.5) [-0.5|2.5] "" Node5
 SG_ Sig_159_4 : 19|1@0+ (1,0) [0|1] "" Node5
 SG_ Sig_159_5 : 18|8@0- (2,0) [-256|254] "km/h" Node5

BO_ 2147549344 Msg_160: 12 Node5
 SG_ Sig_160_sel M : 0|8@1+ (0.01,0) [0|2.55] "degC" Node6,Node7
 SG_ Sig_160_a0 m0 : 8|4@1+ (1,0) [0|15] "" Node6,Node7
 SG_ Sig_160_a1 m0 : 12|16@1+ (0.1,100) [100|6653.5] "km/h" Node6,Node7
 SG_ Sig_160_b0 m1 : 8|8@1- (0.01,0) [-1.28|1.27] "rpm" Node6,Node7
 SG_ Sig_160_b1 m1 : 16|3@1+ (0.1,0) [0|0.7] "%" Node6,Node7
 SG_ Sig_160_c0 : 40|8@1- (0.01,100) [98.72|101.27] "" Node6,Node7
 SG_ Sig_160_c1 : 48|12@1+ (0.5,0) [0|2047.5] "degC" Node6,Node7

BO_ 162 Msg_161: 8 Node6
 SG_ Sig_161_0 : 0|2@1+ (1,-0.5) [-0.5|2.5] "" Node7
 SG_ Sig_161_1 : 2|8@1+ (1,-40) [-40|215] "degC" Node7
 SG_ Sig_161_2 : 10|12@1+ (1,0) [0|4095] "%" Node7
 SG_ Sig_161_3 : 22|2@1+ (1,-40) [-40|-37] "" Node7
 SG_ Sig_161_4 : 24|8@1+ (0.25,0) [0|63.75] "%" Node7
 SG_ Sig_161_5 : 32|12@1- (1,-40) [-2088|2007] "A" Node7

BO_ 163 Msg_162: 8 Node7
 SG_ Sig_162_0 : 0|16@1+ (1,-0.5) [-0.5|65534.5] "degC" Node8
 SG_ Sig_162_1 : 16|4@1+ (0.1,0) [0|1.5] "degC" Node8
 SG_ Sig_162_2 : 20|4@1- (0.25,0) [-2|1.75] "km/h" Node8
 SG_ Sig_162_3 : 24|3@1- (0.5,0) [-2|1.5] "V" Node8
 SG_ Sig_162_4 : 27|4@1- (0.1,-0.5) [-1.3|0.2] "%" Node8
 SG_ Sig_162_5 : 31|8@1+ (0.1,0) [0|25.5] "degC" Node8

BO_ 164 Msg_163: 8 Node8
 SG_ Sig_163_0 : 0|16@1+ (0.1,-40) [-40|6513.5] "rpm" Node9
 SG_ Sig_163_1 : 16|3@1+ (1,-40) [-40|-33] "A" Node9
 SG_ Sig_163_2 : 19|4@1+ (0.01,0) [0|0.15] "km/h" Node9
 SG_ Sig_163_3 : 23|8@1- (1,0) [-128|127] "km/h" Node9
 SG_ Sig_163_4 : 31|4@1+ (2,-0.5) [-0.5|29.5] "%" Node9
 SG_ Sig_163_5 : 35|16@1+ (0.01,0) [0|655.35] "rpm" Node9

BO_ 2147549348 Msg_164: 24 Node9
 SG_ Sig_164_0 : 0|8@1+ (2,0) [0|510] "" Node10
 SG_ Sig_164_1 : 8|2@1+ (0.01,100) [100|100.03] "" Node10
 SG_ Sig_164_2 : 10|8@1+ (0.5,100) [100|227.5] "V" Node10
 SG_ Sig_164_3 : 18|12@1+ (0.01,0) [0|40.95] "rpm" Node10
 SG_ Sig_164_4 : 30|1@1+ (1,0) [0|1] "" Node10
 SG_ Sig_164_5 : 31|2@1- (1,-0.5) [-2.5|0.5] "" Node10

BO_ 166 Msg_165: 12 Node10
 SG_ Sig_165_0 : 7|12@0+ (2,0) [0|8190] "rpm" Node11
 SG_ Sig_165_1 : 11|12@0+ (0.01,-0.5) [-0.5|40.45] "%" Node11
 SG_ Sig_165_2 : 31|12@0+ (0.5,100) [100|2147.5] "V" Node11
 SG_ Sig_165_3 : 35|3@0+ (1,0) [0|7] "degC" Node11
 SG_ Sig_165_4 : 32|12@0+ (0.01,0) [0|40.95] "rpm" Node11
 SG_ Sig_165_5 : 52|16@0+ (0.25,0) [0|16383.75] "km/h" Node11

BO_ 167 Msg_166: 8 Node11
 SG_ Sig_166_0 : 7|4@0- (0.5,0) [-4|3.5] "degC" Node12,Node1
 SG_ Sig_166_1 : 3|12@0+ (0.25,-0.5) [-0.5|1023.25] "V" Node12,Node1
 SG_ Sig_166_2 : 23|16@0- (0.01,-0.5) [-328.18|327.17] "V" Node12,Node1
 SG_ Sig_166_3 : 39|12@0+ (1,-40) [-40|4055] "rpm" Node12,Node1
 SG_ Sig_166_4 : 43|16@0+ (1,-0.5) [-0.5|65534.5] "V" Node12,Node1
 SG_ Sig_166_5 : 59|3@0+ (1,0) [0|7] "rpm" Node12,Node1

BO_ 168 Msg_167: 8 Node12
 SG_ Sig_167_0 : 0|1@1+ (1,0) [0|1] "" Node1
 SG_ Sig_167_1 : 1|4@1+ (0.5,100) [100|107.5] "V" Node1
 SG_ Sig_167_2 : 5|12@1+ (2,-40) [-40|8150] "V" Node1
 SG_ Sig_167_3 : 17|8@1+ (2,0) [0|510] "%" Node1
 SG_ Sig_167_4 : 25|1@1+ (1,0) [0|1] "" Node1
 SG_ Sig_167_5 : 26|3@1+ (0.1,0) [0|0.7] "A" Node1

BO_ 169 Msg_168: 12 Node1
 SG_ Sig_168_0 : 7|1@0+ (1,0) [0|1] "" Node2,Node3
 SG_ Sig_168_1 : 6|8@0+ (2,0) [0|510] "%" Node2,Node3
 SG_ Sig_168_2 : 14|2@0+ (1,-40) [-40|-37] "" Node2,Node3
 SG_ Sig_168_3 : 12|3@0+ (2,0) [0|14] "%" Node2,Node3
 SG_ Sig_168_4 : 9|2@0- (0.5,0) [-1|0.5] "" Node2,Node3
 SG_ Sig_168_5 : 23|1@0+ (1,0) [0|1] "" Node2,Node3

BO_ 170 Msg_169: 12 Node2
 SG_ Sig_169_0 : 0|8@1- (2,0) [-256|254] "rpm" Node3,Node4
 SG_ Sig_169_1 : 8|2@1- (1,-0.5) [-2.5|0.5] "" Node3,Node4
 SG_ Sig_169_2 : 10|8@1- (0.5,0) [-64|63.5] "" Node3,Node4
 SG_ Sig_169_3 : 18|1@1+ (1,0) [0|1] "" Node3,Node4
 SG_ Sig_169_4 : 19|8@1+ (0.1,0) [0|25.5] "degC" Node3,Node4
 SG_ Sig_169_5 : 27|3@1+ (2,-40) [-40|-26] "A" Node3,Node4

BO_ 171 Msg_170: 12 Node3
 SG_ Sig_170_0 : 7|12@0+ (0.1,-0.5) [-0.5|409] "" Node4
 SG_ Sig_170_1 : 11|12@0+ (1,0) [0|4095] "degC" Node4
 SG_ Sig_170_2 : 31|2@0+ (0.25,0) [0|0.75] "" Node4
 SG_ Sig_170_3 : 29|16@0+ (0.01,-40) [-40|615.35] "" Node4
 SG_ Sig_170_4 : 45|8@0+ (0.01,-40) [-40|-37.45] "A" Node4
 SG_ Sig_170_5 : 53|4@0+ (0.5,0) [0|7.5] "rpm" Node4

BO_ 172 Msg_171: 2 Node4
 SG_ Sig_171_0 : 0|2@1+ (1,100) [100|103] "" Node5
 SG_ Sig_171_1 : 2|1@1+ (1,0) [0|1] "" Node5
 SG_ Sig_171_2 : 3|4@1+ (0.1,0) [0|1.5] "" Node5
 SG_ Sig_171_3 : 7|9@1- (0.25,-0.5) [-64.5|63.25] "%" Node5

BO_ 173 Msg_172: 32 Node5
 SG_ Sig_172_0 : 7|16@0+ (1,-0.5) [-0.5|65534.5] "degC" Node6,Node7
 SG_ Sig_172_1 : 23|4@0+ (1,0) [0|15] "" Node6,Node7
 SG_ Sig_172_2 : 19|8@0- (2,-40) [-296|214] "degC" Node6,Node7
 SG_ Sig_172_3 : 27|3@0+ (0.5,0) [0|3.5] "V" Node6,Node7
 SG_ Sig_172_4 : 24|8@0+ (0.25,-40) [-40|23.75] "degC" Node6,Node7
 SG_ Sig_172_5 : 32|3@0+ (0.01,0) [0|0.07] "rpm" Node6,Node7

BO_ 174 Msg_173: 24 Node6
 SG_ Sig_173_0 : 0|16@1- (2,0) [-65536|65534] "km/h" Node7,Node8
 SG_ Sig_173_1 : 16|1@1+ (1,0) [0|1] "" Node7,Node8
 SG_ Sig_173_2 : 17|1@1+ (1,0) [0|1] "" Node7,Node8
 SG_ Sig_173_3 : 18|3@1+ (0.1,0) [0|0.7] "rpm" Node7,Node8
 SG_ Sig_173_4 : 21|4@1- (0.25,-40) [-42|-38.25] "degC" Node7,Node8
 SG_ Sig_173_5 : 25|16@1- (0.25,0) [-8192|8191.75] "km/h" Node7,Node8

BO_ 175 Msg_174: 2 Node7
 SG_ Sig_174_0 : 0|1@1+ (1,0) [0|1] "" Node8,Node9
 SG_ Sig_174_1 : 1|15@1- (0.1,-0.5) [-1638.9|1637.8] "rpm" Node8,Node9

BO_ 2147549359 Msg_175: 8 Node8
 SG_ Sig_175_0 : 0|4@1- (1,0) [-8|7] "degC" Node9,Node10
 SG_ Sig_175_1 : 4|16@1+ (1,0) [0|65535] "degC" Node9,Node10
 SG_ Sig_175_2 : 20|4@1+ (0.1,0) [0|1.5] "km/h" Node9,Node10
 SG_ Sig_175_3 : 24|16@1+ (2,100) [100|131170] "km/h" Node9,Node10
 SG_ Sig_175_4 : 40|8@1+ (1,0) [0|255] "rpm" Node9,Node10
 SG_ Sig_175_5 : 48|3@1+ (2,-0.5) [-0.5|13.5] "A" Node9,Node10

BO_ 2147549360 Msg_176: 24 Node9
 SG_ Sig_176_0 : 0|4@1- (1,-0.5) [-8.5|6.5] "rpm" Node10,Node11
 SG_ Sig_176_1 : 4|16@1- (0.1,0) [-3276.8|3276.7] "A" Node10,Node11
 SG_ Sig_176_2 : 20|8@1+ (1,0) [0|255] "km/h" Node10,Node11
 SG_ Sig_176_3 : 28|3@1- (1,0) [-4|3] "km/h" Node10,Node11
 SG_ Sig_176_4 : 31|3@1+ (2,100) [100|114] "%" Node10,Node11
 SG_ Sig_176_5 : 34|16@1+ (0.1,100) [100|6653.5] "rpm" Node10,Node11

BO_ 178 Msg_177: 24 Node10
 SG_ Sig_177_0 : 7|1@0+ (1,0) [0|1] "" Node11,Node12
 SG_ Sig_177_1 : 6|8@0+ (0.5,-0.5) [-0.5|127] "km/h" Node11,Node12
 SG_ Sig_177_2 : 14|1@0+ (1,0) [0|1] "" Node11,Node12
 SG_ Sig_177_3 : 13|8@0+ (2,0) [0|510] "rpm" Node11,Node12
 SG_ Sig_177_4 : 21|8@0+ (0.5,-0.5) [-0.5|127] "%" Node11,Node12
 SG_ Sig_177_5 : 29|1@0+ (1,0) [0|1] "" Node11,Node12

BO_ 179 Msg_178: 64 Node11
 SG_ Sig_178_0 : 7|3@0+ (2,0) [0|14] "%" Node12
 SG_ Sig_178_1 : 4|2@0+ (0.1,0) [0|0.3] "" Node12
 SG_ Sig_178_2 : 2|2@0+ (0.01,0) [0|0.03] "" Node12
 SG_ Sig_178_3 : 0|8@0+ (0.1,0) [0|25.5] "%" Node12
 SG_ Sig_178_4 : 8|12@0- (0.01,100) [79.52|120.47] "degC" Node12
 SG_ Sig_178_5 : 28|1@0+ (1,0) [0|1] "" Node12

BO_ 180 Msg_179: 16 Node12
 SG_ Sig_179_0 : 0|3@1+ (1,0) [0|7] "%" Node1
 SG_ Sig_179_1 : 3|4@1+ (1,-40) [-40|-25] "%" Node1
 SG_ Sig_179_2 : 7|12@1+ (1,0) [0|4095] "degC" Node1
 SG_ Sig_179_3 : 19|12@1- (1,-0.5) [-2048.5|2046.5] "V" Node1
 SG_ Sig_179_4 : 31|3@1+ (0.5,-40) [-40|-36.5] "%" Node1
 SG_ Sig_179_5 : 34|8@1+ (1,-40) [-40|215] "" Node1

BO_ 181 Msg_180: 8 Node1
 SG_ Sig_180_0 : 0|3@1+ (0.01,0) [0|0.07] "rpm" Node2
 SG_ Sig_180_1 : 3|1@1+ (1,0) [0|1] "" Node2
 SG_ Sig_180_2 : 4|12@1+ (0.1,0) [0|409.5] "A" Node2
 SG_ Sig_180_3 : 16|8@1+ (0.01,0) [0|2.55] "%" Node2
 SG_ Sig_180_4 : 24|2@1- (0.1,0) [-0.2|0.1] "" Node2
 SG_ Sig_180_5 : 26|8@1- (1,0) [-128|127] "rpm" Node2

BO_ 182 Msg_181: 2 Node2
 SG_ Sig_181_0 : 0|4@1+ (2,0) [0|30] "km/h" Node3
 SG_ Sig_181_1 : 4|2@1+ (0.5,-40) [-40|-38.5] "" Node3
 SG_ Sig_181_2 : 6|8@1+ (0.5,100) [100|227.5] "A" Node3
 SG_ Sig_181_3 : 14|2@1+ (0.5,0) [0|1.5] "" Node3

BO_ 183 Msg_182: 8 Node3
 SG_ Sig_182_0 : 0|8@1+ (0.5,0) [0|127.5] "degC" Node4
 SG_ Sig_182_1 : 8|1@1+ (1,0) [0|1] "" Node4
 SG_ Sig_182_2 : 9|8@1+ (0.01,0) [0|2.55] "" Node4
 SG_ Sig_182_3 : 17|16@1+ (1,0) [0|65535] "" Node4
 SG_ Sig_182_4 : 33|8@1+ (1,0) [0|255] "" Node4
 SG_ Sig_182_5 : 41|8@1+ (2,0) [0|510] "" Node4

BO_ 184 Msg_183: 8 Node4
 SG_ Sig_183_sel M : 0|8@1+ (0.25,-40) [-40|23.75] "A" Node5
 SG_ Sig_183_a0 m0 : 8|16@1+ (2,-0.5) [-0.5|131069.5] "rpm" Node5
 SG_ Sig_183_a1 m0 : 24|4@1- (0.01,0) [-0.08|0.07] "V" Node5
 SG_ Sig_183_b0 m1 : 8|1@1+ (1,0) [0|1] "" Node5
 SG_ Sig_183_b1 m1 : 9|16@1+ (1,0) [0|65535] "degC" Node5
 SG_ Sig_183_c0 : 40|1@1+ (1,0) [0|1] "" Node5
 SG_ Sig_183_c1 : 41|3@1+ (2,-40) [-40|-26] "%" Node5

BO_ 185 Msg_184: 4 Node5
 SG_ Sig_184_0 : 0|16@1+ (1,0) [0|65535] "km/h" Node6,Node7
 SG_ Sig_184_1 : 16|12@1+ (1,0) [0|4095] "A" Node6,Node7
 SG_ Sig_184_2 : 28|2@1+ (2,-40) [-40|-34] "" Node6,Node7
 SG_ Sig_184_3 : 30|1@1+ (1,0) [0|1] "" Node6,Node7
 SG_ Sig_184_4 : 31|1@1+ (1,0) [0|1] "" Node6,Node7

BO_ 186 Msg_185: 64 Node6
 SG_ Sig_185_0 : 0|8@1- (2,-0.5) [-256.5|253.5] "" Node7
 SG_ Sig_185_1 : 8|16@1+ (0.25,0) [0|16383.75] "" Node7
 SG_ Sig_185_2 : 24|8@1+ (1,-40) [-40|215] "A" Node7
 SG_ Sig_185_3 : 32|12@1+ (0.01,-0.5) [-0.5|40.45] "rpm" Node7
 SG_ Sig_185_4 : 44|3@1+ (0.1,-40) [-40|-39.3] "" Node7
 SG_ Sig_185_5 : 47|16@1+ (2,0) [0|131070] "km/h" Node7

BO_ 187 Msg_186: 6 Node7
 SG_ Sig_186_0 : 0|16@1- (0.5,-0.5) [-16384.5|16383] "rpm" Node8,Node9
 SG_ Sig_186_1 : 16|3@1+ (1,0) [0|7] "rpm" Node8,Node9
 SG_ Sig_186_2 : 19|3@1+ (2,0) [0|14] "" Node8,Node9
 SG_ Sig_186_3 : 22|4@1- (1,-0.5) [-8.5|6.5] "A" Node8,Node9
 SG_ Sig_186_4 : 26|8@1+ (2,0) [0|510] "" Node8,Node9
 SG_ Sig_186_5 : 34|2@1+ (0.01,0) [0|0.03] "" Node8,Node9

BO_ 188 Msg_187: 2 Node8
 SG_ Sig_187_0 : 0|2@1- (0.1,0) [-0.2|0.1] "" Node9
 SG_ Sig_187_1 : 2|3@1+ (0.5,0) [0|3.5] "km/h" Node9
 SG_ Sig_187_2 : 5|8@1+ (0.25,100) [100|163.75] "" Node9
 SG_ Sig_187_3 : 13|3@1+ (0.25,-40) [-40|-38.25] "%" Node9

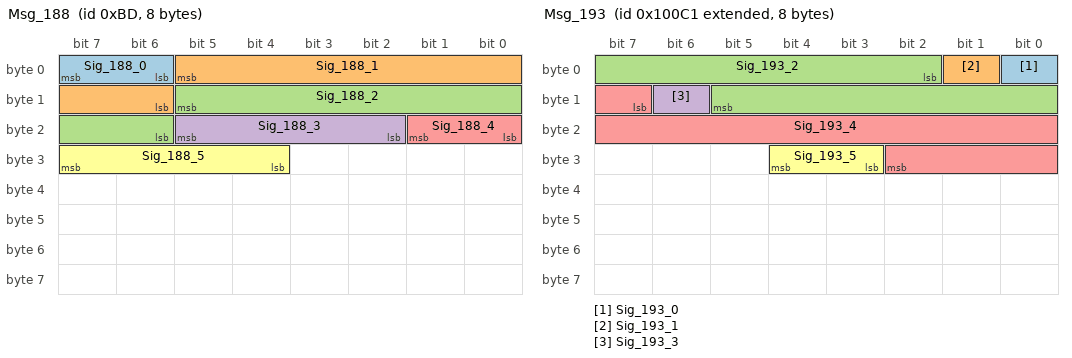
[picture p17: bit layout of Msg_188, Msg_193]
BO_ 189 Msg_188: 8 Node9
 SG_ Sig_188_0 : 7|2@0+ (0.01,0) [0|0.03] "" Node10
 SG_ Sig_188_1 : 5|8@0+ (1,-40) [-40|215] "degC" Node10
 SG_ Sig_188_2 : 13|8@0+ (1,0) [0|255] "rpm" Node10
 SG_ Sig_188_3 : 21|4@0+ (0.01,0) [0|0.15] "A" Node10
 SG_ Sig_188_4 : 17|2@0+ (2,-40) [-40|-34] "" Node10
 SG_ Sig_188_5 : 31|4@0- (1,-0.5) [-8.5|6.5] "%" Node10

BO_ 2147549373 Msg_189: 4 Node10
 SG_ Sig_189_0 : 7|2@0+ (0.5,100) [100|101.5] "" Node11,Node12
 SG_ Sig_189_1 : 5|8@0- (0.1,100) [87.2|112.7] "degC" Node11,Node12
 SG_ Sig_189_2 : 13|16@0+ (0.1,-40) [-40|6513.5] "%" Node11,Node12
 SG_ Sig_189_3 : 29|6@0+ (2,0) [0|126] "A" Node11,Node12

BO_ 191 Msg_190: 16 Node11
 SG_ Sig_190_0 : 0|12@1+ (0.5,-40) [-40|2007.5] "V" Node12,Node1
 SG_ Sig_190_1 : 12|16@1+ (0.5,0) [0|32767.5] "rpm" Node12,Node1
 SG_ Sig_190_2 : 28|16@1+ (2,0) [0|131070] "km/h" Node12,Node1
 SG_ Sig_190_3 : 44|12@1+ (0.01,0) [0|40.95] "V" Node12,Node1
 SG_ Sig_190_4 : 56|3@1+ (1,-40) [-40|-33] "degC" Node12,Node1
 SG_ Sig_190_5 : 59|4@1+ (0.1,-40) [-40|-38.5] "rpm" Node12,Node1

BO_ 192 Msg_191: 2 Node12
 SG_ Sig_191_0 : 7|8@0- (0.01,100) [98.72|101.27] "degC" Node1,Node2
 SG_ Sig_191_1 : 15|8@0+ (0.1,0) [0|25.5] "V" Node1,Node2

BO_ 193 Msg_192: 32 Node1
 SG_ Sig_192_0 : 0|3@1+ (1,-40) [-40|-33] "" Node2
 SG_ Sig_192_1 : 3|3@1+ (0.01,0) [0|0.07] "A" Node2
 SG_ Sig_192_2 : 6|8@1+ (1,-0.5) [-0.5|254.5] "%" Node2
 SG_ Sig_192_3 : 14|4@1+ (1,0) [0|15] "rpm" Node2
 SG_ Sig_192_4 : 18|2@1- (1,100) [98|101] "" Node2
 SG_ Sig_192_5 : 20|8@1+ (1,-40) [-40|215] "km/h" Node2

BO_ 2147549377 Msg_193: 8 Node2
 SG_ Sig_193_0 : 0|1@1+ (1,0) [0|1] "" Node3
 SG_ Sig_193_1 : 1|1@1+ (1,0) [0|1] "" Node3
 SG_ Sig_193_2 : 2|12@1+ (1,-40) [-40|4055] "" Node3
 SG_ Sig_193_3 : 14|1@1+ (1,0) [0|1] "" Node3
 SG_ Sig_193_4 : 15|12@1- (0.01,0) [-20.48|20.47] "" Node3
 SG_ Sig_193_5 : 27|2@1+ (0.01,0) [0|0.03] "" Node3

BO_ 195 Msg_194: 8 Node3
 SG_ Sig_194_0 : 0|8@1+ (0.25,-0.5) [-0.5|63.25] "" Node4
 SG_ Sig_194_1 : 8|16@1+ (1,100) [100|65635] "%" Node4
 SG_ Sig_194_2 : 24|8@1+ (0.01,0) [0|2.55] "km/h" Node4
 SG_ Sig_194_3 : 32|4@1+ (1,0) [0|15] "km/h" Node4
 SG_ Sig_194_4 : 36|4@1- (0.25,-40) [-42|-38.25] "V" Node4
 SG_ Sig_194_5 : 40|3@1+ (1,-0.5) [-0.5|6.5] "degC" Node4

BO_ 196 Msg_195: 64 Node4
 SG_ Sig_195_0 : 0|8@1+ (1,-0.5) [-0.5|254.5] "" Node5
 SG_ Sig_195_1 : 8|16@1+ (2,-40) [-40|131030] "%" Node5
 SG_ Sig_195_2 : 24|2@1+ (0.25,0) [0|0.75] "" Node5
 SG_ Sig_195_3 : 26|3@1+ (0.5,0) [0|3.5] "V" Node5
 SG_ Sig_195_4 : 29|8@1+ (0.01,0) [0|2.55] "degC" Node5
 SG_ Sig_195_5 : 37|12@1+ (1,100) [100|4195] "" Node5

BO_ 197 Msg_196: 12 Node5
 SG_ Sig_196_0 : 7|3@0- (1,100) [96|103] "A" Node6
 SG_ Sig_196_1 : 4|4@0+ (0.25,0) [0|3.75] "%" Node6
 SG_ Sig_196_2 : 0|4@0+ (2,0) [0|30] "V" Node6
 SG_ Sig_196_3 : 12|8@0+ (1,100) [100|355] "degC" Node6
 SG_ Sig_196_4 : 20|2@0+ (0.25,0) [0|0.75] "" Node6
 SG_ Sig_196_5 : 18|8@0+ (0.25,100) [100|163.75] "" Node6

BO_ 198 Msg_197: 8 Node6
 SG_ Sig_197_0 : 0|16@1+ (0.5,-40) [-40|32727.5] "rpm" Node7
 SG_ Sig_197_1 : 16|1@1+ (1,0) [0|1] "" Node7
 SG_ Sig_197_2 : 17|16@1+ (1,-0.5) [-0.5|65534.5] "%" Node7
 SG_ Sig_197_3 : 33|12@1+ (0.5,-0.5) [-0.5|2047] "%" Node7
 SG_ Sig_197_4 : 45|4@1+ (1,0) [0|15] "degC" Node7
 SG_ Sig_197_5 : 49|2@1+ (0.01,0) [0|0.03] "" Node7

BO_ 199 Msg_198: 24 Node7
 SG_ Sig_198_sel M : 0|8@1+ (0.25,-0.5) [-0.5|63.25] "V" Node8
 SG_ Sig_198_a0 m0 : 8|8@1+ (0.1,-0.5) [-0.5|25] "%" Node8
 SG_ Sig_198_a1 m0 : 16|12@1- (2,-0.5) [-4096.5|4093.5] "km/h" Node8
 SG_ Sig_198_b0 m1 : 8|2@1- (0.25,100) [99.5|100.25] "" Node8
 SG_ Sig_198_b1 m1 : 10|1@1+ (1,0) [0|1] "" Node8
 SG_ Sig_198_c0 : 40|3@1- (0.25,0) [-1|0.75] "V" Node8
 SG_ Sig_198_c1 : 43|12@1- (0.01,100) [79.52|120.47] "V" Node8

BO_ 200 Msg_199: 8 Node8
 SG_ Sig_199_0 : 7|16@0+ (1,0) [0|65535] "A" Node9,Node10
 SG_ Sig_199_1 : 23|4@0- (1,0) [-8|7] "" Node9,Node10
 SG_ Sig_199_2 : 19|8@0+ (2,100) [100|610] "" Node9,Node10
 SG_ Sig_199_3 : 27|4@0- (0.5,100) [96|103.5] "km/h" Node9,Node10
 SG_ Sig_199_4 : 39|12@0- (1,0) [-2048|2047] "degC" Node9,Node10
 SG_ Sig_199_5 : 43|3@0+ (0.01,-0.5) [-0.5|-0.43] "A" Node9,Node10

BO_ 201 Msg_200: 24 Node9
 SG_ Sig_200_0 : 0|16@1- (0.1,-0.5) [-3277.3|3276.2] "V" Node10
 SG_ Sig_200_1 : 16|1@1+ (1,0) [0|1] "" Node10
 SG_ Sig_200_2 : 17|8@1- (0.5,100) [36|163.5] "km/h" Node10
 SG_ Sig_200_3 : 25|3@1+ (1,-0.5) [-0.5|6.5] "V" Node10
 SG_ Sig_200_4 : 28|16@1+ (0.25,-0.5) [-0.5|16383.25] "A" Node10
 SG_ Sig_200_5 : 44|4@1+ (0.5,-40) [-40|-32.5] "" Node10

BO_ 202 Msg_201: 8 Node10
 SG_ Sig_201_0 : 7|16@0+ (0.01,0) [0|655.35] "rpm" Node11,Node12
 SG_ Sig_201_1 : 23|2@0+ (2,0) [0|6] "" Node11,Node12
 SG_ Sig_201_2 : 21|8@0- (0.5,-40) [-104|23.5] "km/h" Node11,Node12
 SG_ Sig_201_3 : 29|1@0+ (1,0) [0|1] "" Node11,Node12
 SG_ Sig_201_4 : 28|2@0+ (0.25,0) [0|0.75] "" Node11,Node12
 SG_ Sig_201_5 : 26|4@0+ (2,-40) [-40|-10] "rpm" Node11,Node12

BO_ 2147549386 Msg_202: 16 Node11
 SG_ Sig_202_0 : 7|8@0+ (1,-40) [-40|215] "degC" Node12
 SG_ Sig_202_1 : 15|2@0+ (2,-0.5) [-0.5|5.5] "" Node12
 SG_ Sig_202_2 : 13|1@0+ (1,0) [0|1] "" Node12
 SG_ Sig_202_3 : 12|8@0- (0.5,0) [-64|63.5] "" Node12
 SG_ Sig_202_4 : 20|2@0+ (0.25,0) [0|0.75] "" Node12
 SG_ Sig_202_5 : 18|2@0+ (0.01,0) [0|0.03] "" Node12

BO_ 204 Msg_203: 2 Node12
 SG_ Sig_203_0 : 0|1@1+ (1,0) [0|1] "" Node1
 SG_ Sig_203_1 : 1|12@1+ (0.25,-0.5) [-0.5|1023.25] "%" Node1
 SG_ Sig_203_2 : 13|1@1+ (1,0) [0|1] "" Node1
 SG_ Sig_203_3 : 14|2@1+ (0.25,0) [0|0.75] "" Node1

BO_ 205 Msg_204: 16 Node1
 SG_ Sig_204_0 : 0|8@1+ (2,-40) [-40|470] "V" Node2,Node3
 SG_ Sig_204_1 : 8|3@1+ (0.5,100) [100|103.5] "" Node2,Node3
 SG_ Sig_204_2 : 11|2@1+ (1,100) [100|103] "" Node2,Node3
 SG_ Sig_204_3 : 13|8@1+ (2,-0.5) [-0.5|509.5] "A" Node2,Node3
 SG_ Sig_204_4 : 21|4@1+ (1,100) [100|115] "" Node2,Node3
 SG_ Sig_204_5 : 25|4@1- (0.25,0) [-2|1.75] "%" Node2,Node3

BO_ 206 Msg_205: 24 Node2
 SG_ Sig_205_0 : 7|12@0+ (0.1,-0.5) [-0.5|409] "%" Node3,Node4
 SG_ Sig_205_1 : 11|8@0+ (0.1,0) [0|25.5] "A" Node3,Node4
 SG_ Sig_205_2 : 19|8@0+ (1,-40) [-40|215] "V" Node3,Node4
 SG_ Sig_205_3 : 27|2@0- (0.01,-0.5) [-0.52|-0.49] "" Node3,Node4
 SG_ Sig_205_4 : 25|1@0+ (1,0) [0|1] "" Node3,Node4
 SG_ Sig_205_5 : 24|1@0+ (1,0) [0|1] "" Node3,Node4

BO_ 207 Msg_206: 16 Node3
 SG_ Sig_206_sel M : 0|8@1+ (0.25,0) [0|63.75] "rpm" Node4,Node5
 SG_ Sig_206_a0 m0 : 8|8@1+ (0.1,0) [0|25.5] "rpm" Node4,Node5
 SG_ Sig_206_a1 m0 : 16|1@1+ (1,0) [0|1] "" Node4,Node5
 SG_ Sig_206_b0 m1 : 8|2@1- (0.25,-40) [-40.5|-39.75] "" Node4,Node5
 SG_ Sig_206_b1 m1 : 10|3@1+ (0.5,-0.5) [-0.5|3] "rpm" Node4,Node5
 SG_ Sig_206_c0 : 40|8@1+ (0.25,0) [0|63.75] "%" Node4,Node5
 SG_ Sig_206_c1 : 48|2@1+ (0.5,0) [0|1.5] "" Node4,Node5

BO_ 208 Msg_207: 8 Node4
 SG_ Sig_207_0 : 0|4@1+ (0.1,0) [0|1.5] "km/h" Node5
 SG_ Sig_207_1 : 4|2@1+ (0.5,0) [0|1.5] "" Node5
 SG_ Sig_207_2 : 6|2@1- (2,100) [96|102] "" Node5
 SG_ Sig_207_3 : 8|16@1- (1,0) [-32768|32767] "degC" Node5
 SG_ Sig_207_4 : 24|1@1+ (1,0) [0|1] "" Node5
 SG_ Sig_207_5 : 25|8@1+ (1,0) [0|255] "%" Node5

BO_ 209 Msg_208: 64 Node5
 SG_ Sig_208_sel M : 0|8@1- (0.5,0) [-64|63.5] "A" Node6,Node7
 SG_ Sig_208_a0 m0 : 8|8@1- (1,0) [-128|127] "%" Node6,Node7
 SG_ Sig_208_a1 m0 : 16|8@1+ (0.1,0) [0|25.5] "degC" Node6,Node7
 SG_ Sig_208_b0 m1 : 8|4@1+ (0.1,0) [0|1.5] "%" Node6,Node7
 SG_ Sig_208_b1 m1 : 12|3@1+ (1,0) [0|7] "%" Node6,Node7
 SG_ Sig_208_c0 : 40|2@1+ (1,-0.5) [-0.5|2.5] "" Node6,Node7
 SG_ Sig_208_c1 : 42|16@1+ (0.01,0) [0|655.35] "%" Node6,Node7

BO_ 210 Msg_209: 8 Node6
 SG_ Sig_209_0 : 7|3@0+ (1,0) [0|7] "V" Node7
 SG_ Sig_209_1 : 4|4@0- (0.01,-40) [-40.08|-39.93] "degC" Node7
 SG_ Sig_209_2 : 0|8@0+ (0.5,100) [100|227.5] "" Node7
 SG_ Sig_209_3 : 8|4@0+ (0.1,-40) [-40|-38.5] "A" Node7
 SG_ Sig_209_4 : 20|3@0+ (0.01,100) [100|100.07] "" Node7
 SG_ Sig_209_5 : 17|16@0+ (1,0) [0|65535] "rpm" Node7

BO_ 211 Msg_210: 8 Node7
 SG_ Sig_210_0 : 7|12@0+ (1,0) [0|4095] "" Node8
 SG_ Sig_210_1 : 11|12@0+ (2,-40) [-40|8150] "A" Node8
 SG_ Sig_210_2 : 31|8@0- (0.1,-40) [-52.8|-27.3] "rpm" Node8
 SG_ Sig_210_3 : 39|12@0+ (1,-40) [-40|4055] "rpm" Node8
 SG_ Sig_210_4 : 43|12@0- (1,0) [-2048|2047] "degC" Node8
 SG_ Sig_210_5 : 63|4@0+ (0.01,0) [0|0.15] "" Node8

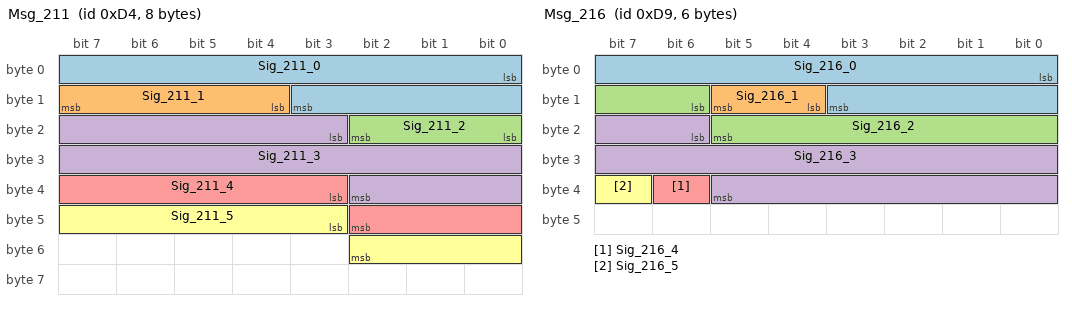
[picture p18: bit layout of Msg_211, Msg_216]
BO_ 212 Msg_211: 8 Node8
 SG_ Sig_211_0 : 0|12@1- (1,0) [-2048|2047] "" Node9
 SG_ Sig_211_1 : 12|4@1+ (0.01,0) [0|0.15] "km/h" Node9
 SG_ Sig_211_2 : 16|3@1+ (1,-0.5) [-0.5|6.5] "" Node9
 SG_ Sig_211_3 : 19|16@1+ (0.25,0) [0|16383.75] "%" Node9
 SG_ Sig_211_4 : 35|8@1+ (1,0) [0|255] "km/h" Node9
 SG_ Sig_211_5 : 43|8@1- (0.1,0) [-12.8|12.7] "" Node9

BO_ 213 Msg_212: 12 Node9
 SG_ Sig_212_0 : 7|1@0+ (1,0) [0|1] "" Node10,Node11
 SG_ Sig_212_1 : 6|8@0+ (0.5,0) [0|127.5] "degC" Node10,Node11
 SG_ Sig_212_2 : 14|3@0+ (2,-40) [-40|-26] "A" Node10,Node11
 SG_ Sig_212_3 : 11|1@0+ (1,0) [0|1] "" Node10,Node11
 SG_ Sig_212_4 : 10|8@0- (2,-40) [-296|214] "" Node10,Node11
 SG_ Sig_212_5 : 18|3@0+ (2,-0.5) [-0.5|13.5] "%" Node10,Node11

BO_ 214 Msg_213: 8 Node10
 SG_ Sig_213_sel M : 0|8@1- (2,-40) [-296|214] "%" Node11,Node12
 SG_ Sig_213_a0 m0 : 8|8@1+ (1,-40) [-40|215] "A" Node11,Node12
 SG_ Sig_213_a1 m0 : 16|1@1+ (1,0) [0|1] "" Node11,Node12
 SG_ Sig_213_b0 m1 : 8|8@1+ (2,0) [0|510] "A" Node11,Node12
 SG_ Sig_213_b1 m1 : 16|1@1+ (1,0) [0|1] "" Node11,Node12
 SG_ Sig_213_c0 : 40|12@1- (2,100) [-3996|4194] "degC" Node11,Node12
 SG_ Sig_213_c1 : 52|12@1+ (0.5,0) [0|2047.5] "rpm" Node11,Node12

BO_ 2147549398 Msg_214: 16 Node11
 SG_ Sig_214_sel M : 0|8@1+ (0.25,100) [100|163.75] "A" Node12,Node1
 SG_ Sig_214_a0 m0 : 8|8@1+ (0.1,100) [100|125.5] "%" Node12,Node1
 SG_ Sig_214_a1 m0 : 16|1@1+ (1,0) [0|1] "" Node12,Node1
 SG_ Sig_214_b0 m1 : 8|1@1+ (1,0) [0|1] "" Node12,Node1
 SG_ Sig_214_b1 m1 : 9|4@1+ (1,0) [0|15] "km/h" Node12,Node1
 SG_ Sig_214_c0 : 40|8@1+ (0.1,-0.5) [-0.5|25] "degC" Node12,Node1
 SG_ Sig_214_c1 : 48|3@1- (0.01,-40) [-40.04|-39.97] "rpm" Node12,Node1

BO_ 216 Msg_215: 2 Node12
 SG_ Sig_215_0 : 0|3@1+ (0.01,0) [0|0.07] "km/h" Node1
 SG_ Sig_215_1 : 3|1@1+ (1,0) [0|1] "" Node1
 SG_ Sig_215_2 : 4|12@1- (0.01,0) [-20.48|20.47] "rpm" Node1

BO_ 217 Msg_216: 6 Node1
 SG_ Sig_216_0 : 0|12@1+ (0.01,-40) [-40|0.95] "rpm" Node2,Node3
 SG_ Sig_216_1 : 12|2@1+ (2,0) [0|6] "" Node2,Node3
 SG_ Sig_216_2 : 14|8@1- (0.25,-0.5) [-32.5|31.25] "km/h" Node2,Node3
 SG_ Sig_216_3 : 22|16@1- (1,0) [-32768|32767] "degC" Node2,Node3
 SG_ Sig_216_4 : 38|1@1+ (1,0) [0|1] "" Node2,Node3
 SG_ Sig_216_5 : 39|1@1+ (1,0) [0|1] "" Node2,Node3

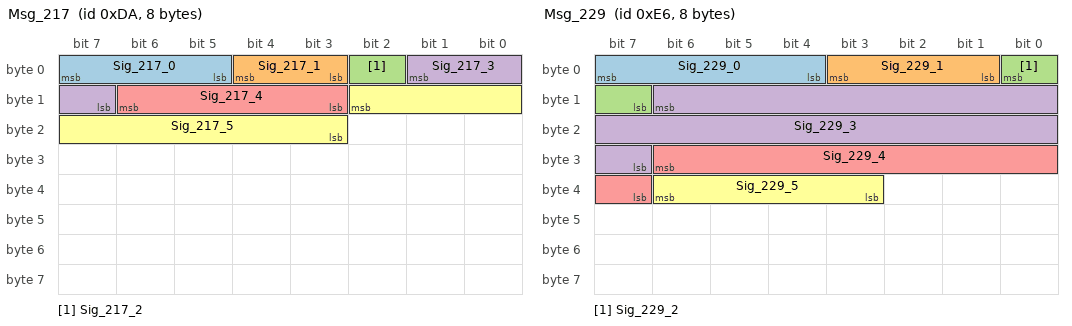
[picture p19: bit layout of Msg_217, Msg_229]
BO_ 218 Msg_217: 8 Node2
 SG_ Sig_217_0 : 7|3@0+ (0.25,-40) [-40|-38.25] "degC" Node3,Node4
 SG_ Sig_217_1 : 4|2@0- (2,-0.5) [-4.5|1.5] "" Node3,Node4
 SG_ Sig_217_2 : 2|1@0+ (1,0) [0|1] "" Node3,Node4
 SG_ Sig_217_3 : 1|3@0+ (0.5,0) [0|3.5] "%" Node3,Node4
 SG_ Sig_217_4 : 14|4@0+ (2,-40) [-40|-10] "%" Node3,Node4
 SG_ Sig_217_5 : 10|8@0- (0.5,0) [-64|63.5] "km/h" Node3,Node4

BO_ 219 Msg_218: 64 Node3
 SG_ Sig_218_0 : 0|8@1+ (2,0) [0|510] "km/h" Node4,Node5
 SG_ Sig_218_1 : 8|8@1- (0.01,-40) [-41.28|-38.73] "km/h" Node4,Node5
 SG_ Sig_218_2 : 16|3@1- (0.01,-0.5) [-0.54|-0.47] "degC" Node4,Node5
 SG_ Sig_218_3 : 19|1@1+ (1,0) [0|1] "" Node4,Node5
 SG_ Sig_218_4 : 20|16@1- (0.5,100) [-16284|16483.5] "" Node4,Node5
 SG_ Sig_218_5 : 36|8@1- (0.25,100) [68|131.75] "" Node4,Node5

BO_ 220 Msg_219: 4 Node4
 SG_ Sig_219_0 : 0|16@1+ (1,0) [0|65535] "V" Node5,Node6
 SG_ Sig_219_1 : 16|8@1+ (0.01,0) [0|2.55] "degC" Node5,Node6
 SG_ Sig_219_2 : 24|8@1+ (0.25,0) [0|63.75] "%" Node5,Node6

BO_ 221 Msg_220: 8 Node5
 SG_ Sig_220_0 : 0|4@1+ (1,-40) [-40|-25] "V" Node6,Node7
 SG_ Sig_220_1 : 4|12@1+ (0.01,0) [0|40.95] "rpm" Node6,Node7
 SG_ Sig_220_2 : 16|8@1+ (0.01,-0.5) [-0.5|2.05] "" Node6,Node7
 SG_ Sig_220_3 : 24|3@1+ (2,-0.5) [-0.5|13.5] "A" Node6,Node7
 SG_ Sig_220_4 : 27|12@1+ (0.5,-0.5) [-0.5|2047] "V" Node6,Node7
 SG_ Sig_220_5 : 39|8@1+ (0.25,0) [0|63.75] "" Node6,Node7

BO_ 222 Msg_221: 8 Node6
 SG_ Sig_221_sel M : 0|8@1+ (1,0) [0|255] "degC" Node7
 SG_ Sig_221_a0 m0 : 8|8@1+ (2,0) [0|510] "" Node7
 SG_ Sig_221_a1 m0 : 16|8@1+ (0.01,0) [0|2.55] "degC" Node7
 SG_ Sig_221_b0 m1 : 8|3@1+ (0.25,-40) [-40|-38.25] "%" Node7
 SG_ Sig_221_b1 m1 : 11|2@1+ (0.5,-0.5) [-0.5|1] "" Node7
 SG_ Sig_221_c0 : 40|8@1+ (0.1,-0.5) [-0.5|25] "km/h" Node7
 SG_ Sig_221_c1 : 48|1@1+ (1,0) [0|1] "" Node7

BO_ 2147549406 Msg_222: 16 Node7
 SG_ Sig_222_0 : 0|12@1- (0.5,-0.5) [-1024.5|1023] "%" Node8,Node9
 SG_ Sig_222_1 : 12|1@1+ (1,0) [0|1] "" Node8,Node9
 SG_ Sig_222_2 : 13|8@1+ (1,0) [0|255] "rpm" Node8,Node9
 SG_ Sig_222_3 : 21|12@1+ (1,0) [0|4095] "" Node8,Node9
 SG_ Sig_222_4 : 33|4@1+ (2,-0.5) [-0.5|29.5] "rpm" Node8,Node9
 SG_ Sig_222_5 : 37|3@1- (2,0) [-8|6] "A" Node8,Node9

BO_ 224 Msg_223: 16 Node8
 SG_ Sig_223_0 : 0|2@1- (1,0) [-2|1] "" Node9,Node10
 SG_ Sig_223_1 : 2|12@1+ (0.01,0) [0|40.95] "" Node9,Node10
 SG_ Sig_223_2 : 14|3@1- (2,0) [-8|6] "km/h" Node9,Node10
 SG_ Sig_223_3 : 17|8@1- (0.1,100) [87.2|112.7] "" Node9,Node10
 SG_ Sig_223_4 : 25|8@1+ (1,0) [0|255] "degC" Node9,Node10
 SG_ Sig_223_5 : 33|16@1- (1,-0.5) [-32768.5|32766.5] "degC" Node9,Node10

BO_ 225 Msg_224: 64 Node9
 SG_ Sig_224_0 : 0|12@1+ (0.1,0) [0|409.5] "%" Node10
 SG_ Sig_224_1 : 12|8@1+ (0.01,0) [0|2.55] "rpm" Node10
 SG_ Sig_224_2 : 20|4@1+ (1,0) [0|15] "V" Node10
 SG_ Sig_224_3 : 24|3@1- (1,0) [-4|3] "degC" Node10
 SG_ Sig_224_4 : 27|3@1+ (1,100) [100|107] "km/h" Node10
 SG_ Sig_224_5 : 30|4@1+ (0.01,-0.5) [-0.5|-0.35] "%" Node10

BO_ 226 Msg_225: 24 Node10
 SG_ Sig_225_0 : 7|1@0+ (1,0) [0|1] "" Node11,Node12
 SG_ Sig_225_1 : 6|8@0+ (0.1,0) [0|25.5] "V" Node11,Node12
 SG_ Sig_225_2 : 14|3@0+ (0.1,-0.5) [-0.5|0.2] "V" Node11,Node12
 SG_ Sig_225_3 : 11|8@0+ (0.25,-0.5) [-0.5|63.25] "rpm" Node11,Node12
 SG_ Sig_225_4 : 19|8@0+ (2,0) [0|510] "A" Node11,Node12
 SG_ Sig_225_5 : 27|2@0- (0.5,100) [99|100.5] "" Node11,Node12

BO_ 2147549410 Msg_226: 12 Node11
 SG_ Sig_226_sel M : 0|8@1- (1,0) [-128|127] "A" Node12
 SG_ Sig_226_a0 m0 : 8|4@1+ (0.5,100) [100|107.5] "" Node12
 SG_ Sig_226_a1 m0 : 12|3@1+ (0.5,0) [0|3.5] "%" Node12
 SG_ Sig_226_b0 m1 : 8|2@1+ (0.25,100) [100|100.75] "" Node12
 SG_ Sig_226_b1 m1 : 10|3@1+ (0.5,-40) [-40|-36.5] "km/h" Node12
 SG_ Sig_226_c0 : 40|2@1- (1,0) [-2|1] "" Node12
 SG_ Sig_226_c1 : 42|12@1- (2,100) [-3996|4194] "%" Node12

BO_ 228 Msg_227: 24 Node12
 SG_ Sig_227_0 : 7|1@0+ (1,0) [0|1] "" Node1,Node2
 SG_ Sig_227_1 : 6|8@0+ (0.5,-40) [-40|87.5] "degC" Node1,Node2
 SG_ Sig_227_2 : 14|12@0+ (2,0) [0|8190] "A" Node1,Node2
 SG_ Sig_227_3 : 18|16@0+ (0.01,0) [0|655.35] "%" Node1,Node2
 SG_ Sig_227_4 : 34|8@0+ (0.1,100) [100|125.5] "A" Node1,Node2
 SG_ Sig_227_5 : 42|8@0- (0.5,0) [-64|63.5] "V" Node1,Node2

BO_ 229 Msg_228: 8 Node1
 SG_ Sig_228_0 : 0|4@1+ (1,-40) [-40|-25] "V" Node2
 SG_ Sig_228_1 : 4|16@1+ (0.25,100) [100|16483.75] "rpm" Node2
 SG_ Sig_228_2 : 20|4@1- (1,100) [92|107] "%" Node2
 SG_ Sig_228_3 : 24|16@1+ (2,-40) [-40|131030] "km/h" Node2
 SG_ Sig_228_4 : 40|3@1+ (0.5,0) [0|3.5] "%" Node2
 SG_ Sig_228_5 : 43|8@1+ (1,0) [0|255] "rpm" Node2

BO_ 230 Msg_229: 8 Node2
 SG_ Sig_229_0 : 7|4@0- (0.5,-40) [-44|-36.5] "A" Node3,Node4
 SG_ Sig_229_1 : 3|3@0+ (2,-40) [-40|-26] "%" Node3,Node4
 SG_ Sig_229_2 : 0|2@0+ (0.5,100) [100|101.5] "" Node3,Node4
 SG_ Sig_229_3 : 14|16@0+ (0.5,100) [100|32867.5] "" Node3,Node4
 SG_ Sig_229_4 : 30|8@0+ (0.5,100) [100|227.5] "%" Node3,Node4
 SG_ Sig_229_5 : 38|4@0+ (0.25,-40) [-40|-36.25] "V" Node3,Node4

BO_ 231 Msg_230: 8 Node3
 SG_ Sig_230_0 : 7|16@0+ (0.1,0) [0|6553.5] "A" Node4
 SG_ Sig_230_1 : 23|8@0- (1,0) [-128|127] "V" Node4
 SG_ Sig_230_2 : 31|2@0+ (1,0) [0|3] "" Node4
 SG_ Sig_230_3 : 29|12@0- (0.1,100) [-104.8|304.7] "km/h" Node4
 SG_ Sig_230_4 : 33|12@0- (0.1,0) [-204.8|204.7] "V" Node4
 SG_ Sig_230_5 : 53|8@0- (0.01,100) [98.72|101.27] "V" Node4

BO_ 232 Msg_231: 12 Node4
 SG_ Sig_231_0 : 7|8@0+ (0.25,-40) [-40|23.75] "degC" Node5,Node6
 SG_ Sig_231_1 : 15|8@0+ (2,100) [100|610] "V" Node5,Node6
 SG_ Sig_231_2 : 23|2@0+ (0.01,0) [0|0.03] "" Node5,Node6
 SG_ Sig_231_3 : 21|2@0+ (2,0) [0|6] "" Node5,Node6
 SG_ Sig_231_4 : 19|3@0+ (0.5,-40) [-40|-36.5] "%" Node5,Node6
 SG_ Sig_231_5 : 16|1@0+ (1,0) [0|1] "" Node5,Node6

BO_ 233 Msg_232: 12 Node5
 SG_ Sig_232_0 : 7|4@0+ (0.1,0) [0|1.5] "A" Node6,Node7
 SG_ Sig_232_1 : 3|4@0- (1,100) [92|107] "degC" Node6,Node7
 SG_ Sig_232_2 : 15|8@0+ (1,100) [100|355] "km/h" Node6,Node7
 SG_ Sig_232_3 : 23|8@0+ (0.5,-40) [-40|87.5] "A" Node6,Node7
 SG_ Sig_232_4 : 31|8@0+ (0.5,100) [100|227.5] "rpm" Node6,Node7
 SG_ Sig_232_5 : 39|8@0- (0.1,-40) [-52.8|-27.3] "degC" Node6,Node7

BO_ 234 Msg_233: 24 Node6
 SG_ Sig_233_0 : 7|2@0+ (1,100) [100|103] "" Node7
 SG_ Sig_233_1 : 5|4@0+ (1,-40) [-40|-25] "A" Node7
 SG_ Sig_233_2 : 1|3@0- (0.5,-40) [-42|-38.5] "rpm" Node7
 SG_ Sig_233_3 : 14|4@0- (1,0) [-8|7] "A" Node7
 SG_ Sig_233_4 : 10|2@0- (1,-40) [-42|-39] "" Node7
 SG_ Sig_233_5 : 8|8@0+ (0.1,0) [0|25.5] "" Node7

BO_ 235 Msg_234: 12 Node7
 SG_ Sig_234_0 : 7|8@0+ (1,100) [100|355] "degC" Node8,Node9
 SG_ Sig_234_1 : 15|2@0- (0.25,-40) [-40.5|-39.75] "" Node8,Node9
 SG_ Sig_234_2 : 13|8@0- (0.1,-0.5) [-13.3|12.2] "" Node8,Node9
 SG_ Sig_234_3 : 21|1@0+ (1,0) [0|1] "" Node8,Node9
 SG_ Sig_234_4 : 20|16@0+ (1,0) [0|65535] "V" Node8,Node9
 SG_ Sig_234_5 : 36|8@0- (1,0) [-128|127] "rpm" Node8,Node9

BO_ 236 Msg_235: 12 Node8
 SG_ Sig_235_0 : 0|8@1+ (0.01,0) [0|2.55] "V" Node9
 SG_ Sig_235_1 : 8|12@1+ (0.25,-0.5) [-0.5|1023.25] "A" Node9
 SG_ Sig_235_2 : 20|2@1+ (1,-40) [-40|-37] "" Node9
 SG_ Sig_235_3 : 22|4@1+ (0.1,0) [0|1.5] "km/h" Node9
 SG_ Sig_235_4 : 26|12@1+ (0.1,0) [0|409.5] "A" Node9
 SG_ Sig_235_5 : 38|8@1+ (0.1,0) [0|25.5] "degC" Node9

BO_ 2147549420 Msg_236: 6 Node9
 SG_ Sig_236_0 : 7|1@0+ (1,0) [0|1] "" Node10,Node11
 SG_ Sig_236_1 : 6|16@0+ (1,0) [0|65535] "" Node10,Node11
 SG_ Sig_236_2 : 22|8@0+ (0.1,0) [0|25.5] "V" Node10,Node11
 SG_ Sig_236_3 : 30|8@0+ (0.25,0) [0|63.75] "%" Node10,Node11
 SG_ Sig_236_4 : 38|1@0+ (1,0) [0|1] "" Node10,Node11
 SG_ Sig_236_5 : 37|12@0+ (2,0) [0|8190] "rpm" Node10,Node11

BO_ 238 Msg_237: 6 Node10
 SG_ Sig_237_0 : 7|4@0+ (0.01,0) [0|0.15] "" Node11,Node12
 SG_ Sig_237_1 : 3|8@0+ (1,-0.5) [-0.5|254.5] "degC" Node11,Node12
 SG_ Sig_237_2 : 11|2@0- (1,-0.5) [-2.5|0.5] "" Node11,Node12
 SG_ Sig_237_3 : 9|8@0+ (0.01,0) [0|2.55] "%" Node11,Node12
 SG_ Sig_237_4 : 17|12@0+ (0.1,0) [0|409.5] "V" Node11,Node12
 SG_ Sig_237_5 : 37|14@0+ (1,-0.5) [-0.5|16382.5] "degC" Node11,Node12

BO_ 2147549422 Msg_238: 2 Node11
 SG_ Sig_238_0 : 7|16@0+ (0.01,100) [100|755.35] "%" Node12,Node1

BO_ 240 Msg_239: 16 Node12
 SG_ Sig_239_0 : 0|3@1- (0.5,0) [-2|1.5] "" Node1,Node2
 SG_ Sig_239_1 : 3|12@1- (0.01,0) [-20.48|20.47] "V" Node1,Node2
 SG_ Sig_239_2 : 15|8@1+ (1,-40) [-40|215] "V" Node1,Node2
 SG_ Sig_239_3 : 23|2@1- (1,0) [-2|1] "" Node1,Node2
 SG_ Sig_239_4 : 25|16@1- (2,100) [-65436|65634] "V" Node1,Node2
 SG_ Sig_239_5 : 41|8@1- (0.1,-0.5) [-13.3|12.2] "km/h" Node1,Node2

BO_ 241 Msg_240: 64 Node1
 SG_ Sig_240_0 : 0|2@1- (0.01,100) [99.98|100.01] "" Node2,Node3
 SG_ Sig_240_1 : 2|3@1+ (0.01,-40) [-40|-39.93] "rpm" Node2,Node3
 SG_ Sig_240_2 : 5|12@1+ (2,-40) [-40|8150] "" Node2,Node3
 SG_ Sig_240_3 : 17|12@1+ (1,100) [100|4195] "degC" Node2,Node3
 SG_ Sig_240_4 : 29|12@1- (0.1,0) [-204.8|204.7] "%" Node2,Node3
 SG_ Sig_240_5 : 41|3@1+ (1,-0.5) [-0.5|6.5] "A" Node2,Node3

BO_ 242 Msg_241: 16 Node2
 SG_ Sig_241_0 : 0|16@1+ (1,0) [0|65535] "%" Node3,Node4
 SG_ Sig_241_1 : 16|1@1+ (1,0) [0|1] "" Node3,Node4
 SG_ Sig_241_2 : 17|2@1+ (0.5,0) [0|1.5] "" Node3,Node4
 SG_ Sig_241_3 : 19|12@1+ (1,0) [0|4095] "A" Node3,Node4
 SG_ Sig_241_4 : 31|8@1+ (0.25,-0.5) [-0.5|63.25] "km/h" Node3,Node4
 SG_ Sig_241_5 : 39|12@1+ (2,0) [0|8190] "" Node3,Node4

BO_ 243 Msg_242: 12 Node3
 SG_ Sig_242_0 : 7|2@0+ (0.5,-40) [-40|-38.5] "" Node4
 SG_ Sig_242_1 : 5|2@0- (1,0) [-2|1] "" Node4
 SG_ Sig_242_2 : 3|16@0+ (0.1,0) [0|6553.5] "" Node4
 SG_ Sig_242_3 : 19|3@0+ (0.25,0) [0|1.75] "rpm" Node4
 SG_ Sig_242_4 : 16|8@0+ (0.25,-0.5) [-0.5|63.25] "degC" Node4
 SG_ Sig_242_5 : 24|16@0- (0.25,0) [-8192|8191.75] "A" Node4

BO_ 244 Msg_243: 32 Node4
 SG_ Sig_243_0 : 0|3@1+ (1,0) [0|7] "V" Node5,Node6
 SG_ Sig_243_1 : 3|8@1+ (0.01,-40) [-40|-37.45] "" Node5,Node6
 SG_ Sig_243_2 : 11|3@1+ (1,0) [0|7] "rpm" Node5,Node6
 SG_ Sig_243_3 : 14|2@1- (1,0) [-2|1] "" Node5,Node6
 SG_ Sig_243_4 : 16|4@1+ (0.1,0) [0|1.5] "degC" Node5,Node6
 SG_ Sig_243_5 : 20|8@1+ (0.25,0) [0|63.75] "%" Node5,Node6

BO_ 245 Msg_244: 8 Node5
 SG_ Sig_244_0 : 7|4@0+ (0.01,0) [0|0.15] "%" Node6
 SG_ Sig_244_1 : 3|8@0+ (1,-40) [-40|215] "" Node6
 SG_ Sig_244_2 : 11|8@0+ (0.5,0) [0|127.5] "" Node6
 SG_ Sig_244_3 : 19|4@0- (0.25,0) [-2|1.75] "rpm" Node6
 SG_ Sig_244_4 : 31|8@0+ (0.01,0) [0|2.55] "" Node6
 SG_ Sig_244_5 : 39|16@0+ (2,0) [0|131070] "A" Node6

BO_ 246 Msg_245: 16 Node6
 SG_ Sig_245_0 : 0|16@1- (0.1,0) [-3276.8|3276.7] "degC" Node7,Node8
 SG_ Sig_245_1 : 16|2@1+ (0.01,100) [100|100.03] "" Node7,Node8
 SG_ Sig_245_2 : 18|2@1- (0.5,-40) [-41|-39.5] "" Node7,Node8
 SG_ Sig_245_3 : 20|2@1+ (1,-40) [-40|-37] "" Node7,Node8
 SG_ Sig_245_4 : 22|8@1+ (1,0) [0|255] "degC" Node7,Node8
 SG_ Sig_245_5 : 30|12@1- (0.01,-40) [-60.48|-19.53] "V" Node7,Node8

BO_ 247 Msg_246: 64 Node7
 SG_ Sig_246_0 : 7|4@0+ (0.1,0) [0|1.5] "rpm" Node8
 SG_ Sig_246_1 : 3|2@0+ (0.5,0) [0|1.5] "" Node8
 SG_ Sig_246_2 : 1|4@0+ (2,0) [0|30] "A" Node8
 SG_ Sig_246_3 : 13|3@0- (0.01,100) [99.96|100.03] "km/h" Node8
 SG_ Sig_246_4 : 10|3@0+ (0.1,0) [0|0.7] "%" Node8
 SG_ Sig_246_5 : 23|3@0- (0.5,-40) [-42|-38.5] "rpm" Node8

BO_ 2147549431 Msg_247: 12 Node8
 SG_ Sig_247_0 : 7|12@0+ (0.5,-0.5) [-0.5|2047] "V" Node9
 SG_ Sig_247_1 : 11|16@0- (1,0) [-32768|32767] "%" Node9
 SG_ Sig_247_2 : 27|4@0+ (0.5,0) [0|7.5] "degC" Node9
 SG_ Sig_247_3 : 39|3@0+ (2,100) [100|114] "V" Node9
 SG_ Sig_247_4 : 36|2@0+ (2,0) [0|6] "" Node9
 SG_ Sig_247_5 : 34|8@0+ (0.01,0) [0|2.55] "%" Node9

BO_ 249 Msg_248: 24 Node9
 SG_ Sig_248_0 : 0|8@1+ (1,0) [0|255] "degC" Node10,Node11
 SG_ Sig_248_1 : 8|16@1+ (1,-0.5) [-0.5|65534.5] "degC" Node10,Node11
 SG_ Sig_248_2 : 24|12@1+ (1,100) [100|4195] "km/h" Node10,Node11
 SG_ Sig_248_3 : 36|1@1+ (1,0) [0|1] "" Node10,Node11
 SG_ Sig_248_4 : 37|4@1+ (2,100) [100|130] "" Node10,Node11
 SG_ Sig_248_5 : 41|8@1- (1,100) [-28|227] "V" Node10,Node11

BO_ 250 Msg_249: 64 Node10
 SG_ Sig_249_0 : 0|12@1+ (1,-40) [-40|4055] "V" Node11
 SG_ Sig_249_1 : 12|2@1- (0.5,0) [-1|0.5] "" Node11
 SG_ Sig_249_2 : 14|4@1- (0.1,0) [-0.8|0.7] "" Node11
 SG_ Sig_249_3 : 18|8@1+ (0.25,-40) [-40|23.75] "km/h" Node11
 SG_ Sig_249_4 : 26|16@1+ (0.25,-40) [-40|16343.75] "A" Node11
 SG_ Sig_249_5 : 42|12@1+ (1,-0.5) [-0.5|4094.5] "%" Node11

BO_ 251 Msg_250: 8 Node11
 SG_ Sig_250_0 : 0|8@1+ (0.5,0) [0|127.5] "A" Node12
 SG_ Sig_250_1 : 8|4@1+ (1,0) [0|15] "%" Node12
 SG_ Sig_250_2 : 12|2@1+ (0.25,-40) [-40|-39.25] "" Node12
 SG_ Sig_250_3 : 14|8@1+ (0.01,100) [100|102.55] "V" Node12
 SG_ Sig_250_4 : 22|1@1+ (1,0) [0|1] "" Node12
 SG_ Sig_250_5 : 23|1@1+ (1,0) [0|1] "" Node12

BO_ 252 Msg_251: 32 Node12
 SG_ Sig_251_sel M : 0|8@1+ (0.5,-0.5) [-0.5|127] "degC" Node1
 SG_ Sig_251_a0 m0 : 8|16@1+ (2,-40) [-40|131030] "degC" Node1
 SG_ Sig_251_a1 m0 : 24|1@1+ (1,0) [0|1] "" Node1
 SG_ Sig_251_b0 m1 : 8|2@1+ (0.1,-0.5) [-0.5|-0.2] "" Node1
 SG_ Sig_251_b1 m1 : 10|12@1+ (2,0) [0|8190] "V" Node1
 SG_ Sig_251_c0 : 40|2@1+ (1,100) [100|103] "" Node1
 SG_ Sig_251_c1 : 42|16@1+ (0.01,-40) [-40|615.35] "%" Node1

BO_ 2147549436 Msg_252: 24 Node1
 SG_ Sig_252_0 : 7|8@0- (0.25,0) [-32|31.75] "V" Node2
 SG_ Sig_252_1 : 15|1@0+ (1,0) [0|1] "" Node2
 SG_ Sig_252_2 : 14|8@0+ (2,0) [0|510] "rpm" Node2
 SG_ Sig_252_3 : 22|3@0+ (0.5,-40) [-40|-36.5] "rpm" Node2
 SG_ Sig_252_4 : 19|8@0+ (0.5,-40) [-40|87.5] "A" Node2
 SG_ Sig_252_5 : 27|16@0+ (0.25,0) [0|16383.75] "A" Node2

BO_ 2147549437 Msg_253: 8 Node2
 SG_ Sig_253_0 : 7|2@0- (0.5,0) [-1|0.5] "" Node3
 SG_ Sig_253_1 : 5|1@0+ (1,0) [0|1] "" Node3
 SG_ Sig_253_2 : 4|8@0+ (0.5,0) [0|127.5] "V" Node3
 SG_ Sig_253_3 : 12|12@0+ (0.01,0) [0|40.95] "A" Node3
 SG_ Sig_253_4 : 16|12@0+ (1,0) [0|4095] "" Node3
 SG_ Sig_253_5 : 36|1@0+ (1,0) [0|1] "" Node3

BO_ 2147549438 Msg_254: 8 Node3
 SG_ Sig_254_0 : 7|2@0+ (1,100) [100|103] "" Node4,Node5
 SG_ Sig_254_1 : 5|8@0- (1,0) [-128|127] "V" Node4,Node5
 SG_ Sig_254_2 : 13|3@0+ (0.25,0) [0|1.75] "rpm" Node4,Node5
 SG_ Sig_254_3 : 10|8@0+ (0.01,-0.5) [-0.5|2.05] "A" Node4,Node5
 SG_ Sig_254_4 : 18|4@0+ (2,-40) [-40|-10] "rpm" Node4,Node5
 SG_ Sig_254_5 : 30|12@0- (0.1,0) [-204.8|204.7] "rpm" Node4,Node5

BO_ 256 Msg_255: 8 Node4
 SG_ Sig_255_0 : 0|16@1+ (0.01,-0.5) [-0.5|654.85] "degC" Node5
 SG_ Sig_255_1 : 16|1@1+ (1,0) [0|1] "" Node5
 SG_ Sig_255_2 : 17|4@1+ (0.25,0) [0|3.75] "%" Node5
 SG_ Sig_255_3 : 21|2@1+ (0.5,0) [0|1.5] "" Node5
 SG_ Sig_255_4 : 23|8@1+ (0.01,0) [0|2.55] "km/h" Node5
 SG_ Sig_255_5 : 31|12@1+ (1,0) [0|4095] "km/h" Node5

BO_ 257 Msg_256: 32 Node5
 SG_ Sig_256_0 : 0|8@1- (2,-40) [-296|214] "V" Node6
 SG_ Sig_256_1 : 8|16@1+ (1,-0.5) [-0.5|65534.5] "" Node6
 SG_ Sig_256_2 : 24|12@1- (0.25,0) [-512|511.75] "" Node6
 SG_ Sig_256_3 : 36|4@1+ (0.1,100) [100|101.5] "km/h" Node6
 SG_ Sig_256_4 : 40|3@1+ (0.25,0) [0|1.75] "%" Node6
 SG_ Sig_256_5 : 43|2@1- (1,0) [-2|1] "" Node6

BO_ 258 Msg_257: 6 Node6
 SG_ Sig_257_0 : 0|4@1+ (2,0) [0|30] "A" Node7,Node8
 SG_ Sig_257_1 : 4|8@1+ (0.1,0) [0|25.5] "A" Node7,Node8
 SG_ Sig_257_2 : 12|2@1- (0.25,-40) [-40.5|-39.75] "" Node7,Node8
 SG_ Sig_257_3 : 14|8@1+ (1,0) [0|255] "km/h" Node7,Node8
 SG_ Sig_257_4 : 22|3@1+ (0.01,0) [0|0.07] "" Node7,Node8
 SG_ Sig_257_5 : 25|1@1+ (1,0) [0|1] "" Node7,Node8

BO_ 2147549442 Msg_258: 12 Node7
 SG_ Sig_258_0 : 0|3@1+ (0.25,-0.5) [-0.5|1.25] "degC" Node8
 SG_ Sig_258_1 : 3|3@1+ (0.25,0) [0|1.75] "V" Node8
 SG_ Sig_258_2 : 6|12@1- (0.25,0) [-512|511.75] "A" Node8
 SG_ Sig_258_3 : 18|4@1+ (2,-0.5) [-0.5|29.5] "V" Node8
 SG_ Sig_258_4 : 22|12@1- (0.1,-40) [-244.8|164.7] "A" Node8
 SG_ Sig_258_5 : 34|4@1+ (0.01,100) [100|100.15] "degC" Node8

BO_ 260 Msg_259: 6 Node8
 SG_ Sig_259_0 : 7|3@0- (0.01,-40) [-40.04|-39.97] "rpm" Node9
 SG_ Sig_259_1 : 4|12@0+ (0.5,-0.5) [-0.5|2047] "%" Node9
 SG_ Sig_259_2 : 8|16@0+ (1,100) [100|65635] "A" Node9
 SG_ Sig_259_3 : 24|12@0+ (0.01,-40) [-40|0.95] "" Node9
 SG_ Sig_259_4 : 44|3@0+ (1,100) [100|107] "rpm" Node9
 SG_ Sig_259_5 : 41|2@0+ (0.25,-0.5) [-0.5|0.25] "" Node9

BO_ 2147549444 Msg_260: 12 Node9
 SG_ Sig_260_0 : 0|3@1+ (0.1,-40) [-40|-39.3] "V" Node10
 SG_ Sig_260_1 : 3|4@1- (1,100) [92|107] "" Node10
 SG_ Sig_260_2 : 7|4@1- (0.01,-40) [-40.08|-39.93] "" Node10
 SG_ Sig_260_3 : 11|1@1+ (1,0) [0|1] "" Node10
 SG_ Sig_260_4 : 12|16@1+ (0.1,0) [0|6553.5] "%" Node10
 SG_ Sig_260_5 : 28|12@1+ (0.5,100) [100|2147.5] "%" Node10

BO_ 2147549445 Msg_261: 8 Node10
 SG_ Sig_261_0 : 7|16@0- (2,0) [-65536|65534] "V" Node11
 SG_ Sig_261_1 : 23|16@0+ (0.01,-40) [-40|615.35] "V" Node11
 SG_ Sig_261_2 : 39|16@0+ (0.5,-40) [-40|32727.5] "" Node11
 SG_ Sig_261_3 : 55|8@0+ (0.1,0) [0|25.5] "km/h" Node11
 SG_ Sig_261_4 : 63|8@0+ (1,100) [100|355] "km/h" Node11

BO_ 2147549446 Msg_262: 64 Node11
 SG_ Sig_262_0 : 0|16@1+ (0.25,0) [0|16383.75] "degC" Node12
 SG_ Sig_262_1 : 16|8@1+ (1,0) [0|255] "A" Node12
 SG_ Sig_262_2 : 24|4@1+ (0.1,0) [0|1.5] "degC" Node12
 SG_ Sig_262_3 : 28|8@1+ (2,-0.5) [-0.5|509.5] "%" Node12
 SG_ Sig_262_4 : 36|2@1+ (1,0) [0|3] "" Node12
 SG_ Sig_262_5 : 38|3@1+ (1,0) [0|7] "%" Node12

BO_ 2147549447 Msg_263: 8 Node12
 SG_ Sig_263_0 : 0|8@1- (1,100) [-28|227] "rpm" Node1,Node2
 SG_ Sig_263_1 : 8|4@1- (0.25,-0.5) [-2.5|1.25] "A" Node1,Node2
 SG_ Sig_263_2 : 12|16@1- (2,0) [-65536|65534] "%" Node1,Node2
 SG_ Sig_263_3 : 28|8@1+ (0.25,0) [0|63.75] "V" Node1,Node2
 SG_ Sig_263_4 : 36|12@1- (1,-0.5) [-2048.5|2046.5] "%" Node1,Node2
 SG_ Sig_263_5 : 48|12@1+ (2,-40) [-40|8150] "%" Node1,Node2

BO_ 2147549448 Msg_264: 8 Node1
 SG_ Sig_264_0 : 7|12@0+ (0.1,-0.5) [-0.5|409] "degC" Node2
 SG_ Sig_264_1 : 11|2@0- (0.01,0) [-0.02|0.01] "" Node2
 SG_ Sig_264_2 : 9|8@0+ (0.01,-0.5) [-0.5|2.05] "km/h" Node2
 SG_ Sig_264_3 : 17|8@0+ (0.1,0) [0|25.5] "%" Node2
 SG_ Sig_264_4 : 25|8@0+ (1,0) [0|255] "" Node2
 SG_ Sig_264_5 : 33|2@0+ (0.25,-0.5) [-0.5|0.25] "" Node2

BO_ 2147549449 Msg_265: 6 Node2
 SG_ Sig_265_0 : 7|8@0- (2,0) [-256|254] "A" Node3
 SG_ Sig_265_1 : 15|1@0+ (1,0) [0|1] "" Node3
 SG_ Sig_265_2 : 14|2@0+ (2,0) [0|6] "" Node3
 SG_ Sig_265_3 : 12|12@0- (0.5,100) [-924|1123.5] "degC" Node3
 SG_ Sig_265_4 : 16|8@0+ (1,0) [0|255] "degC" Node3
 SG_ Sig_265_5 : 24|8@0- (2,0) [-256|254] "V" Node3

BO_ 267 Msg_266: 64 Node3
 SG_ Sig_266_0 : 7|16@0- (1,100) [-32668|32867] "degC" Node4
 SG_ Sig_266_1 : 23|12@0+ (1,-40) [-40|4055] "rpm" Node4
 SG_ Sig_266_2 : 27|4@0+ (0.25,0) [0|3.75] "degC" Node4
 SG_ Sig_266_3 : 39|8@0+ (1,-0.5) [-0.5|254.5] "" Node4
 SG_ Sig_266_4 : 47|12@0- (0.5,100) [-924|1123.5] "degC" Node4
 SG_ Sig_266_5 : 51|8@0- (1,-40) [-168|87] "V" Node4

BO_ 268 Msg_267: 24 Node4
 SG_ Sig_267_sel M : 0|8@1+ (0.01,0) [0|2.55] "degC" Node5,Node6
 SG_ Sig_267_a0 m0 : 8|8@1+ (0.5,-40) [-40|87.5] "%" Node5,Node6
 SG_ Sig_267_a1 m0 : 16|12@1- (0.01,0) [-20.48|20.47] "%" Node5,Node6
 SG_ Sig_267_b0 m1 : 8|8@1- (0.01,0) [-1.28|1.27] "" Node5,Node6
 SG_ Sig_267_b1 m1 : 16|8@1+ (0.5,100) [100|227.5] "A" Node5,Node6
 SG_ Sig_267_c0 : 40|12@1- (0.01,-0.5) [-20.98|19.97] "degC" Node5,Node6
 SG_ Sig_267_c1 : 52|4@1+ (0.5,0) [0|7.5] "A" Node5,Node6

BO_ 269 Msg_268: 6 Node5
 SG_ Sig_268_0 : 0|12@1+ (0.01,0) [0|40.95] "%" Node6,Node7
 SG_ Sig_268_1 : 12|8@1+ (2,-40) [-40|470] "degC" Node6,Node7
 SG_ Sig_268_2 : 20|3@1+ (1,-40) [-40|-33] "rpm" Node6,Node7
 SG_ Sig_268_3 : 23|12@1+ (0.01,-0.5) [-0.5|40.45] "km/h" Node6,Node7
 SG_ Sig_268_4 : 35|8@1+ (1,0) [0|255] "" Node6,Node7
 SG_ Sig_268_5 : 43|3@1+ (1,0) [0|7] "A" Node6,Node7

BO_ 270 Msg_269: 8 Node6
 SG_ Sig_269_0 : 0|8@1+ (2,0) [0|510] "V" Node7,Node8
 SG_ Sig_269_1 : 8|8@1+ (1,-40) [-40|215] "km/h" Node7,Node8
 SG_ Sig_269_2 : 16|12@1- (0.5,-40) [-1064|983.5] "V" Node7,Node8
 SG_ Sig_269_3 : 28|8@1+ (0.01,0) [0|2.55] "A" Node7,Node8
 SG_ Sig_269_4 : 36|12@1+ (2,0) [0|8190] "%" Node7,Node8
 SG_ Sig_269_5 : 48|8@1+ (0.25,0) [0|63.75] "V" Node7,Node8

BO_ 271 Msg_270: 8 Node7
 SG_ Sig_270_0 : 7|8@0+ (2,0) [0|510] "rpm" Node8
 SG_ Sig_270_1 : 15|16@0+ (0.5,0) [0|32767.5] "%" Node8
 SG_ Sig_270_2 : 31|4@0+ (1,100) [100|115] "" Node8
 SG_ Sig_270_3 : 27|3@0+ (0.25,0) [0|1.75] "km/h" Node8
 SG_ Sig_270_4 : 24|2@0- (0.5,-0.5) [-1.5|0] "" Node8
 SG_ Sig_270_5 : 38|2@0+ (1,100) [100|103] "" Node8

BO_ 272 Msg_271: 12 Node8
 SG_ Sig_271_sel M : 0|8@1+ (0.25,0) [0|63.75] "" Node9,Node10
 SG_ Sig_271_a0 m0 : 8|3@1+ (1,0) [0|7] "km/h" Node9,Node10
 SG_ Sig_271_a1 m0 : 11|16@1+ (0.25,-0.5) [-0.5|16383.25] "km/h" Node9,Node10
 SG_ Sig_271_b0 m1 : 8|4@1+ (1,0) [0|15] "A" Node9,Node10
 SG_ Sig_271_b1 m1 : 12|4@1+ (0.01,0) [0|0.15] "degC" Node9,Node10
 SG_ Sig_271_c0 : 40|2@1- (1,-40) [-42|-39] "" Node9,Node10
 SG_ Sig_271_c1 : 42|3@1- (1,-40) [-44|-37] "V" Node9,Node10

BO_ 273 Msg_272: 6 Node9
 SG_ Sig_272_0 : 7|3@0- (0.25,-40) [-41|-39.25] "%" Node10,Node11
 SG_ Sig_272_1 : 4|16@0- (1,0) [-32768|32767] "km/h" Node10,Node11
 SG_ Sig_272_2 : 20|4@0- (0.1,0) [-0.8|0.7] "%" Node10,Node11
 SG_ Sig_272_3 : 16|8@0- (1,-0.5) [-128.5|126.5] "V" Node10,Node11
 SG_ Sig_272_4 : 24|8@0- (2,-0.5) [-256.5|253.5] "%" Node10,Node11
 SG_ Sig_272_5 : 32|4@0+ (1,0) [0|15] "V" Node10,Node11

BO_ 274 Msg_273: 64 Node10
 SG_ Sig_273_0 : 7|1@0+ (1,0) [0|1] "" Node11
 SG_ Sig_273_1 : 6|3@0+ (0.5,-40) [-40|-36.5] "" Node11
 SG_ Sig_273_2 : 3|4@0+ (2,-40) [-40|-10] "degC" Node11
 SG_ Sig_273_3 : 15|8@0- (1,0) [-128|127] "" Node11
 SG_ Sig_273_4 : 23|8@0+ (1,-40) [-40|215] "km/h" Node11
 SG_ Sig_273_5 : 31|8@0+ (0.1,0) [0|25.5] "degC" Node11

BO_ 275 Msg_274: 8 Node11
 SG_ Sig_274_0 : 0|8@1+ (1,0) [0|255] "%" Node12,Node1
 SG_ Sig_274_1 : 8|8@1+ (0.01,100) [100|102.55] "rpm" Node12,Node1
 SG_ Sig_274_2 : 16|1@1+ (1,0) [0|1] "" Node12,Node1
 SG_ Sig_274_3 : 17|8@1+ (1,-0.5) [-0.5|254.5] "%" Node12,Node1
 SG_ Sig_274_4 : 25|16@1+ (1,-0.5) [-0.5|65534.5] "degC" Node12,Node1
 SG_ Sig_274_5 : 41|1@1+ (1,0) [0|1] "" Node12,Node1

BO_ 276 Msg_275: 8 Node12
 SG_ Sig_275_0 : 7|8@0+ (1,0) [0|255] "rpm" Node1
 SG_ Sig_275_1 : 15|12@0+ (0.1,0) [0|409.5] "degC" Node1
 SG_ Sig_275_2 : 19|8@0+ (0.1,0) [0|25.5] "km/h" Node1
 SG_ Sig_275_3 : 27|2@0+ (0.5,-40) [-40|-38.5] "" Node1
 SG_ Sig_275_4 : 25|16@0+ (0.01,0) [0|655.35] "" Node1
 SG_ Sig_275_5 : 41|2@0+ (0.5,0) [0|1.5] "" Node1

BO_ 277 Msg_276: 8 Node1
 SG_ Sig_276_0 : 7|8@0- (2,0) [-256|254] "" Node2
 SG_ Sig_276_1 : 15|1@0+ (1,0) [0|1] "" Node2
 SG_ Sig_276_2 : 14|3@0- (1,100) [96|103] "" Node2
 SG_ Sig_276_3 : 11|3@0+ (0.25,0) [0|1.75] "km/h" Node2
 SG_ Sig_276_4 : 8|12@0+ (1,0) [0|4095] "degC" Node2
 SG_ Sig_276_5 : 28|12@0+ (0.5,0) [0|2047.5] "degC" Node2

BO_ 278 Msg_277: 24 Node2
 SG_ Sig_277_0 : 7|3@0+ (2,0) [0|14] "V" Node3,Node4
 SG_ Sig_277_1 : 4|1@0+ (1,0) [0|1] "" Node3,Node4
 SG_ Sig_277_2 : 3|3@0- (0.1,-0.5) [-0.9|-0.2] "km/h" Node3,Node4
 SG_ Sig_277_3 : 0|3@0+ (0.1,-40) [-40|-39.3] "" Node3,Node4
 SG_ Sig_277_4 : 13|4@0+ (0.5,100) [100|107.5] "V" Node3,Node4
 SG_ Sig_277_5 : 9|16@0+ (0.25,0) [0|16383.75] "" Node3,Node4

BO_ 279 Msg_278: 8 Node3
 SG_ Sig_278_0 : 0|2@1+ (0.5,0) [0|1.5] "" Node4
 SG_ Sig_278_1 : 2|2@1+ (1,0) [0|3] "" Node4
 SG_ Sig_278_2 : 4|1@1+ (1,0) [0|1] "" Node4
 SG_ Sig_278_3 : 5|3@1+ (0.1,0) [0|0.7] "" Node4
 SG_ Sig_278_4 : 8|4@1+ (0.25,0) [0|3.75] "A" Node4
 SG_ Sig_278_5 : 12|8@1+ (2,0) [0|510] "km/h" Node4

BO_ 280 Msg_279: 8 Node4
 SG_ Sig_279_0 : 7|2@0+ (0.01,100) [100|100.03] "" Node5,Node6
 SG_ Sig_279_1 : 5|3@0+ (0.1,0) [0|0.7] "rpm" Node5,Node6
 SG_ Sig_279_2 : 2|1@0+ (1,0) [0|1] "" Node5,Node6
 SG_ Sig_279_3 : 1|16@0+ (0.1,0) [0|6553.5] "V" Node5,Node6
 SG_ Sig_279_4 : 17|8@0+ (0.25,-40) [-40|23.75] "A" Node5,Node6
 SG_ Sig_279_5 : 25|3@0+ (0.5,0) [0|3.5] "km/h" Node5,Node6

BO_ 281 Msg_280: 4 Node5
 SG_ Sig_280_0 : 0|16@1+ (0.5,100) [100|32867.5] "" Node6,Node7
 SG_ Sig_280_1 : 16|3@1- (0.1,0) [-0.4|0.3] "A" Node6,Node7
 SG_ Sig_280_2 : 19|4@1+ (1,-40) [-40|-25] "rpm" Node6,Node7
 SG_ Sig_280_3 : 23|8@1- (0.1,-40) [-52.8|-27.3] "" Node6,Node7
 SG_ Sig_280_4 : 31|1@1+ (1,0) [0|1] "" Node6,Node7

BO_ 282 Msg_281: 8 Node6
 SG_ Sig_281_0 : 0|16@1- (1,0) [-32768|32767] "rpm" Node7
 SG_ Sig_281_1 : 16|3@1+ (0.25,0) [0|1.75] "V" Node7
 SG_ Sig_281_2 : 19|8@1+ (0.25,0) [0|63.75] "" Node7
 SG_ Sig_281_3 : 27|8@1+ (1,-40) [-40|215] "A" Node7
 SG_ Sig_281_4 : 35|16@1+ (0.25,0) [0|16383.75] "%" Node7
 SG_ Sig_281_5 : 51|4@1+ (0.25,-40) [-40|-36.25] "" Node7

BO_ 283 Msg_282: 6 Node7
 SG_ Sig_282_0 : 7|1@0+ (1,0) [0|1] "" Node8
 SG_ Sig_282_1 : 6|16@0+ (1,-0.5) [-0.5|65534.5] "rpm" Node8
 SG_ Sig_282_2 : 22|8@0+ (0.01,0) [0|2.55] "degC" Node8
 SG_ Sig_282_3 : 30|8@0- (2,-40) [-296|214] "V" Node8
 SG_ Sig_282_4 : 38|8@0+ (1,0) [0|255] "km/h" Node8
 SG_ Sig_282_5 : 46|1@0+ (1,0) [0|1] "" Node8

BO_ 2147549467 Msg_283: 8 Node8
 SG_ Sig_283_0 : 0|1@1+ (1,0) [0|1] "" Node9
 SG_ Sig_283_1 : 1|8@1+ (2,100) [100|610] "A" Node9
 SG_ Sig_283_2 : 9|8@1- (1,0) [-128|127] "rpm" Node9
 SG_ Sig_283_3 : 17|2@1- (0.25,-40) [-40.5|-39.75] "" Node9
 SG_ Sig_283_4 : 19|4@1+ (0.25,0) [0|3.75] "degC" Node9
 SG_ Sig_283_5 : 23|1@1+ (1,0) [0|1] "" Node9

BO_ 285 Msg_284: 64 Node9
 SG_ Sig_284_0 : 7|12@0- (0.5,-0.5) [-1024.5|1023] "degC" Node10
 SG_ Sig_284_1 : 11|1@0+ (1,0) [0|1] "" Node10
 SG_ Sig_284_2 : 10|8@0- (0.1,-40) [-52.8|-27.3] "km/h" Node10
 SG_ Sig_284_3 : 18|8@0+ (1,-40) [-40|215] "" Node10
 SG_ Sig_284_4 : 26|16@0+ (0.01,-0.5) [-0.5|654.85] "A" Node10
 SG_ Sig_284_5 : 42|8@0- (0.25,0) [-32|31.75] "V" Node10

BO_ 286 Msg_285: 32 Node10
 SG_ Sig_285_0 : 0|8@1+ (1,0) [0|255] "A" Node11,Node12
 SG_ Sig_285_1 : 8|8@1- (0.1,0) [-12.8|12.7] "degC" Node11,Node12
 SG_ Sig_285_2 : 16|4@1+ (0.25,100) [100|103.75] "V" Node11,Node12
 SG_ Sig_285_3 : 20|2@1+ (0.5,100) [100|101.5] "" Node11,Node12
 SG_ Sig_285_4 : 22|8@1+ (0.25,100) [100|163.75] "%" Node11,Node12
 SG_ Sig_285_5 : 30|16@1- (0.25,0) [-8192|8191.75] "V" Node11,Node12

BO_ 287 Msg_286: 32 Node11
 SG_ Sig_286_0 : 0|8@1+ (2,0) [0|510] "rpm" Node12
 SG_ Sig_286_1 : 8|1@1+ (1,0) [0|1] "" Node12
 SG_ Sig_286_2 : 9|2@1+ (1,100) [100|103] "" Node12
 SG_ Sig_286_3 : 11|3@1- (1,0) [-4|3] "V" Node12
 SG_ Sig_286_4 : 14|4@1+ (1,0) [0|15] "" Node12
 SG_ Sig_286_5 : 18|8@1+ (2,0) [0|510] "" Node12

BO_ 288 Msg_287: 8 Node12
 SG_ Sig_287_0 : 0|12@1+ (2,100) [100|8290] "V" Node1
 SG_ Sig_287_1 : 12|16@1- (0.25,0) [-8192|8191.75] "V" Node1
 SG_ Sig_287_2 : 28|16@1- (1,0) [-32768|32767] "A" Node1
 SG_ Sig_287_3 : 44|4@1- (0.01,100) [99.92|100.07] "A" Node1
 SG_ Sig_287_4 : 48|12@1+ (2,0) [0|8190] "degC" Node1
 SG_ Sig_287_5 : 60|4@1- (0.25,0) [-2|1.75] "V" Node1

BO_ 289 Msg_288: 8 Node1
 SG_ Sig_288_0 : 0|4@1+ (0.25,-0.5) [-0.5|3.25] "km/h" Node2
 SG_ Sig_288_1 : 4|8@1- (0.25,0) [-32|31.75] "rpm" Node2
 SG_ Sig_288_2 : 12|16@1- (1,0) [-32768|32767] "A" Node2
 SG_ Sig_288_3 : 28|16@1+ (0.1,0) [0|6553.5] "%" Node2
 SG_ Sig_288_4 : 44|8@1+ (0.01,0) [0|2.55] "V" Node2
 SG_ Sig_288_5 : 52|4@1- (1,-0.5) [-8.5|6.5] "V" Node2

BO_ 2147549473 Msg_289: 8 Node2
 SG_ Sig_289_0 : 7|1@0+ (1,0) [0|1] "" Node3,Node4
 SG_ Sig_289_1 : 6|16@0+ (0.25,100) [100|16483.75] "rpm" Node3,Node4
 SG_ Sig_289_2 : 22|12@0+ (0.5,0) [0|2047.5] "A" Node3,Node4
 SG_ Sig_289_3 : 26|4@0- (0.25,-0.5) [-2.5|1.25] "degC" Node3,Node4
 SG_ Sig_289_4 : 38|16@0+ (0.5,-0.5) [-0.5|32767] "A" Node3,Node4
 SG_ Sig_289_5 : 54|12@0+ (1,0) [0|4095] "%" Node3,Node4

BO_ 291 Msg_290: 8 Node3
 SG_ Sig_290_0 : 7|3@0- (0.25,100) [99|100.75] "km/h" Node4,Node5
 SG_ Sig_290_1 : 4|12@0- (1,-40) [-2088|2007] "V" Node4,Node5
 SG_ Sig_290_2 : 8|4@0+ (0.5,-0.5) [-0.5|7] "%" Node4,Node5
 SG_ Sig_290_3 : 20|2@0+ (2,0) [0|6] "" Node4,Node5
 SG_ Sig_290_4 : 18|12@0+ (0.25,0) [0|1023.75] "A" Node4,Node5
 SG_ Sig_290_5 : 38|1@0+ (1,0) [0|1] "" Node4,Node5

BO_ 292 Msg_291: 8 Node4
 SG_ Sig_291_0 : 7|2@0+ (1,0) [0|3] "" Node5
 SG_ Sig_291_1 : 5|12@0+ (0.5,0) [0|2047.5] "A" Node5
 SG_ Sig_291_2 : 9|12@0+ (0.25,100) [100|1123.75] "V" Node5
 SG_ Sig_291_3 : 29|8@0+ (0.1,0) [0|25.5] "km/h" Node5
 SG_ Sig_291_4 : 37|4@0+ (0.25,0) [0|3.75] "km/h" Node5
 SG_ Sig_291_5 : 33|8@0+ (2,0) [0|510] "degC" Node5

BO_ 293 Msg_292: 16 Node5
 SG_ Sig_292_0 : 7|12@0+ (0.01,0) [0|40.95] "A" Node6,Node7
 SG_ Sig_292_1 : 11|16@0+ (2,0) [0|131070] "degC" Node6,Node7
 SG_ Sig_292_2 : 27|8@0+ (0.01,-0.5) [-0.5|2.05] "V" Node6,Node7
 SG_ Sig_292_3 : 35|3@0+ (0.1,-0.5) [-0.5|0.2] "rpm" Node6,Node7
 SG_ Sig_292_4 : 32|3@0- (0.5,-40) [-42|-38.5] "rpm" Node6,Node7
 SG_ Sig_292_5 : 45|4@0+ (0.25,0) [0|3.75] "degC" Node6,Node7

BO_ 294 Msg_293: 8 Node6
 SG_ Sig_293_sel M : 0|8@1+ (0.25,-0.5) [-0.5|63.25] "%" Node7,Node8
 SG_ Sig_293_a0 m0 : 8|4@1+ (0.5,0) [0|7.5] "A" Node7,Node8
 SG_ Sig_293_a1 m0 : 12|3@1+ (1,100) [100|107] "V" Node7,Node8
 SG_ Sig_293_b0 m1 : 8|2@1+ (0.01,-0.5) [-0.5|-0.47] "" Node7,Node8
 SG_ Sig_293_b1 m1 : 10|1@1+ (1,0) [0|1] "" Node7,Node8
 SG_ Sig_293_c0 : 40|8@1- (0.5,-0.5) [-64.5|63] "V" Node7,Node8
 SG_ Sig_293_c1 : 48|12@1- (0.5,0) [-1024|1023.5] "%" Node7,Node8

BO_ 295 Msg_294: 24 Node7
 SG_ Sig_294_0 : 7|2@0+ (0.5,0) [0|1.5] "" Node8
 SG_ Sig_294_1 : 5|4@0+ (1,0) [0|15] "V" Node8
 SG_ Sig_294_2 : 1|1@0+ (1,0) [0|1] "" Node8
 SG_ Sig_294_3 : 0|2@0+ (0.25,100) [100|100.75] "" Node8
 SG_ Sig_294_4 : 14|16@0- (0.25,0) [-8192|8191.75] "" Node8
 SG_ Sig_294_5 : 30|16@0+ (2,100) [100|131170] "" Node8

BO_ 296 Msg_295: 8 Node8
 SG_ Sig_295_0 : 7|8@0+ (1,0) [0|255] "rpm" Node9
 SG_ Sig_295_1 : 15|2@0+ (0.5,0) [0|1.5] "" Node9
 SG_ Sig_295_2 : 13|2@0+ (2,-0.5) [-0.5|5.5] "" Node9
 SG_ Sig_295_3 : 11|16@0- (0.01,0) [-327.68|327.67] "A" Node9
 SG_ Sig_295_4 : 27|16@0+ (0.25,0) [0|16383.75] "%" Node9
 SG_ Sig_295_5 : 43|12@0+ (0.25,-40) [-40|983.75] "rpm" Node9

BO_ 297 Msg_296: 32 Node9
 SG_ Sig_296_0 : 7|8@0+ (1,0) [0|255] "km/h" Node10,Node11
 SG_ Sig_296_1 : 15|3@0- (2,0) [-8|6] "" Node10,Node11
 SG_ Sig_296_2 : 12|8@0+ (1,0) [0|255] "A" Node10,Node11
 SG_ Sig_296_3 : 20|16@0+ (0.5,100) [100|32867.5] "degC" Node10,Node11
 SG_ Sig_296_4 : 36|8@0- (0.5,0) [-64|63.5] "rpm" Node10,Node11
 SG_ Sig_296_5 : 44|1@0+ (1,0) [0|1] "" Node10,Node11

BO_ 298 Msg_297: 24 Node10
 SG_ Sig_297_sel M : 0|8@1+ (0.25,-40) [-40|23.75] "%" Node11
 SG_ Sig_297_a0 m0 : 8|2@1+ (0.5,-0.5) [-0.5|1] "" Node11
 SG_ Sig_297_a1 m0 : 10|16@1+ (0.01,0) [0|655.35] "V" Node11
 SG_ Sig_297_b0 m1 : 8|4@1+ (2,0) [0|30] "rpm" Node11
 SG_ Sig_297_b1 m1 : 12|3@1+ (0.1,0) [0|0.7] "A" Node11
 SG_ Sig_297_c0 : 40|8@1+ (0.5,0) [0|127.5] "%" Node11
 SG_ Sig_297_c1 : 48|16@1+ (2,0) [0|131070] "%" Node11

BO_ 2147549482 Msg_298: 12 Node11
 SG_ Sig_298_0 : 0|2@1+ (0.25,0) [0|0.75] "" Node12
 SG_ Sig_298_1 : 2|8@1+ (1,0) [0|255] "rpm" Node12
 SG_ Sig_298_2 : 10|4@1- (1,-0.5) [-8.5|6.5] "" Node12
 SG_ Sig_298_3 : 14|3@1+ (0.01,0) [0|0.07] "degC" Node12
 SG_ Sig_298_4 : 17|12@1+ (0.1,0) [0|409.5] "V" Node12
 SG_ Sig_298_5 : 29|2@1- (2,-0.5) [-4.5|1.5] "" Node12

BO_ 300 Msg_299: 16 Node12
 SG_ Sig_299_0 : 0|1@1+ (1,0) [0|1] "" Node1
 SG_ Sig_299_1 : 1|8@1+ (0.1,0) [0|25.5] "km/h" Node1
 SG_ Sig_299_2 : 9|2@1- (1,-0.5) [-2.5|0.5] "" Node1
 SG_ Sig_299_3 : 11|1@1+ (1,0) [0|1] "" Node1
 SG_ Sig_299_4 : 12|2@1+ (0.25,0) [0|0.75] "" Node1
 SG_ Sig_299_5 : 14|12@1- (0.01,0) [-20.48|20.47] "km/h" Node1

CM_ BO_ 1 "Message number 0 of the synthetic network.";
CM_ BO_ 2147549191 "Message number 7 of the synthetic network.";
CM_ BO_ 15 "Message number 14 of the synthetic network.";
CM_ BO_ 22 "Message number 21 of the synthetic network.";
CM_ BO_ 29 "Message number 28 of the synthetic network.";
CM_ BO_ 36 "Message number 35 of the synthetic network.";
CM_ BO_ 43 "Message number 42 of the synthetic network.";
CM_ BO_ 50 "Message number 49 of the synthetic network.";
CM_ BO_ 57 "Message number 56 of the synthetic network.";
CM_ BO_ 64 "Message number 63 of the synthetic network.";
CM_ BO_ 71 "Message number 70 of the synthetic network.";
CM_ BO_ 78 "Message number 77 of the synthetic network.";
CM_ BO_ 85 "Message number 84 of the synthetic network.";
CM_ BO_ 2147549275 "Message number 91 of the synthetic network.";
CM_ BO_ 99 "Message number 98 of the synthetic network.";
CM_ BO_ 106 "Message number 105 of the synthetic network.";
CM_ BO_ 113 "Message number 112 of the synthetic network.";
CM_ BO_ 120 "Message number 119 of the synthetic network.";
CM_ BO_ 127 "Message number 126 of the synthetic network.";
CM_ BO_ 134 "Message number 133 of the synthetic network.";
CM_ BO_ 141 "Message number 140 of the synthetic network.";
CM_ BO_ 148 "Message number 147 of the synthetic network.";
CM_ BO_ 155 "Message number 154 of the synthetic network.";
CM_ BO_ 162 "Message number 161 of the synthetic network.";
CM_ BO_ 169 "Message number 168 of the synthetic network.";
CM_ BO_ 2147549359 "Message number 175 of the synthetic network.";
CM_ BO_ 183 "Message number 182 of the synthetic network.";
CM_ BO_ 2147549373 "Message number 189 of the synthetic network.";
CM_ BO_ 197 "Message number 196 of the synthetic network.";
CM_ BO_ 204 "Message number 203 of the synthetic network.";
CM_ BO_ 211 "Message number 210 of the synthetic network.";
CM_ BO_ 218 "Message number 217 of the synthetic network.";
CM_ BO_ 225 "Message number 224 of the synthetic network.";
CM_ BO_ 232 "Message number 231 of the synthetic network.";
CM_ BO_ 2147549422 "Message number 238 of the synthetic network.";
CM_ BO_ 246 "Message number 245 of the synthetic network.";
CM_ BO_ 2147549436 "Message number 252 of the synthetic network.";
CM_ BO_ 260 "Message number 259 of the synthetic network.";
CM_ BO_ 267 "Message number 266 of the synthetic network.";
CM_ BO_ 274 "Message number 273 of the synthetic network.";
CM_ BO_ 281 "Message number 280 of the synthetic network.";
CM_ BO_ 288 "Message number 287 of the synthetic network.";
CM_ BO_ 295 "Message number 294 of the synthetic network.";
BA_DEF_ BO_ "GenMsgCycleTime" INT 0 65535;
BA_DEF_ BO_ "VFrameFormat" ENUM "StandardCAN","ExtendedCAN";
BA_DEF_DEF_ "GenMsgCycleTime" 0;
BA_DEF_DEF_ "VFrameFormat" "StandardCAN";
BA_ "GenMsgCycleTime" BO_ 1 330;
BA_ "GenMsgCycleTime" BO_ 2147549185 70;
BA_ "VFrameFormat" BO_ 2147549185 1;
BA_ "GenMsgCycleTime" BO_ 3 420;
BA_ "GenMsgCycleTime" BO_ 4 390;
BA_ "GenMsgCycleTime" BO_ 5 10;
BA_ "GenMsgCycleTime" BO_ 2147549189 370;
BA_ "VFrameFormat" BO_ 2147549189 1;
BA_ "GenMsgCycleTime" BO_ 7 960;
BA_ "GenMsgCycleTime" BO_ 2147549191 470;
BA_ "VFrameFormat" BO_ 2147549191 1;
BA_ "GenMsgCycleTime" BO_ 2147549192 910;
BA_ "VFrameFormat" BO_ 2147549192 1;
BA_ "GenMsgCycleTime" BO_ 2147549193 800;
BA_ "VFrameFormat" BO_ 2147549193 1;
BA_ "GenMsgCycleTime" BO_ 11 280;
BA_ "GenMsgCycleTime" BO_ 12 720;
BA_ "GenMsgCycleTime" BO_ 13 860;
BA_ "GenMsgCycleTime" BO_ 14 550;
BA_ "GenMsgCycleTime" BO_ 15 370;
BA_ "GenMsgCycleTime" BO_ 16 150;
BA_ "GenMsgCycleTime" BO_ 17 400;
BA_ "GenMsgCycleTime" BO_ 18 840;
BA_ "GenMsgCycleTime" BO_ 2147549202 10;
BA_ "VFrameFormat" BO_ 2147549202 1;
BA_ "GenMsgCycleTime" BO_ 20 980;
BA_ "GenMsgCycleTime" BO_ 21 930;
BA_ "GenMsgCycleTime" BO_ 22 170;
BA_ "GenMsgCycleTime" BO_ 23 890;
BA_ "GenMsgCycleTime" BO_ 2147549207 120;
BA_ "VFrameFormat" BO_ 2147549207 1;
BA_ "GenMsgCycleTime" BO_ 25 170;
BA_ "GenMsgCycleTime" BO_ 26 620;
BA_ "GenMsgCycleTime" BO_ 27 690;
BA_ "GenMsgCycleTime" BO_ 28 370;
BA_ "GenMsgCycleTime" BO_ 29 750;
BA_ "GenMsgCycleTime" BO_ 30 780;
BA_ "GenMsgCycleTime" BO_ 31 220;
BA_ "GenMsgCycleTime" BO_ 32 920;
BA_ "GenMsgCycleTime" BO_ 33 140;
BA_ "GenMsgCycleTime" BO_ 34 580;
BA_ "GenMsgCycleTime" BO_ 2147549218 990;
BA_ "VFrameFormat" BO_ 2147549218 1;
BA_ "GenMsgCycleTime" BO_ 36 120;
BA_ "GenMsgCycleTime" BO_ 37 620;
BA_ "GenMsgCycleTime" BO_ 38 330;
BA_ "GenMsgCycleTime" BO_ 39 680;
BA_ "GenMsgCycleTime" BO_ 40 870;
BA_ "GenMsgCycleTime" BO_ 41 310;
BA_ "GenMsgCycleTime" BO_ 2147549225 60;
BA_ "VFrameFormat" BO_ 2147549225 1;
BA_ "GenMsgCycleTime" BO_ 43 890;
BA_ "GenMsgCycleTime" BO_ 44 740;
BA_ "GenMsgCycleTime" BO_ 2147549228 390;
BA_ "VFrameFormat" BO_ 2147549228 1;
BA_ "GenMsgCycleTime" BO_ 46 20;
BA_ "GenMsgCycleTime" BO_ 47 680;
BA_ "GenMsgCycleTime" BO_ 2147549231 130;
BA_ "VFrameFormat" BO_ 2147549231 1;
BA_ "GenMsgCycleTime" BO_ 49 470;
BA_ "GenMsgCycleTime" BO_ 50 900;
BA_ "GenMsgCycleTime" BO_ 51 660;
BA_ "GenMsgCycleTime" BO_ 52 80;
BA_ "GenMsgCycleTime" BO_ 53 830;
BA_ "GenMsgCycleTime" BO_ 2147549237 600;
BA_ "VFrameFormat" BO_ 2147549237 1;
BA_ "GenMsgCycleTime" BO_ 2147549238 420;
BA_ "VFrameFormat" BO_ 2147549238 1;
BA_ "GenMsgCycleTime" BO_ 56 920;
BA_ "GenMsgCycleTime" BO_ 57 210;
BA_ "GenMsgCycleTime" BO_ 58 300;
BA_ "GenMsgCycleTime" BO_ 59 320;
BA_ "GenMsgCycleTime" BO_ 60 50;
BA_ "GenMsgCycleTime" BO_ 61 980;
BA_ "GenMsgCycleTime" BO_ 62 820;
BA_ "GenMsgCycleTime" BO_ 63 900;
BA_ "GenMsgCycleTime" BO_ 64 240;
BA_ "GenMsgCycleTime" BO_ 65 40;
BA_ "GenMsgCycleTime" BO_ 2147549249 170;
BA_ "VFrameFormat" BO_ 2147549249 1;
BA_ "GenMsgCycleTime" BO_ 67 340;
BA_ "GenMsgCycleTime" BO_ 68 280;
BA_ "GenMsgCycleTime" BO_ 2147549252 840;
BA_ "VFrameFormat" BO_ 2147549252 1;
BA_ "GenMsgCycleTime" BO_ 70 670;
BA_ "GenMsgCycleTime" BO_ 71 20;
BA_ "GenMsgCycleTime" BO_ 72 1000;
BA_ "GenMsgCycleTime" BO_ 73 50;
BA_ "GenMsgCycleTime" BO_ 74 20;
BA_ "GenMsgCycleTime" BO_ 75 540;
BA_ "GenMsgCycleTime" BO_ 76 660;
BA_ "GenMsgCycleTime" BO_ 77 760;
BA_ "GenMsgCycleTime" BO_ 78 130;
BA_ "GenMsgCycleTime" BO_ 79 590;
BA_ "GenMsgCycleTime" BO_ 2147549263 30;
BA_ "VFrameFormat" BO_ 2147549263 1;
BA_ "GenMsgCycleTime" BO_ 2147549264 380;
BA_ "VFrameFormat" BO_ 2147549264 1;
BA_ "GenMsgCycleTime" BO_ 2147549265 480;
BA_ "VFrameFormat" BO_ 2147549265 1;
BA_ "GenMsgCycleTime" BO_ 83 120;
BA_ "GenMsgCycleTime" BO_ 84 440;
BA_ "GenMsgCycleTime" BO_ 85 120;
BA_ "GenMsgCycleTime" BO_ 86 370;
BA_ "GenMsgCycleTime" BO_ 87 740;
BA_ "GenMsgCycleTime" BO_ 88 470;
BA_ "GenMsgCycleTime" BO_ 89 670;
BA_ "GenMsgCycleTime" BO_ 90 120;
BA_ "GenMsgCycleTime" BO_ 91 520;
BA_ "GenMsgCycleTime" BO_ 2147549275 280;
BA_ "VFrameFormat" BO_ 2147549275 1;
BA_ "GenMsgCycleTime" BO_ 2147549276 490;
BA_ "VFrameFormat" BO_ 2147549276 1;
BA_ "GenMsgCycleTime" BO_ 2147549277 570;
BA_ "VFrameFormat" BO_ 2147549277 1;
BA_ "GenMsgCycleTime" BO_ 95 710;
BA_ "GenMsgCycleTime" BO_ 96 900;
BA_ "GenMsgCycleTime" BO_ 97 190;
BA_ "GenMsgCycleTime" BO_ 98 990;
BA_ "GenMsgCycleTime" BO_ 99 520;
BA_ "GenMsgCycleTime" BO_ 100 150;
BA_ "GenMsgCycleTime" BO_ 101 450;
BA_ "GenMsgCycleTime" BO_ 2147549285 470;
BA_ "VFrameFormat" BO_ 2147549285 1;
BA_ "GenMsgCycleTime" BO_ 103 210;
BA_ "GenMsgCycleTime" BO_ 104 270;
BA_ "GenMsgCycleTime" BO_ 2147549288 1000;
BA_ "VFrameFormat" BO_ 2147549288 1;
BA_ "GenMsgCycleTime" BO_ 106 370;
BA_ "GenMsgCycleTime" BO_ 107 250;
BA_ "GenMsgCycleTime" BO_ 108 580;
BA_ "GenMsgCycleTime" BO_ 2147549292 440;
BA_ "VFrameFormat" BO_ 2147549292 1;
BA_ "GenMsgCycleTime" BO_ 110 980;
BA_ "GenMsgCycleTime" BO_ 111 780;
BA_ "GenMsgCycleTime" BO_ 112 50;
BA_ "GenMsgCycleTime" BO_ 113 20;
BA_ "GenMsgCycleTime" BO_ 114 490;
BA_ "GenMsgCycleTime" BO_ 2147549298 170;
BA_ "VFrameFormat" BO_ 2147549298 1;
BA_ "GenMsgCycleTime" BO_ 116 750;
BA_ "GenMsgCycleTime" BO_ 117 490;
BA_ "GenMsgCycleTime" BO_ 2147549301 30;
BA_ "VFrameFormat" BO_ 2147549301 1;
BA_ "GenMsgCycleTime" BO_ 119 460;
BA_ "GenMsgCycleTime" BO_ 120 270;
BA_ "GenMsgCycleTime" BO_ 121 250;
BA_ "GenMsgCycleTime" BO_ 2147549305 1000;
BA_ "VFrameFormat" BO_ 2147549305 1;
BA_ "GenMsgCycleTime" BO_ 123 130;
BA_ "GenMsgCycleTime" BO_ 124 810;
BA_ "GenMsgCycleTime" BO_ 125 600;
BA_ "GenMsgCycleTime" BO_ 126 820;
BA_ "GenMsgCycleTime" BO_ 127 830;
BA_ "GenMsgCycleTime" BO_ 128 970;
BA_ "GenMsgCycleTime" BO_ 129 740;
BA_ "GenMsgCycleTime" BO_ 130 330;
BA_ "GenMsgCycleTime" BO_ 2147549314 890;
BA_ "VFrameFormat" BO_ 2147549314 1;
BA_ "GenMsgCycleTime" BO_ 132 680;
BA_ "GenMsgCycleTime" BO_ 133 20;
BA_ "GenMsgCycleTime" BO_ 134 940;
BA_ "GenMsgCycleTime" BO_ 135 860;
BA_ "GenMsgCycleTime" BO_ 136 770;
BA_ "GenMsgCycleTime" BO_ 137 60;
BA_ "GenMsgCycleTime" BO_ 138 480;
BA_ "GenMsgCycleTime" BO_ 139 70;
BA_ "GenMsgCycleTime" BO_ 140 470;
BA_ "GenMsgCycleTime" BO_ 141 490;
BA_ "GenMsgCycleTime" BO_ 2147549325 760;
BA_ "VFrameFormat" BO_ 2147549325 1;
BA_ "GenMsgCycleTime" BO_ 2147549326 320;
BA_ "VFrameFormat" BO_ 2147549326 1;
BA_ "GenMsgCycleTime" BO_ 144 590;
BA_ "GenMsgCycleTime" BO_ 145 340;
BA_ "GenMsgCycleTime" BO_ 146 280;
BA_ "GenMsgCycleTime" BO_ 147 620;
BA_ "GenMsgCycleTime" BO_ 148 60;
BA_ "GenMsgCycleTime" BO_ 149 960;
BA_ "GenMsgCycleTime" BO_ 2147549333 400;
BA_ "VFrameFormat" BO_ 2147549333 1;
BA_ "GenMsgCycleTime" BO_ 151 630;
BA_ "GenMsgCycleTime" BO_ 152 440;
BA_ "GenMsgCycleTime" BO_ 153 980;
BA_ "GenMsgCycleTime" BO_ 154 470;
BA_ "GenMsgCycleTime" BO_ 155 290;
BA_ "GenMsgCycleTime" BO_ 156 320;
BA_ "GenMsgCycleTime" BO_ 157 720;
BA_ "GenMsgCycleTime" BO_ 158 990;
BA_ "GenMsgCycleTime" BO_ 159 420;
BA_ "GenMsgCycleTime" BO_ 160 900;
BA_ "GenMsgCycleTime" BO_ 2147549344 550;
BA_ "VFrameFormat" BO_ 2147549344 1;
BA_ "GenMsgCycleTime" BO_ 162 810;
BA_ "GenMsgCycleTime" BO_ 163 850;
BA_ "GenMsgCycleTime" BO_ 164 130;
BA_ "GenMsgCycleTime" BO_ 2147549348 950;
BA_ "VFrameFormat" BO_ 2147549348 1;
BA_ "GenMsgCycleTime" BO_ 166 760;
BA_ "GenMsgCycleTime" BO_ 167 860;
BA_ "GenMsgCycleTime" BO_ 168 220;
BA_ "GenMsgCycleTime" BO_ 169 460;
BA_ "GenMsgCycleTime" BO_ 170 170;
BA_ "GenMsgCycleTime" BO_ 171 760;
BA_ "GenMsgCycleTime" BO_ 172 330;
BA_ "GenMsgCycleTime" BO_ 173 230;
BA_ "GenMsgCycleTime" BO_ 174 870;
BA_ "GenMsgCycleTime" BO_ 175 890;
BA_ "GenMsgCycleTime" BO_ 2147549359 340;
BA_ "VFrameFormat" BO_ 2147549359 1;
BA_ "GenMsgCycleTime" BO_ 2147549360 280;
BA_ "VFrameFormat" BO_ 2147549360 1;
BA_ "GenMsgCycleTime" BO_ 178 580;
BA_ "GenMsgCycleTime" BO_ 179 380;
BA_ "GenMsgCycleTime" BO_ 180 470;
BA_ "GenMsgCycleTime" BO_ 181 780;
BA_ "GenMsgCycleTime" BO_ 182 770;
BA_ "GenMsgCycleTime" BO_ 183 410;
BA_ "GenMsgCycleTime" BO_ 184 550;
BA_ "GenMsgCycleTime" BO_ 185 960;
BA_ "GenMsgCycleTime" BO_ 186 840;
BA_ "GenMsgCycleTime" BO_ 187 220;
BA_ "GenMsgCycleTime" BO_ 188 750;
BA_ "GenMsgCycleTime" BO_ 189 540;
BA_ "GenMsgCycleTime" BO_ 2147549373 870;
BA_ "VFrameFormat" BO_ 2147549373 1;
BA_ "GenMsgCycleTime" BO_ 191 440;
BA_ "GenMsgCycleTime" BO_ 192 420;
BA_ "GenMsgCycleTime" BO_ 193 180;
BA_ "GenMsgCycleTime" BO_ 2147549377 650;
BA_ "VFrameFormat" BO_ 2147549377 1;
BA_ "GenMsgCycleTime" BO_ 195 270;
BA_ "GenMsgCycleTime" BO_ 196 660;
BA_ "GenMsgCycleTime" BO_ 197 990;
BA_ "GenMsgCycleTime" BO_ 198 680;
BA_ "GenMsgCycleTime" BO_ 199 830;
BA_ "GenMsgCycleTime" BO_ 200 80;
BA_ "GenMsgCycleTime" BO_ 201 780;
BA_ "GenMsgCycleTime" BO_ 202 330;
BA_ "GenMsgCycleTime" BO_ 2147549386 980;
BA_ "VFrameFormat" BO_ 2147549386 1;
BA_ "GenMsgCycleTime" BO_ 204 220;
BA_ "GenMsgCycleTime" BO_ 205 130;
BA_ "GenMsgCycleTime" BO_ 206 870;
BA_ "GenMsgCycleTime" BO_ 207 420;
BA_ "GenMsgCycleTime" BO_ 208 190;
BA_ "GenMsgCycleTime" BO_ 209 420;
BA_ "GenMsgCycleTime" BO_ 210 710;
BA_ "GenMsgCycleTime" BO_ 211 370;
BA_ "GenMsgCycleTime" BO_ 212 350;
BA_ "GenMsgCycleTime" BO_ 213 890;
BA_ "GenMsgCycleTime" BO_ 214 840;
BA_ "GenMsgCycleTime" BO_ 2147549398 940;
BA_ "VFrameFormat" BO_ 2147549398 1;
BA_ "GenMsgCycleTime" BO_ 216 790;
BA_ "GenMsgCycleTime" BO_ 217 760;
BA_ "GenMsgCycleTime" BO_ 218 590;
BA_ "GenMsgCycleTime" BO_ 219 640;
BA_ "GenMsgCycleTime" BO_ 220 150;
BA_ "GenMsgCycleTime" BO_ 221 930;
BA_ "GenMsgCycleTime" BO_ 222 190;
BA_ "GenMsgCycleTime" BO_ 2147549406 50;
BA_ "VFrameFormat" BO_ 2147549406 1;
BA_ "GenMsgCycleTime" BO_ 224 500;
BA_ "GenMsgCycleTime" BO_ 225 140;
BA_ "GenMsgCycleTime" BO_ 226 200;
BA_ "GenMsgCycleTime" BO_ 2147549410 610;
BA_ "VFrameFormat" BO_ 2147549410 1;
BA_ "GenMsgCycleTime" BO_ 228 370;
BA_ "GenMsgCycleTime" BO_ 229 910;
BA_ "GenMsgCycleTime" BO_ 230 960;
BA_ "GenMsgCycleTime" BO_ 231 860;
BA_ "GenMsgCycleTime" BO_ 232 530;
BA_ "GenMsgCycleTime" BO_ 233 260;
BA_ "GenMsgCycleTime" BO_ 234 110;
BA_ "GenMsgCycleTime" BO_ 235 280;
BA_ "GenMsgCycleTime" BO_ 236 30;
BA_ "GenMsgCycleTime" BO_ 2147549420 260;
BA_ "VFrameFormat" BO_ 2147549420 1;
BA_ "GenMsgCycleTime" BO_ 238 210;
BA_ "GenMsgCycleTime" BO_ 2147549422 490;
BA_ "VFrameFormat" BO_ 2147549422 1;
BA_ "GenMsgCycleTime" BO_ 240 870;
BA_ "GenMsgCycleTime" BO_ 241 890;
BA_ "GenMsgCycleTime" BO_ 242 590;
BA_ "GenMsgCycleTime" BO_ 243 470;
BA_ "GenMsgCycleTime" BO_ 244 120;
BA_ "GenMsgCycleTime" BO_ 245 420;
BA_ "GenMsgCycleTime" BO_ 246 850;
BA_ "GenMsgCycleTime" BO_ 247 870;
BA_ "GenMsgCycleTime" BO_ 2147549431 520;
BA_ "VFrameFormat" BO_ 2147549431 1;
BA_ "GenMsgCycleTime" BO_ 249 870;
BA_ "GenMsgCycleTime" BO_ 250 370;
BA_ "GenMsgCycleTime" BO_ 251 830;
BA_ "GenMsgCycleTime" BO_ 252 370;
BA_ "GenMsgCycleTime" BO_ 2147549436 420;
BA_ "VFrameFormat" BO_ 2147549436 1;
BA_ "GenMsgCycleTime" BO_ 2147549437 30;
BA_ "VFrameFormat" BO_ 2147549437 1;
BA_ "GenMsgCycleTime" BO_ 2147549438 720;
BA_ "VFrameFormat" BO_ 2147549438 1;
BA_ "GenMsgCycleTime" BO_ 256 90;
BA_ "GenMsgCycleTime" BO_ 257 950;
BA_ "GenMsgCycleTime" BO_ 258 40;
BA_ "GenMsgCycleTime" BO_ 2147549442 530;
BA_ "VFrameFormat" BO_ 2147549442 1;
BA_ "GenMsgCycleTime" BO_ 260 50;
BA_ "GenMsgCycleTime" BO_ 2147549444 170;
BA_ "VFrameFormat" BO_ 2147549444 1;
BA_ "GenMsgCycleTime" BO_ 2147549445 430;
BA_ "VFrameFormat" BO_ 2147549445 1;
BA_ "GenMsgCycleTime" BO_ 2147549446 280;
BA_ "VFrameFormat" BO_ 2147549446 1;
BA_ "GenMsgCycleTime" BO_ 2147549447 20;
BA_ "VFrameFormat" BO_ 2147549447 1;
BA_ "GenMsgCycleTime" BO_ 2147549448 130;
BA_ "VFrameFormat" BO_ 2147549448 1;
BA_ "GenMsgCycleTime" BO_ 2147549449 480;
BA_ "VFrameFormat" BO_ 2147549449 1;
BA_ "GenMsgCycleTime" BO_ 267 1000;
BA_ "GenMsgCycleTime" BO_ 268 580;
BA_ "GenMsgCycleTime" BO_ 269 730;
BA_ "GenMsgCycleTime" BO_ 270 900;
BA_ "GenMsgCycleTime" BO_ 271 950;
BA_ "GenMsgCycleTime" BO_ 272 810;
BA_ "GenMsgCycleTime" BO_ 273 150;
BA_ "GenMsgCycleTime" BO_ 274 380;
BA_ "GenMsgCycleTime" BO_ 275 310;
BA_ "GenMsgCycleTime" BO_ 276 970;
BA_ "GenMsgCycleTime" BO_ 277 390;
BA_ "GenMsgCycleTime" BO_ 278 390;
BA_ "GenMsgCycleTime" BO_ 279 460;
BA_ "GenMsgCycleTime" BO_ 280 140;
BA_ "GenMsgCycleTime" BO_ 281 80;
BA_ "GenMsgCycleTime" BO_ 282 150;
BA_ "GenMsgCycleTime" BO_ 283 260;
BA_ "GenMsgCycleTime" BO_ 2147549467 100;
BA_ "VFrameFormat" BO_ 2147549467 1;
BA_ "GenMsgCycleTime" BO_ 285 380;
BA_ "GenMsgCycleTime" BO_ 286 530;
BA_ "GenMsgCycleTime" BO_ 287 180;
BA_ "GenMsgCycleTime" BO_ 288 710;
BA_ "GenMsgCycleTime" BO_ 289 460;
BA_ "GenMsgCycleTime" BO_ 2147549473 920;
BA_ "VFrameFormat" BO_ 2147549473 1;
BA_ "GenMsgCycleTime" BO_ 291 940;
BA_ "GenMsgCycleTime" BO_ 292 480;
BA_ "GenMsgCycleTime" BO_ 293 820;
BA_ "GenMsgCycleTime" BO_ 294 970;
BA_ "GenMsgCycleTime" BO_ 295 130;
BA_ "GenMsgCycleTime" BO_ 296 300;
BA_ "GenMsgCycleTime" BO_ 297 300;
BA_ "GenMsgCycleTime" BO_ 298 930;
BA_ "GenMsgCycleTime" BO_ 2147549482 980;
BA_ "VFrameFormat" BO_ 2147549482 1;
BA_ "GenMsgCycleTime" BO_ 300 410;
VAL_ 1 Sig_0_0 3 "Fault" 2 "Hold" 1 "Run" 0 "Idle" ;
VAL_ 4 Sig_3_5 3 "Fault" 2 "Hold" 1 "Run" 0 "Idle" ;
VAL_ 5 Sig_4_2 1 "On" 0 "Off" ;
VAL_ 2147549189 Sig_5_0 1 "On" 0 "Off" ;
VAL_ 7 Sig_6_3 3 "Fault" 2 "Hold" 1 "Run" 0 "Idle" ;
VAL_ 7 Sig_6_5 1 "On" 0 "Off" ;
VAL_ 2147549191 Sig_7_4 3 "Fault" 2 "Hold" 1 "Run" 0 "Idle" ;
VAL_ 2147549191 Sig_7_5 3 "Fault" 2 "Hold" 1 "Run" 0 "Idle" ;
VAL_ 11 Sig_10_0 1 "On" 0 "Off" ;
VAL_ 11 Sig_10_4 1 "On" 0 "Off" ;
VAL_ 14 Sig_13_4 1 "On" 0 "Off" ;
VAL_ 16 Sig_15_0 1 "On" 0 "Off" ;
VAL_ 16 Sig_15_1 1 "On" 0 "Off" ;
VAL_ 16 Sig_15_2 3 "Fault" 2 "Hold" 1 "Run" 0 "Idle" ;
VAL_ 17 Sig_16_4 3 "Fault" 2 "Hold" 1 "Run" 0 "Idle" ;
VAL_ 2147549202 Sig_18_0 1 "On" 0 "Off" ;
VAL_ 2147549202 Sig_18_1 1 "On" 0 "Off" ;
VAL_ 20 Sig_19_3 1 "On" 0 "Off" ;
VAL_ 20 Sig_19_5 3 "Fault" 2 "Hold" 1 "Run" 0 "Idle" ;
VAL_ 21 Sig_20_3 3 "Fault" 2 "Hold" 1 "Run" 0 "Idle" ;
VAL_ 23 Sig_22_5 1 "On" 0 "Off" ;
VAL_ 25 Sig_24_0 1 "On" 0 "Off" ;
VAL_ 26 Sig_25_4 1 "On" 0 "Off" ;
VAL_ 28 Sig_27_1 1 "On" 0 "Off" ;
VAL_ 28 Sig_27_2 1 "On" 0 "Off" ;
VAL_ 28 Sig_27_4 3 "Fault" 2 "Hold" 1 "Run" 0 "Idle" ;
VAL_ 29 Sig_28_1 3 "Fault" 2 "Hold" 1 "Run" 0 "Idle" ;
VAL_ 29 Sig_28_4 3 "Fault" 2 "Hold" 1 "Run" 0 "Idle" ;
VAL_ 29 Sig_28_5 1 "On" 0 "Off" ;
VAL_ 30 Sig_29_2 3 "Fault" 2 "Hold" 1 "Run" 0 "Idle" ;
VAL_ 32 Sig_31_3 1 "On" 0 "Off" ;
VAL_ 33 Sig_32_4 1 "On" 0 "Off" ;
VAL_ 37 Sig_36_2 1 "On" 0 "Off" ;
VAL_ 37 Sig_36_4 3 "Fault" 2 "Hold" 1 "Run" 0 "Idle" ;
VAL_ 39 Sig_38_a0 1 "On" 0 "Off" ;
VAL_ 39 Sig_38_c0 3 "Fault" 2 "Hold" 1 "Run" 0 "Idle" ;
VAL_ 40 Sig_39_1 3 "Fault" 2 "Hold" 1 "Run" 0 "Idle" ;
VAL_ 40 Sig_39_4 3 "Fault" 2 "Hold" 1 "Run" 0 "Idle" ;
VAL_ 41 Sig_40_3 1 "On" 0 "Off" ;
VAL_ 2147549228 Sig_44_5 3 "Fault" 2 "Hold" 1 "Run" 0 "Idle" ;
VAL_ 47 Sig_46_2 3 "Fault" 2 "Hold" 1 "Run" 0 "Idle" ;
VAL_ 2147549231 Sig_47_5 3 "Fault" 2 "Hold" 1 "Run" 0 "Idle" ;
VAL_ 51 Sig_50_0 3 "Fault" 2 "Hold" 1 "Run" 0 "Idle" ;
VAL_ 51 Sig_50_1 1 "On" 0 "Off" ;
VAL_ 51 Sig_50_3 1 "On" 0 "Off" ;
VAL_ 51 Sig_50_5 1 "On" 0 "Off" ;
VAL_ 2147549237 Sig_53_3 3 "Fault" 2 "Hold" 1 "Run" 0 "Idle" ;
VAL_ 2147549238 Sig_54_3 1 "On" 0 "Off" ;
VAL_ 2147549238 Sig_54_4 3 "Fault" 2 "Hold" 1 "Run" 0 "Idle" ;
VAL_ 56 Sig_55_3 1 "On" 0 "Off" ;
VAL_ 57 Sig_56_b1 1 "On" 0 "Off" ;
VAL_ 60 Sig_59_3 1 "On" 0 "Off" ;
VAL_ 60 Sig_59_4 3 "Fault" 2 "Hold" 1 "Run" 0 "Idle" ;
VAL_ 61 Sig_60_2 1 "On" 0 "Off" ;
VAL_ 63 Sig_62_4 1 "On" 0 "Off" ;
VAL_ 64 Sig_63_1 3 "Fault" 2 "Hold" 1 "Run" 0 "Idle" ;
VAL_ 68 Sig_67_0 1 "On" 0 "Off" ;
VAL_ 68 Sig_67_1 1 "On" 0 "Off" ;
VAL_ 2147549252 Sig_68_1 3 "Fault" 2 "Hold" 1 "Run" 0 "Idle" ;
VAL_ 71 Sig_70_1 3 "Fault" 2 "Hold" 1 "Run" 0 "Idle" ;
VAL_ 72 Sig_71_4 3 "Fault" 2 "Hold" 1 "Run" 0 "Idle" ;
VAL_ 73 Sig_72_5 3 "Fault" 2 "Hold" 1 "Run" 0 "Idle" ;
VAL_ 74 Sig_73_1 1 "On" 0 "Off" ;
VAL_ 74 Sig_73_3 1 "On" 0 "Off" ;
VAL_ 75 Sig_74_0 1 "On" 0 "Off" ;
VAL_ 75 Sig_74_5 3 "Fault" 2 "Hold" 1 "Run" 0 "Idle" ;
VAL_ 77 Sig_76_b1 1 "On" 0 "Off" ;
VAL_ 79 Sig_78_1 3 "Fault" 2 "Hold" 1 "Run" 0 "Idle" ;
VAL_ 79 Sig_78_3 3 "Fault" 2 "Hold" 1 "Run" 0 "Idle" ;
VAL_ 2147549263 Sig_79_4 3 "Fault" 2 "Hold" 1 "Run" 0 "Idle" ;
VAL_ 2147549264 Sig_80_5 3 "Fault" 2 "Hold" 1 "Run" 0 "Idle" ;
VAL_ 83 Sig_82_0 1 "On" 0 "Off" ;
VAL_ 85 Sig_84_2 3 "Fault" 2 "Hold" 1 "Run" 0 "Idle" ;
VAL_ 88 Sig_87_3 1 "On" 0 "Off" ;
VAL_ 89 Sig_88_a1 3 "Fault" 2 "Hold" 1 "Run" 0 "Idle" ;
VAL_ 91 Sig_90_1 1 "On" 0 "Off" ;
VAL_ 91 Sig_90_4 1 "On" 0 "Off" ;
VAL_ 2147549276 Sig_92_4 3 "Fault" 2 "Hold" 1 "Run" 0 "Idle" ;
VAL_ 2147549277 Sig_93_2 1 "On" 0 "Off" ;
VAL_ 95 Sig_94_c0 3 "Fault" 2 "Hold" 1 "Run" 0 "Idle" ;
VAL_ 98 Sig_97_3 1 "On" 0 "Off" ;
VAL_ 99 Sig_98_1 3 "Fault" 2 "Hold" 1 "Run" 0 "Idle" ;
VAL_ 99 Sig_98_3 3 "Fault" 2 "Hold" 1 "Run" 0 "Idle" ;
VAL_ 101 Sig_100_0 3 "Fault" 2 "Hold" 1 "Run" 0 "Idle" ;
VAL_ 101 Sig_100_3 1 "On" 0 "Off" ;
VAL_ 2147549285 Sig_101_1 3 "Fault" 2 "Hold" 1 "Run" 0 "Idle" ;
VAL_ 2147549285 Sig_101_5 1 "On" 0 "Off" ;
VAL_ 103 Sig_102_1 3 "Fault" 2 "Hold" 1 "Run" 0 "Idle" ;
VAL_ 103 Sig_102_3 1 "On" 0 "Off" ;
VAL_ 107 Sig_106_5 1 "On" 0 "Off" ;
VAL_ 108 Sig_107_2 3 "Fault" 2 "Hold" 1 "Run" 0 "Idle" ;
VAL_ 2147549292 Sig_108_4 1 "On" 0 "Off" ;
VAL_ 111 Sig_110_3 1 "On" 0 "Off" ;
VAL_ 112 Sig_111_2 3 "Fault" 2 "Hold" 1 "Run" 0 "Idle" ;
VAL_ 112 Sig_111_4 1 "On" 0 "Off" ;
VAL_ 113 Sig_112_2 1 "On" 0 "Off" ;
VAL_ 113 Sig_112_4 3 "Fault" 2 "Hold" 1 "Run" 0 "Idle" ;
VAL_ 117 Sig_116_0 3 "Fault" 2 "Hold" 1 "Run" 0 "Idle" ;
VAL_ 120 Sig_119_1 1 "On" 0 "Off" ;
VAL_ 120 Sig_119_5 1 "On" 0 "Off" ;
VAL_ 123 Sig_122_1 1 "On" 0 "Off" ;
VAL_ 123 Sig_122_2 1 "On" 0 "Off" ;
VAL_ 123 Sig_122_5 1 "On" 0 "Off" ;
VAL_ 125 Sig_124_1 3 "Fault" 2 "Hold" 1 "Run" 0 "Idle" ;
VAL_ 125 Sig_124_2 3 "Fault" 2 "Hold" 1 "Run" 0 "Idle" ;
VAL_ 126 Sig_125_a1 1 "On" 0 "Off" ;
VAL_ 127 Sig_126_a0 3 "Fault" 2 "Hold" 1 "Run" 0 "Idle" ;
VAL_ 127 Sig_126_b0 3 "Fault" 2 "Hold" 1 "Run" 0 "Idle" ;
VAL_ 134 Sig_133_3 3 "Fault" 2 "Hold" 1 "Run" 0 "Idle" ;
VAL_ 134 Sig_133_4 3 "Fault" 2 "Hold" 1 "Run" 0 "Idle" ;
VAL_ 135 Sig_134_3 1 "On" 0 "Off" ;
VAL_ 136 Sig_135_3 1 "On" 0 "Off" ;
VAL_ 136 Sig_135_5 3 "Fault" 2 "Hold" 1 "Run" 0 "Idle" ;
VAL_ 140 Sig_139_3 1 "On" 0 "Off" ;
VAL_ 141 Sig_140_0 3 "Fault" 2 "Hold" 1 "Run" 0 "Idle" ;
VAL_ 2147549326 Sig_142_a1 1 "On" 0 "Off" ;
VAL_ 2147549326 Sig_142_b0 3 "Fault" 2 "Hold" 1 "Run" 0 "Idle" ;
VAL_ 144 Sig_143_1 3 "Fault" 2 "Hold" 1 "Run" 0 "Idle" ;
VAL_ 146 Sig_145_1 1 "On" 0 "Off" ;
VAL_ 147 Sig_146_c0 3 "Fault" 2 "Hold" 1 "Run" 0 "Idle" ;
VAL_ 148 Sig_147_1 3 "Fault" 2 "Hold" 1 "Run" 0 "Idle" ;
VAL_ 152 Sig_151_4 1 "On" 0 "Off" ;
VAL_ 154 Sig_153_0 1 "On" 0 "Off" ;
VAL_ 155 Sig_154_1 3 "Fault" 2 "Hold" 1 "Run" 0 "Idle" ;
VAL_ 156 Sig_155_0 3 "Fault" 2 "Hold" 1 "Run" 0 "Idle" ;
VAL_ 156 Sig_155_5 1 "On" 0 "Off" ;
VAL_ 158 Sig_157_2 1 "On" 0 "Off" ;
VAL_ 158 Sig_157_4 1 "On" 0 "Off" ;
VAL_ 159 Sig_158_1 3 "Fault" 2 "Hold" 1 "Run" 0 "Idle" ;
VAL_ 160 Sig_159_1 3 "Fault" 2 "Hold" 1 "Run" 0 "Idle" ;
VAL_ 160 Sig_159_3 3 "Fault" 2 "Hold" 1 "Run" 0 "Idle" ;
VAL_ 160 Sig_159_4 1 "On" 0 "Off" ;
VAL_ 2147549348 Sig_164_4 1 "On" 0 "Off" ;
VAL_ 168 Sig_167_0 1 "On" 0 "Off" ;
VAL_ 169 Sig_168_0 1 "On" 0 "Off" ;
VAL_ 169 Sig_168_2 3 "Fault" 2 "Hold" 1 "Run" 0 "Idle" ;
VAL_ 170 Sig_169_3 1 "On" 0 "Off" ;
VAL_ 171 Sig_170_2 3 "Fault" 2 "Hold" 1 "Run" 0 "Idle" ;
VAL_ 172 Sig_171_0 3 "Fault" 2 "Hold" 1 "Run" 0 "Idle" ;
VAL_ 174 Sig_173_1 1 "On" 0 "Off" ;
VAL_ 175 Sig_174_0 1 "On" 0 "Off" ;
VAL_ 178 Sig_177_2 1 "On" 0 "Off" ;
VAL_ 178 Sig_177_5 1 "On" 0 "Off" ;
VAL_ 179 Sig_178_5 1 "On" 0 "Off" ;
VAL_ 181 Sig_180_1 1 "On" 0 "Off" ;
VAL_ 183 Sig_182_1 1 "On" 0 "Off" ;
VAL_ 184 Sig_183_b0 1 "On" 0 "Off" ;
VAL_ 184 Sig_183_c0 1 "On" 0 "Off" ;
VAL_ 185 Sig_184_2 3 "Fault" 2 "Hold" 1 "Run" 0 "Idle" ;
VAL_ 185 Sig_184_3 1 "On" 0 "Off" ;
VAL_ 187 Sig_186_5 3 "Fault" 2 "Hold" 1 "Run" 0 "Idle" ;
VAL_ 189 Sig_188_4 3 "Fault" 2 "Hold" 1 "Run" 0 "Idle" ;
VAL_ 2147549377 Sig_193_3 1 "On" 0 "Off" ;
VAL_ 2147549377 Sig_193_5 3 "Fault" 2 "Hold" 1 "Run" 0 "Idle" ;
VAL_ 197 Sig_196_4 3 "Fault" 2 "Hold" 1 "Run" 0 "Idle" ;
VAL_ 198 Sig_197_1 1 "On" 0 "Off" ;
VAL_ 198 Sig_197_5 3 "Fault" 2 "Hold" 1 "Run" 0 "Idle" ;
VAL_ 199 Sig_198_b1 1 "On" 0 "Off" ;
VAL_ 201 Sig_200_1 1 "On" 0 "Off" ;
VAL_ 202 Sig_201_1 3 "Fault" 2 "Hold" 1 "Run" 0 "Idle" ;
VAL_ 2147549386 Sig_202_1 3 "Fault" 2 "Hold" 1 "Run" 0 "Idle" ;
VAL_ 2147549386 Sig_202_2 1 "On" 0 "Off" ;
VAL_ 2147549386 Sig_202_4 3 "Fault" 2 "Hold" 1 "Run" 0 "Idle" ;
VAL_ 2147549386 Sig_202_5 3 "Fault" 2 "Hold" 1 "Run" 0 "Idle" ;
VAL_ 204 Sig_203_0 1 "On" 0 "Off" ;
VAL_ 204 Sig_203_2 1 "On" 0 "Off" ;
VAL_ 206 Sig_205_4 1 "On" 0 "Off" ;
VAL_ 207 Sig_206_a1 1 "On" 0 "Off" ;
VAL_ 207 Sig_206_c1 3 "Fault" 2 "Hold" 1 "Run" 0 "Idle" ;
VAL_ 208 Sig_207_4 1 "On" 0 "Off" ;
VAL_ 213 Sig_212_0 1 "On" 0 "Off" ;
VAL_ 213 Sig_212_3 1 "On" 0 "Off" ;
VAL_ 214 Sig_213_a1 1 "On" 0 "Off" ;
VAL_ 214 Sig_213_b1 1 "On" 0 "Off" ;
VAL_ 2147549398 Sig_214_b0 1 "On" 0 "Off" ;
VAL_ 217 Sig_216_4 1 "On" 0 "Off" ;
VAL_ 218 Sig_217_2 1 "On" 0 "Off" ;
VAL_ 219 Sig_218_3 1 "On" 0 "Off" ;
VAL_ 222 Sig_221_b1 3 "Fault" 2 "Hold" 1 "Run" 0 "Idle" ;
VAL_ 2147549406 Sig_222_1 1 "On" 0 "Off" ;
VAL_ 230 Sig_229_2 3 "Fault" 2 "Hold" 1 "Run" 0 "Idle" ;
VAL_ 231 Sig_230_2 3 "Fault" 2 "Hold" 1 "Run" 0 "Idle" ;
VAL_ 232 Sig_231_2 3 "Fault" 2 "Hold" 1 "Run" 0 "Idle" ;
VAL_ 232 Sig_231_3 3 "Fault" 2 "Hold" 1 "Run" 0 "Idle" ;
VAL_ 235 Sig_234_3 1 "On" 0 "Off" ;
VAL_ 236 Sig_235_2 3 "Fault" 2 "Hold" 1 "Run" 0 "Idle" ;
VAL_ 2147549420 Sig_236_0 1 "On" 0 "Off" ;
VAL_ 242 Sig_241_1 1 "On" 0 "Off" ;
VAL_ 242 Sig_241_2 3 "Fault" 2 "Hold" 1 "Run" 0 "Idle" ;
VAL_ 243 Sig_242_0 3 "Fault" 2 "Hold" 1 "Run" 0 "Idle" ;
VAL_ 246 Sig_245_1 3 "Fault" 2 "Hold" 1 "Run" 0 "Idle" ;
VAL_ 246 Sig_245_3 3 "Fault" 2 "Hold" 1 "Run" 0 "Idle" ;
VAL_ 247 Sig_246_1 3 "Fault" 2 "Hold" 1 "Run" 0 "Idle" ;
VAL_ 2147549431 Sig_247_4 3 "Fault" 2 "Hold" 1 "Run" 0 "Idle" ;
VAL_ 251 Sig_250_4 1 "On" 0 "Off" ;
VAL_ 251 Sig_250_5 1 "On" 0 "Off" ;
VAL_ 252 Sig_251_a1 1 "On" 0 "Off" ;
VAL_ 252 Sig_251_b0 3 "Fault" 2 "Hold" 1 "Run" 0 "Idle" ;
VAL_ 252 Sig_251_c0 3 "Fault" 2 "Hold" 1 "Run" 0 "Idle" ;
VAL_ 2147549436 Sig_252_1 1 "On" 0 "Off" ;
VAL_ 2147549437 Sig_253_5 1 "On" 0 "Off" ;
VAL_ 256 Sig_255_1 1 "On" 0 "Off" ;
VAL_ 258 Sig_257_5 1 "On" 0 "Off" ;
VAL_ 260 Sig_259_5 3 "Fault" 2 "Hold" 1 "Run" 0 "Idle" ;
VAL_ 2147549446 Sig_262_4 3 "Fault" 2 "Hold" 1 "Run" 0 "Idle" ;
VAL_ 2147549448 Sig_264_5 3 "Fault" 2 "Hold" 1 "Run" 0 "Idle" ;
VAL_ 2147549449 Sig_265_1 1 "On" 0 "Off" ;
VAL_ 2147549449 Sig_265_2 3 "Fault" 2 "Hold" 1 "Run" 0 "Idle" ;
VAL_ 271 Sig_270_5 3 "Fault" 2 "Hold" 1 "Run" 0 "Idle" ;
VAL_ 274 Sig_273_0 1 "On" 0 "Off" ;
VAL_ 275 Sig_274_2 1 "On" 0 "Off" ;
VAL_ 275 Sig_274_5 1 "On" 0 "Off" ;
VAL_ 276 Sig_275_3 3 "Fault" 2 "Hold" 1 "Run" 0 "Idle" ;
VAL_ 276 Sig_275_5 3 "Fault" 2 "Hold" 1 "Run" 0 "Idle" ;
VAL_ 277 Sig_276_1 1 "On" 0 "Off" ;
VAL_ 278 Sig_277_1 1 "On" 0 "Off" ;
VAL_ 279 Sig_278_0 3 "Fault" 2 "Hold" 1 "Run" 0 "Idle" ;
VAL_ 279 Sig_278_1 3 "Fault" 2 "Hold" 1 "Run" 0 "Idle" ;
VAL_ 279 Sig_278_2 1 "On" 0 "Off" ;
VAL_ 280 Sig_279_0 3 "Fault" 2 "Hold" 1 "Run" 0 "Idle" ;
VAL_ 280 Sig_279_2 1 "On" 0 "Off" ;
VAL_ 281 Sig_280_4 1 "On" 0 "Off" ;
VAL_ 283 Sig_282_0 1 "On" 0 "Off" ;
VAL_ 283 Sig_282_5 1 "On" 0 "Off" ;
VAL_ 2147549467 Sig_283_0 1 "On" 0 "Off" ;
VAL_ 2147549467 Sig_283_5 1 "On" 0 "Off" ;
VAL_ 285 Sig_284_1 1 "On" 0 "Off" ;
VAL_ 287 Sig_286_2 3 "Fault" 2 "Hold" 1 "Run" 0 "Idle" ;
VAL_ 291 Sig_290_5 1 "On" 0 "Off" ;
VAL_ 292 Sig_291_0 3 "Fault" 2 "Hold" 1 "Run" 0 "Idle" ;
VAL_ 295 Sig_294_2 1 "On" 0 "Off" ;
VAL_ 296 Sig_295_2 3 "Fault" 2 "Hold" 1 "Run" 0 "Idle" ;
VAL_ 297 Sig_296_5 1 "On" 0 "Off" ;
VAL_ 298 Sig_297_a0 3 "Fault" 2 "Hold" 1 "Run" 0 "Idle" ;
VAL_ 300 Sig_299_0 1 "On" 0 "Off" ;
